VERSION ""

NS_ :

BS_:
BU_: ME SC01 BMS01 BMS PT
BO_ 1988 BMS05_DebugCMB: 8 BMS05
 SG_ cmbMultiplexor_BMS05 M : 7|8@0+ (1,0) [0|0] ""  PT
 SG_ moduleTemperature01_BMS05 m1 : 15|8@0+ (1,-40) [-40|200] "C"  PT
 SG_ brickVoltage001_BMS05 m1 : 23|16@0+ (0.0001,0) [0|6.5] "V"  PT
 SG_ brickVoltage002_BMS05 m1 : 39|16@0+ (0.0001,0) [0|6.5] "V"  PT
 SG_ brickVoltage003_BMS05 m1 : 55|16@0+ (0.0001,0) [0|6.5] "V"  PT
 SG_ moduleTemperature02_BMS05 m2 : 15|8@0+ (1,-40) [-40|200] "C"  PT
 SG_ brickVoltage004_BMS05 m2 : 23|16@0+ (0.0001,0) [0|6.5] "V"  PT
 SG_ brickVoltage005_BMS05 m2 : 39|16@0+ (0.0001,0) [0|6.5] "V"  PT
 SG_ brickVoltage006_BMS05 m2 : 55|16@0+ (0.0001,0) [0|6.5] "V"  PT
 SG_ moduleTemperature03_BMS05 m3 : 15|8@0+ (1,-40) [-40|200] "C"  PT
 SG_ brickVoltage007_BMS05 m3 : 23|16@0+ (0.0001,0) [0|6.5] "V"  PT
 SG_ brickVoltage008_BMS05 m3 : 39|16@0+ (0.0001,0) [0|6.5] "V"  PT
 SG_ brickVoltage009_BMS05 m3 : 55|16@0+ (0.0001,0) [0|6.5] "V"  PT
 SG_ moduleTemperature04_BMS05 m4 : 15|8@0+ (1,-40) [-40|200] "C"  PT
 SG_ brickVoltage010_BMS05 m4 : 23|16@0+ (0.0001,0) [0|6.5] "V"  PT
 SG_ brickVoltage011_BMS05 m4 : 39|16@0+ (0.0001,0) [0|6.5] "V"  PT
 SG_ brickVoltage012_BMS05 m4 : 55|16@0+ (0.0001,0) [0|6.5] "V"  PT
 SG_ moduleTemperature05_BMS05 m5 : 15|8@0+ (1,-40) [-40|200] "C"  PT
 SG_ brickVoltage013_BMS05 m5 : 23|16@0+ (0.0001,0) [0|6.5] "V"  PT
 SG_ brickVoltage014_BMS05 m5 : 39|16@0+ (0.0001,0) [0|6.5] "V"  PT
 SG_ brickVoltage015_BMS05 m5 : 55|16@0+ (0.0001,0) [0|6.5] "V"  PT
 SG_ moduleTemperature06_BMS05 m6 : 15|8@0+ (1,-40) [-40|200] "C"  PT
 SG_ brickVoltage016_BMS05 m6 : 23|16@0+ (0.0001,0) [0|6.5] "V"  PT
 SG_ brickVoltage017_BMS05 m6 : 39|16@0+ (0.0001,0) [0|6.5] "V"  PT
 SG_ brickVoltage018_BMS05 m6 : 55|16@0+ (0.0001,0) [0|6.5] "V"  PT
 SG_ moduleTemperature07_BMS05 m7 : 15|8@0+ (1,-40) [-40|200] "C"  PT
 SG_ brickVoltage019_BMS05 m7 : 23|16@0+ (0.0001,0) [0|6.5] "V"  PT
 SG_ brickVoltage020_BMS05 m7 : 39|16@0+ (0.0001,0) [0|6.5] "V"  PT
 SG_ brickVoltage021_BMS05 m7 : 55|16@0+ (0.0001,0) [0|6.5] "V"  PT
 SG_ moduleTemperature08_BMS05 m8 : 15|8@0+ (1,-40) [-40|200] "C"  PT
 SG_ brickVoltage022_BMS05 m8 : 23|16@0+ (0.0001,0) [0|6.5] "V"  PT
 SG_ brickVoltage023_BMS05 m8 : 39|16@0+ (0.0001,0) [0|6.5] "V"  PT
 SG_ brickVoltage024_BMS05 m8 : 55|16@0+ (0.0001,0) [0|6.5] "V"  PT
 SG_ moduleTemperature09_BMS05 m9 : 15|8@0+ (1,-40) [-40|200] "C"  PT
 SG_ brickVoltage025_BMS05 m9 : 23|16@0+ (0.0001,0) [0|6.5] "V"  PT
 SG_ brickVoltage026_BMS05 m9 : 39|16@0+ (0.0001,0) [0|6.5] "V"  PT
 SG_ brickVoltage027_BMS05 m9 : 55|16@0+ (0.0001,0) [0|6.5] "V"  PT
 SG_ moduleTemperature10_BMS05 m10 : 15|8@0+ (1,-40) [-40|200] "C"  PT
 SG_ brickVoltage028_BMS05 m10 : 23|16@0+ (0.0001,0) [0|6.5] "V"  PT
 SG_ brickVoltage029_BMS05 m10 : 39|16@0+ (0.0001,0) [0|6.5] "V"  PT
 SG_ brickVoltage030_BMS05 m10 : 55|16@0+ (0.0001,0) [0|6.5] "V"  PT
 SG_ moduleTemperature11_BMS05 m11 : 15|8@0+ (1,-40) [-40|200] "C"  PT
 SG_ brickVoltage031_BMS05 m11 : 23|16@0+ (0.0001,0) [0|6.5] "V"  PT
 SG_ brickVoltage032_BMS05 m11 : 39|16@0+ (0.0001,0) [0|6.5] "V"  PT
 SG_ brickVoltage033_BMS05 m11 : 55|16@0+ (0.0001,0) [0|6.5] "V"  PT
 SG_ moduleTemperature12_BMS05 m12 : 15|8@0+ (1,-40) [-40|200] "C"  PT
 SG_ brickVoltage034_BMS05 m12 : 23|16@0+ (0.0001,0) [0|6.5] "V"  PT
 SG_ brickVoltage035_BMS05 m12 : 39|16@0+ (0.0001,0) [0|6.5] "V"  PT
 SG_ brickVoltage036_BMS05 m12 : 55|16@0+ (0.0001,0) [0|6.5] "V"  PT
 SG_ moduleTemperature13_BMS05 m13 : 15|8@0+ (1,-40) [-40|200] "C"  PT
 SG_ brickVoltage037_BMS05 m13 : 23|16@0+ (0.0001,0) [0|6.5] "V"  PT
 SG_ brickVoltage038_BMS05 m13 : 39|16@0+ (0.0001,0) [0|6.5] "V"  PT
 SG_ brickVoltage039_BMS05 m13 : 55|16@0+ (0.0001,0) [0|6.5] "V"  PT
 SG_ moduleTemperature14_BMS05 m14 : 15|8@0+ (1,-40) [-40|200] "C"  PT
 SG_ brickVoltage040_BMS05 m14 : 23|16@0+ (0.0001,0) [0|6.5] "V"  PT
 SG_ brickVoltage041_BMS05 m14 : 39|16@0+ (0.0001,0) [0|6.5] "V"  PT
 SG_ brickVoltage042_BMS05 m14 : 55|16@0+ (0.0001,0) [0|6.5] "V"  PT
 SG_ moduleTemperature15_BMS05 m15 : 15|8@0+ (1,-40) [-40|200] "C"  PT
 SG_ brickVoltage043_BMS05 m15 : 23|16@0+ (0.0001,0) [0|6.5] "V"  PT
 SG_ brickVoltage044_BMS05 m15 : 39|16@0+ (0.0001,0) [0|6.5] "V"  PT
 SG_ brickVoltage045_BMS05 m15 : 55|16@0+ (0.0001,0) [0|6.5] "V"  PT
 SG_ moduleTemperature16_BMS05 m16 : 15|8@0+ (1,-40) [-40|200] "C"  PT
 SG_ brickVoltage046_BMS05 m16 : 23|16@0+ (0.0001,0) [0|6.5] "V"  PT
 SG_ brickVoltage047_BMS05 m16 : 39|16@0+ (0.0001,0) [0|6.5] "V"  PT
 SG_ brickVoltage048_BMS05 m16 : 55|16@0+ (0.0001,0) [0|6.5] "V"  PT
 SG_ moduleTemperature17_BMS05 m17 : 15|8@0+ (1,-40) [-40|200] "C"  PT
 SG_ brickVoltage049_BMS05 m17 : 23|16@0+ (0.0001,0) [0|6.5] "V"  PT
 SG_ brickVoltage050_BMS05 m17 : 39|16@0+ (0.0001,0) [0|6.5] "V"  PT
 SG_ brickVoltage051_BMS05 m17 : 55|16@0+ (0.0001,0) [0|6.5] "V"  PT
 SG_ moduleTemperature18_BMS05 m18 : 15|8@0+ (1,-40) [-40|200] "C"  PT
 SG_ brickVoltage052_BMS05 m18 : 23|16@0+ (0.0001,0) [0|6.5] "V"  PT
 SG_ brickVoltage053_BMS05 m18 : 39|16@0+ (0.0001,0) [0|6.5] "V"  PT
 SG_ brickVoltage054_BMS05 m18 : 55|16@0+ (0.0001,0) [0|6.5] "V"  PT
 SG_ moduleTemperature19_BMS05 m19 : 15|8@0+ (1,-40) [-40|200] "C"  PT
 SG_ brickVoltage055_BMS05 m19 : 23|16@0+ (0.0001,0) [0|6.5] "V"  PT
 SG_ brickVoltage056_BMS05 m19 : 39|16@0+ (0.0001,0) [0|6.5] "V"  PT
 SG_ brickVoltage057_BMS05 m19 : 55|16@0+ (0.0001,0) [0|6.5] "V"  PT
 SG_ moduleTemperature20_BMS05 m20 : 15|8@0+ (1,-40) [-40|200] "C"  PT
 SG_ brickVoltage058_BMS05 m20 : 23|16@0+ (0.0001,0) [0|6.5] "V"  PT
 SG_ brickVoltage059_BMS05 m20 : 39|16@0+ (0.0001,0) [0|6.5] "V"  PT
 SG_ brickVoltage060_BMS05 m20 : 55|16@0+ (0.0001,0) [0|6.5] "V"  PT
 SG_ moduleTemperature21_BMS05 m21 : 15|8@0+ (1,-40) [-40|200] "C"  PT
 SG_ brickVoltage061_BMS05 m21 : 23|16@0+ (0.0001,0) [0|6.5] "V"  PT
 SG_ brickVoltage062_BMS05 m21 : 39|16@0+ (0.0001,0) [0|6.5] "V"  PT
 SG_ brickVoltage063_BMS05 m21 : 55|16@0+ (0.0001,0) [0|6.5] "V"  PT
 SG_ moduleTemperature22_BMS05 m22 : 15|8@0+ (1,-40) [-40|200] "C"  PT
 SG_ brickVoltage064_BMS05 m22 : 23|16@0+ (0.0001,0) [0|6.5] "V"  PT
 SG_ brickVoltage065_BMS05 m22 : 39|16@0+ (0.0001,0) [0|6.5] "V"  PT
 SG_ brickVoltage066_BMS05 m22 : 55|16@0+ (0.0001,0) [0|6.5] "V"  PT
 SG_ moduleTemperature23_BMS05 m23 : 15|8@0+ (1,-40) [-40|200] "C"  PT
 SG_ brickVoltage067_BMS05 m23 : 23|16@0+ (0.0001,0) [0|6.5] "V"  PT
 SG_ brickVoltage068_BMS05 m23 : 39|16@0+ (0.0001,0) [0|6.5] "V"  PT
 SG_ brickVoltage069_BMS05 m23 : 55|16@0+ (0.0001,0) [0|6.5] "V"  PT
 SG_ moduleTemperature24_BMS05 m24 : 15|8@0+ (1,-40) [-40|200] "C"  PT
 SG_ brickVoltage070_BMS05 m24 : 23|16@0+ (0.0001,0) [0|6.5] "V"  PT
 SG_ brickVoltage071_BMS05 m24 : 39|16@0+ (0.0001,0) [0|6.5] "V"  PT
 SG_ brickVoltage072_BMS05 m24 : 55|16@0+ (0.0001,0) [0|6.5] "V"  PT
 SG_ moduleTemperature25_BMS05 m25 : 15|8@0+ (1,-40) [-40|200] "C"  PT
 SG_ brickVoltage073_BMS05 m25 : 23|16@0+ (0.0001,0) [0|6.5] "V"  PT
 SG_ brickVoltage074_BMS05 m25 : 39|16@0+ (0.0001,0) [0|6.5] "V"  PT
 SG_ brickVoltage075_BMS05 m25 : 55|16@0+ (0.0001,0) [0|6.5] "V"  PT
 SG_ moduleTemperature26_BMS05 m26 : 15|8@0+ (1,-40) [-40|200] "C"  PT
 SG_ brickVoltage076_BMS05 m26 : 23|16@0+ (0.0001,0) [0|6.5] "V"  PT
 SG_ brickVoltage077_BMS05 m26 : 39|16@0+ (0.0001,0) [0|6.5] "V"  PT
 SG_ brickVoltage078_BMS05 m26 : 55|16@0+ (0.0001,0) [0|6.5] "V"  PT
 SG_ moduleTemperature27_BMS05 m27 : 15|8@0+ (1,-40) [-40|200] "C"  PT
 SG_ brickVoltage079_BMS05 m27 : 23|16@0+ (0.0001,0) [0|6.5] "V"  PT
 SG_ brickVoltage080_BMS05 m27 : 39|16@0+ (0.0001,0) [0|6.5] "V"  PT
 SG_ brickVoltage081_BMS05 m27 : 55|16@0+ (0.0001,0) [0|6.5] "V"  PT
 SG_ moduleTemperature28_BMS05 m28 : 15|8@0+ (1,-40) [-40|200] "C"  PT
 SG_ brickVoltage082_BMS05 m28 : 23|16@0+ (0.0001,0) [0|6.5] "V"  PT
 SG_ brickVoltage083_BMS05 m28 : 39|16@0+ (0.0001,0) [0|6.5] "V"  PT
 SG_ brickVoltage084_BMS05 m28 : 55|16@0+ (0.0001,0) [0|6.5] "V"  PT
 SG_ moduleTemperature29_BMS05 m29 : 15|8@0+ (1,-40) [-40|200] "C"  PT
 SG_ brickVoltage085_BMS05 m29 : 23|16@0+ (0.0001,0) [0|6.5] "V"  PT
 SG_ brickVoltage086_BMS05 m29 : 39|16@0+ (0.0001,0) [0|6.5] "V"  PT
 SG_ brickVoltage087_BMS05 m29 : 55|16@0+ (0.0001,0) [0|6.5] "V"  PT
 SG_ moduleTemperature30_BMS05 m30 : 15|8@0+ (1,-40) [-40|200] "C"  PT
 SG_ brickVoltage088_BMS05 m30 : 23|16@0+ (0.0001,0) [0|6.5] "V"  PT
 SG_ brickVoltage089_BMS05 m30 : 39|16@0+ (0.0001,0) [0|6.5] "V"  PT
 SG_ brickVoltage090_BMS05 m30 : 55|16@0+ (0.0001,0) [0|6.5] "V"  PT
 SG_ moduleTemperature31_BMS05 m31 : 15|8@0+ (1,-40) [-40|200] "C"  PT
 SG_ brickVoltage091_BMS05 m31 : 23|16@0+ (0.0001,0) [0|6.5] "V"  PT
 SG_ brickVoltage092_BMS05 m31 : 39|16@0+ (0.0001,0) [0|6.5] "V"  PT
 SG_ brickVoltage093_BMS05 m31 : 55|16@0+ (0.0001,0) [0|6.5] "V"  PT
 SG_ moduleTemperature32_BMS05 m32 : 15|8@0+ (1,-40) [-40|200] "C"  PT
 SG_ brickVoltage094_BMS05 m32 : 23|16@0+ (0.0001,0) [0|6.5] "V"  PT
 SG_ brickVoltage095_BMS05 m32 : 39|16@0+ (0.0001,0) [0|6.5] "V"  PT
 SG_ brickVoltage096_BMS05 m32 : 55|16@0+ (0.0001,0) [0|6.5] "V"  PT
 SG_ brickVoltage097_BMS05 m33 : 23|16@0+ (0.0001,0) [0|6.5] "V"  PT
 SG_ brickVoltage098_BMS05 m33 : 39|16@0+ (0.0001,0) [0|6.5] "V"  PT
 SG_ brickVoltage099_BMS05 m33 : 55|16@0+ (0.0001,0) [0|6.5] "V"  PT
 SG_ brickVoltage100_BMS05 m34 : 23|16@0+ (0.0001,0) [0|6.5] "V"  PT
 SG_ brickVoltage101_BMS05 m34 : 39|16@0+ (0.0001,0) [0|6.5] "V"  PT
 SG_ brickVoltage102_BMS05 m34 : 55|16@0+ (0.0001,0) [0|6.5] "V"  PT
 SG_ brickVoltage103_BMS05 m35 : 23|16@0+ (0.0001,0) [0|6.5] "V"  PT
 SG_ brickVoltage104_BMS05 m35 : 39|16@0+ (0.0001,0) [0|6.5] "V"  PT
 SG_ brickVoltage105_BMS05 m35 : 55|16@0+ (0.0001,0) [0|6.5] "V"  PT
 SG_ brickVoltage106_BMS05 m36 : 23|16@0+ (0.0001,0) [0|6.5] "V"  PT
 SG_ brickVoltage107_BMS05 m36 : 39|16@0+ (0.0001,0) [0|6.5] "V"  PT
 SG_ brickVoltage108_BMS05 m36 : 55|16@0+ (0.0001,0) [0|6.5] "V"  PT
 SG_ brickVoltage109_BMS05 m37 : 23|16@0+ (0.0001,0) [0|6.5] "V"  PT
 SG_ brickVoltage110_BMS05 m37 : 39|16@0+ (0.0001,0) [0|6.5] "V"  PT
 SG_ brickVoltage111_BMS05 m37 : 55|16@0+ (0.0001,0) [0|6.5] "V"  PT
 SG_ brickVoltage112_BMS05 m38 : 23|16@0+ (0.0001,0) [0|6.5] "V"  PT
 SG_ brickVoltage113_BMS05 m38 : 39|16@0+ (0.0001,0) [0|6.5] "V"  PT
 SG_ brickVoltage114_BMS05 m38 : 55|16@0+ (0.0001,0) [0|6.5] "V"  PT
 SG_ brickVoltage115_BMS05 m39 : 23|16@0+ (0.0001,0) [0|6.5] "V"  PT
 SG_ brickVoltage116_BMS05 m39 : 39|16@0+ (0.0001,0) [0|6.5] "V"  PT
 SG_ brickVoltage117_BMS05 m39 : 55|16@0+ (0.0001,0) [0|6.5] "V"  PT
 SG_ brickVoltage118_BMS05 m40 : 23|16@0+ (0.0001,0) [0|6.5] "V"  PT
 SG_ brickVoltage119_BMS05 m40 : 39|16@0+ (0.0001,0) [0|6.5] "V"  PT
 SG_ brickVoltage120_BMS05 m40 : 55|16@0+ (0.0001,0) [0|6.5] "V"  PT
 SG_ brickVoltage121_BMS05 m41 : 23|16@0+ (0.0001,0) [0|6.5] "V"  PT
 SG_ brickVoltage122_BMS05 m41 : 39|16@0+ (0.0001,0) [0|6.5] "V"  PT
 SG_ brickVoltage123_BMS05 m41 : 55|16@0+ (0.0001,0) [0|6.5] "V"  PT
 SG_ brickVoltage124_BMS05 m42 : 23|16@0+ (0.0001,0) [0|6.5] "V"  PT
 SG_ brickVoltage125_BMS05 m42 : 39|16@0+ (0.0001,0) [0|6.5] "V"  PT
 SG_ brickVoltage126_BMS05 m42 : 55|16@0+ (0.0001,0) [0|6.5] "V"  PT
 SG_ brickVoltage127_BMS05 m43 : 23|16@0+ (0.0001,0) [0|6.5] "V"  PT
 SG_ brickVoltage128_BMS05 m43 : 39|16@0+ (0.0001,0) [0|6.5] "V"  PT
 SG_ brickVoltage129_BMS05 m43 : 55|16@0+ (0.0001,0) [0|6.5] "V"  PT
 SG_ brickVoltage130_BMS05 m44 : 23|16@0+ (0.0001,0) [0|6.5] "V"  PT
 SG_ brickVoltage131_BMS05 m44 : 39|16@0+ (0.0001,0) [0|6.5] "V"  PT
 SG_ brickVoltage132_BMS05 m44 : 55|16@0+ (0.0001,0) [0|6.5] "V"  PT
 SG_ brickVoltage133_BMS05 m45 : 23|16@0+ (0.0001,0) [0|6.5] "V"  PT
 SG_ brickVoltage134_BMS05 m45 : 39|16@0+ (0.0001,0) [0|6.5] "V"  PT
 SG_ brickVoltage135_BMS05 m45 : 55|16@0+ (0.0001,0) [0|6.5] "V"  PT
 SG_ brickVoltage136_BMS05 m46 : 23|16@0+ (0.0001,0) [0|6.5] "V"  PT
 SG_ brickVoltage137_BMS05 m46 : 39|16@0+ (0.0001,0) [0|6.5] "V"  PT
 SG_ brickVoltage138_BMS05 m46 : 55|16@0+ (0.0001,0) [0|6.5] "V"  PT
 SG_ brickVoltage139_BMS05 m47 : 23|16@0+ (0.0001,0) [0|6.5] "V"  PT
 SG_ brickVoltage140_BMS05 m47 : 39|16@0+ (0.0001,0) [0|6.5] "V"  PT
 SG_ brickVoltage141_BMS05 m47 : 55|16@0+ (0.0001,0) [0|6.5] "V"  PT
 SG_ brickVoltage142_BMS05 m48 : 23|16@0+ (0.0001,0) [0|6.5] "V"  PT
 SG_ brickVoltage143_BMS05 m48 : 39|16@0+ (0.0001,0) [0|6.5] "V"  PT
 SG_ brickVoltage144_BMS05 m48 : 55|16@0+ (0.0001,0) [0|6.5] "V"  PT
 SG_ brickVoltage145_BMS05 m49 : 23|16@0+ (0.0001,0) [0|6.5] "V"  PT
 SG_ brickVoltage146_BMS05 m49 : 39|16@0+ (0.0001,0) [0|6.5] "V"  PT
 SG_ brickVoltage147_BMS05 m49 : 55|16@0+ (0.0001,0) [0|6.5] "V"  PT
 SG_ brickVoltage148_BMS05 m50 : 23|16@0+ (0.0001,0) [0|6.5] "V"  PT
 SG_ brickVoltage149_BMS05 m50 : 39|16@0+ (0.0001,0) [0|6.5] "V"  PT
 SG_ brickVoltage150_BMS05 m50 : 55|16@0+ (0.0001,0) [0|6.5] "V"  PT
 SG_ brickVoltage151_BMS05 m51 : 23|16@0+ (0.0001,0) [0|6.5] "V"  PT
 SG_ brickVoltage152_BMS05 m51 : 39|16@0+ (0.0001,0) [0|6.5] "V"  PT
 SG_ brickVoltage153_BMS05 m51 : 55|16@0+ (0.0001,0) [0|6.5] "V"  PT
 SG_ brickVoltage154_BMS05 m52 : 23|16@0+ (0.0001,0) [0|6.5] "V"  PT
 SG_ brickVoltage155_BMS05 m52 : 39|16@0+ (0.0001,0) [0|6.5] "V"  PT
 SG_ brickVoltage156_BMS05 m52 : 55|16@0+ (0.0001,0) [0|6.5] "V"  PT
 SG_ brickVoltage157_BMS05 m53 : 23|16@0+ (0.0001,0) [0|6.5] "V"  PT
 SG_ brickVoltage158_BMS05 m53 : 39|16@0+ (0.0001,0) [0|6.5] "V"  PT
 SG_ brickVoltage159_BMS05 m53 : 55|16@0+ (0.0001,0) [0|6.5] "V"  PT
 SG_ brickVoltage160_BMS05 m54 : 23|16@0+ (0.0001,0) [0|6.5] "V"  PT
 SG_ brickVoltage161_BMS05 m54 : 39|16@0+ (0.0001,0) [0|6.5] "V"  PT
 SG_ brickVoltage162_BMS05 m54 : 55|16@0+ (0.0001,0) [0|6.5] "V"  PT
 SG_ brickVoltage163_BMS05 m55 : 23|16@0+ (0.0001,0) [0|6.5] "V"  PT
 SG_ brickVoltage164_BMS05 m55 : 39|16@0+ (0.0001,0) [0|6.5] "V"  PT
 SG_ brickVoltage165_BMS05 m55 : 55|16@0+ (0.0001,0) [0|6.5] "V"  PT
 SG_ brickVoltage166_BMS05 m56 : 23|16@0+ (0.0001,0) [0|6.5] "V"  PT
 SG_ brickVoltage167_BMS05 m56 : 39|16@0+ (0.0001,0) [0|6.5] "V"  PT
 SG_ brickVoltage168_BMS05 m56 : 55|16@0+ (0.0001,0) [0|6.5] "V"  PT
 SG_ brickVoltage169_BMS05 m57 : 23|16@0+ (0.0001,0) [0|6.5] "V"  PT
 SG_ brickVoltage170_BMS05 m57 : 39|16@0+ (0.0001,0) [0|6.5] "V"  PT
 SG_ brickVoltage171_BMS05 m57 : 55|16@0+ (0.0001,0) [0|6.5] "V"  PT
 SG_ brickVoltage172_BMS05 m58 : 23|16@0+ (0.0001,0) [0|6.5] "V"  PT
 SG_ brickVoltage173_BMS05 m58 : 39|16@0+ (0.0001,0) [0|6.5] "V"  PT
 SG_ brickVoltage174_BMS05 m58 : 55|16@0+ (0.0001,0) [0|6.5] "V"  PT
 SG_ brickVoltage175_BMS05 m59 : 23|16@0+ (0.0001,0) [0|6.5] "V"  PT
 SG_ brickVoltage176_BMS05 m59 : 39|16@0+ (0.0001,0) [0|6.5] "V"  PT
 SG_ brickVoltage177_BMS05 m59 : 55|16@0+ (0.0001,0) [0|6.5] "V"  PT
 SG_ brickVoltage178_BMS05 m60 : 23|16@0+ (0.0001,0) [0|6.5] "V"  PT
 SG_ brickVoltage179_BMS05 m60 : 39|16@0+ (0.0001,0) [0|6.5] "V"  PT
 SG_ brickVoltage180_BMS05 m60 : 55|16@0+ (0.0001,0) [0|6.5] "V"  PT
 SG_ brickVoltage181_BMS05 m61 : 23|16@0+ (0.0001,0) [0|6.5] "V"  PT
 SG_ brickVoltage182_BMS05 m61 : 39|16@0+ (0.0001,0) [0|6.5] "V"  PT
 SG_ brickVoltage183_BMS05 m61 : 55|16@0+ (0.0001,0) [0|6.5] "V"  PT
 SG_ brickVoltage184_BMS05 m62 : 23|16@0+ (0.0001,0) [0|6.5] "V"  PT
 SG_ brickVoltage185_BMS05 m62 : 39|16@0+ (0.0001,0) [0|6.5] "V"  PT
 SG_ brickVoltage186_BMS05 m62 : 55|16@0+ (0.0001,0) [0|6.5] "V"  PT
 SG_ brickVoltage187_BMS05 m63 : 23|16@0+ (0.0001,0) [0|6.5] "V"  PT
 SG_ brickVoltage188_BMS05 m63 : 39|16@0+ (0.0001,0) [0|6.5] "V"  PT
 SG_ brickVoltage189_BMS05 m63 : 55|16@0+ (0.0001,0) [0|6.5] "V"  PT
 SG_ brickVoltage190_BMS05 m64 : 23|16@0+ (0.0001,0) [0|6.5] "V"  PT
 SG_ brickVoltage191_BMS05 m64 : 39|16@0+ (0.0001,0) [0|6.5] "V"  PT
 SG_ brickVoltage192_BMS05 m64 : 55|16@0+ (0.0001,0) [0|6.5] "V"  PT
 SG_ brickVoltage193_BMS05 m65 : 23|16@0+ (0.0001,0) [0|6.5] "V"  PT
 SG_ brickVoltage194_BMS05 m65 : 39|16@0+ (0.0001,0) [0|6.5] "V"  PT
 SG_ brickVoltage195_BMS05 m65 : 55|16@0+ (0.0001,0) [0|6.5] "V"  PT
 SG_ brickVoltage196_BMS05 m66 : 23|16@0+ (0.0001,0) [0|6.5] "V"  PT
 SG_ brickVoltage197_BMS05 m66 : 39|16@0+ (0.0001,0) [0|6.5] "V"  PT
 SG_ brickVoltage198_BMS05 m66 : 55|16@0+ (0.0001,0) [0|6.5] "V"  PT
 SG_ brickVoltage199_BMS05 m67 : 23|16@0+ (0.0001,0) [0|6.5] "V"  PT
 SG_ brickVoltage200_BMS05 m67 : 39|16@0+ (0.0001,0) [0|6.5] "V"  PT
 SG_ brickVoltage201_BMS05 m67 : 55|16@0+ (0.0001,0) [0|6.5] "V"  PT
 SG_ brickVoltage202_BMS05 m68 : 23|16@0+ (0.0001,0) [0|6.5] "V"  PT
 SG_ brickVoltage203_BMS05 m68 : 39|16@0+ (0.0001,0) [0|6.5] "V"  PT
 SG_ brickVoltage204_BMS05 m68 : 55|16@0+ (0.0001,0) [0|6.5] "V"  PT
 SG_ brickVoltage205_BMS05 m69 : 23|16@0+ (0.0001,0) [0|6.5] "V"  PT
 SG_ brickVoltage206_BMS05 m69 : 39|16@0+ (0.0001,0) [0|6.5] "V"  PT
 SG_ brickVoltage207_BMS05 m69 : 55|16@0+ (0.0001,0) [0|6.5] "V"  PT
 SG_ brickVoltage208_BMS05 m70 : 23|16@0+ (0.0001,0) [0|6.5] "V"  PT
 SG_ brickVoltage209_BMS05 m70 : 39|16@0+ (0.0001,0) [0|6.5] "V"  PT
 SG_ brickVoltage210_BMS05 m70 : 55|16@0+ (0.0001,0) [0|6.5] "V"  PT
 SG_ brickVoltage211_BMS05 m71 : 23|16@0+ (0.0001,0) [0|6.5] "V"  PT
 SG_ brickVoltage212_BMS05 m71 : 39|16@0+ (0.0001,0) [0|6.5] "V"  PT
 SG_ brickVoltage213_BMS05 m71 : 55|16@0+ (0.0001,0) [0|6.5] "V"  PT
 SG_ brickVoltage214_BMS05 m72 : 23|16@0+ (0.0001,0) [0|6.5] "V"  PT
 SG_ brickVoltage215_BMS05 m72 : 39|16@0+ (0.0001,0) [0|6.5] "V"  PT
 SG_ brickVoltage216_BMS05 m72 : 55|16@0+ (0.0001,0) [0|6.5] "V"  PT
 SG_ brickVoltage217_BMS05 m73 : 23|16@0+ (0.0001,0) [0|6.5] "V"  PT
 SG_ brickVoltage218_BMS05 m73 : 39|16@0+ (0.0001,0) [0|6.5] "V"  PT
 SG_ brickVoltage219_BMS05 m73 : 55|16@0+ (0.0001,0) [0|6.5] "V"  PT
 SG_ brickVoltage220_BMS05 m74 : 23|16@0+ (0.0001,0) [0|6.5] "V"  PT
 SG_ brickVoltage221_BMS05 m74 : 39|16@0+ (0.0001,0) [0|6.5] "V"  PT
 SG_ brickVoltage222_BMS05 m74 : 55|16@0+ (0.0001,0) [0|6.5] "V"  PT
 SG_ brickVoltage223_BMS05 m75 : 23|16@0+ (0.0001,0) [0|6.5] "V"  PT
 SG_ brickVoltage224_BMS05 m75 : 39|16@0+ (0.0001,0) [0|6.5] "V"  PT
 SG_ brickVoltage225_BMS05 m75 : 55|16@0+ (0.0001,0) [0|6.5] "V"  PT
 SG_ brickVoltage226_BMS05 m76 : 23|16@0+ (0.0001,0) [0|6.5] "V"  PT
 SG_ brickVoltage227_BMS05 m76 : 39|16@0+ (0.0001,0) [0|6.5] "V"  PT
 SG_ brickVoltage228_BMS05 m76 : 55|16@0+ (0.0001,0) [0|6.5] "V"  PT
 SG_ brickVoltage229_BMS05 m77 : 23|16@0+ (0.0001,0) [0|6.5] "V"  PT
 SG_ brickVoltage230_BMS05 m77 : 39|16@0+ (0.0001,0) [0|6.5] "V"  PT
 SG_ brickVoltage231_BMS05 m77 : 55|16@0+ (0.0001,0) [0|6.5] "V"  PT
 SG_ brickVoltage232_BMS05 m78 : 23|16@0+ (0.0001,0) [0|6.5] "V"  PT
 SG_ brickVoltage233_BMS05 m78 : 39|16@0+ (0.0001,0) [0|6.5] "V"  PT
 SG_ brickVoltage234_BMS05 m78 : 55|16@0+ (0.0001,0) [0|6.5] "V"  PT
 SG_ brickVoltage235_BMS05 m79 : 23|16@0+ (0.0001,0) [0|6.5] "V"  PT
 SG_ brickVoltage236_BMS05 m79 : 39|16@0+ (0.0001,0) [0|6.5] "V"  PT
 SG_ brickVoltage237_BMS05 m79 : 55|16@0+ (0.0001,0) [0|6.5] "V"  PT
 SG_ brickVoltage238_BMS05 m80 : 23|16@0+ (0.0001,0) [0|6.5] "V"  PT
 SG_ brickVoltage239_BMS05 m80 : 39|16@0+ (0.0001,0) [0|6.5] "V"  PT
 SG_ brickVoltage240_BMS05 m80 : 55|16@0+ (0.0001,0) [0|6.5] "V"  PT
 SG_ brickVoltage241_BMS05 m81 : 23|16@0+ (0.0001,0) [0|6.5] "V"  PT
 SG_ brickVoltage242_BMS05 m81 : 39|16@0+ (0.0001,0) [0|6.5] "V"  PT
 SG_ brickVoltage243_BMS05 m81 : 55|16@0+ (0.0001,0) [0|6.5] "V"  PT
 SG_ brickVoltage244_BMS05 m82 : 23|16@0+ (0.0001,0) [0|6.5] "V"  PT
 SG_ brickVoltage245_BMS05 m82 : 39|16@0+ (0.0001,0) [0|6.5] "V"  PT
 SG_ brickVoltage246_BMS05 m82 : 55|16@0+ (0.0001,0) [0|6.5] "V"  PT
 SG_ brickVoltage247_BMS05 m83 : 23|16@0+ (0.0001,0) [0|6.5] "V"  PT
 SG_ brickVoltage248_BMS05 m83 : 39|16@0+ (0.0001,0) [0|6.5] "V"  PT
 SG_ brickVoltage249_BMS05 m83 : 55|16@0+ (0.0001,0) [0|6.5] "V"  PT
 SG_ brickVoltage250_BMS05 m84 : 23|16@0+ (0.0001,0) [0|6.5] "V"  PT
 SG_ brickVoltage251_BMS05 m84 : 39|16@0+ (0.0001,0) [0|6.5] "V"  PT
 SG_ brickVoltage252_BMS05 m84 : 55|16@0+ (0.0001,0) [0|6.5] "V"  PT
 SG_ brickVoltage253_BMS05 m85 : 23|16@0+ (0.0001,0) [0|6.5] "V"  PT
 SG_ brickVoltage254_BMS05 m85 : 39|16@0+ (0.0001,0) [0|6.5] "V"  PT
 SG_ brickVoltage255_BMS05 m85 : 55|16@0+ (0.0001,0) [0|6.5] "V"  PT
 SG_ brickVoltage256_BMS05 m86 : 23|16@0+ (0.0001,0) [0|6.5] "V"  PT
 SG_ brickVoltage257_BMS05 m86 : 39|16@0+ (0.0001,0) [0|6.5] "V"  PT
 SG_ brickVoltage258_BMS05 m86 : 55|16@0+ (0.0001,0) [0|6.5] "V"  PT
 SG_ brickVoltage259_BMS05 m87 : 23|16@0+ (0.0001,0) [0|6.5] "V"  PT
 SG_ brickVoltage260_BMS05 m87 : 39|16@0+ (0.0001,0) [0|6.5] "V"  PT
 SG_ brickVoltage261_BMS05 m87 : 55|16@0+ (0.0001,0) [0|6.5] "V"  PT
 SG_ brickVoltage262_BMS05 m88 : 23|16@0+ (0.0001,0) [0|6.5] "V"  PT
 SG_ brickVoltage263_BMS05 m88 : 39|16@0+ (0.0001,0) [0|6.5] "V"  PT
 SG_ brickVoltage264_BMS05 m88 : 55|16@0+ (0.0001,0) [0|6.5] "V"  PT
 SG_ brickVoltage265_BMS05 m89 : 23|16@0+ (0.0001,0) [0|6.5] "V"  PT
 SG_ brickVoltage266_BMS05 m89 : 39|16@0+ (0.0001,0) [0|6.5] "V"  PT
 SG_ brickVoltage267_BMS05 m89 : 55|16@0+ (0.0001,0) [0|6.5] "V"  PT
 SG_ brickVoltage268_BMS05 m90 : 23|16@0+ (0.0001,0) [0|6.5] "V"  PT
 SG_ brickVoltage269_BMS05 m90 : 39|16@0+ (0.0001,0) [0|6.5] "V"  PT
 SG_ brickVoltage270_BMS05 m90 : 55|16@0+ (0.0001,0) [0|6.5] "V"  PT
 SG_ brickVoltage271_BMS05 m91 : 23|16@0+ (0.0001,0) [0|6.5] "V"  PT
 SG_ brickVoltage272_BMS05 m91 : 39|16@0+ (0.0001,0) [0|6.5] "V"  PT
 SG_ brickVoltage273_BMS05 m91 : 55|16@0+ (0.0001,0) [0|6.5] "V"  PT
 SG_ brickVoltage274_BMS05 m92 : 23|16@0+ (0.0001,0) [0|6.5] "V"  PT
 SG_ brickVoltage275_BMS05 m92 : 39|16@0+ (0.0001,0) [0|6.5] "V"  PT
 SG_ brickVoltage276_BMS05 m92 : 55|16@0+ (0.0001,0) [0|6.5] "V"  PT
 SG_ brickVoltage277_BMS05 m93 : 23|16@0+ (0.0001,0) [0|6.5] "V"  PT
 SG_ brickVoltage278_BMS05 m93 : 39|16@0+ (0.0001,0) [0|6.5] "V"  PT
 SG_ brickVoltage279_BMS05 m93 : 55|16@0+ (0.0001,0) [0|6.5] "V"  PT
 SG_ brickVoltage280_BMS05 m94 : 23|16@0+ (0.0001,0) [0|6.5] "V"  PT
 SG_ brickVoltage281_BMS05 m94 : 39|16@0+ (0.0001,0) [0|6.5] "V"  PT
 SG_ brickVoltage282_BMS05 m94 : 55|16@0+ (0.0001,0) [0|6.5] "V"  PT
 SG_ brickVoltage283_BMS05 m95 : 23|16@0+ (0.0001,0) [0|6.5] "V"  PT
 SG_ brickVoltage284_BMS05 m95 : 39|16@0+ (0.0001,0) [0|6.5] "V"  PT
 SG_ brickVoltage285_BMS05 m95 : 55|16@0+ (0.0001,0) [0|6.5] "V"  PT
 SG_ brickVoltage286_BMS05 m96 : 23|16@0+ (0.0001,0) [0|6.5] "V"  PT
 SG_ brickVoltage287_BMS05 m96 : 39|16@0+ (0.0001,0) [0|6.5] "V"  PT
 SG_ brickVoltage288_BMS05 m96 : 55|16@0+ (0.0001,0) [0|6.5] "V"  PT
 SG_ brickVoltage289_BMS05 m97 : 23|16@0+ (0.0001,0) [0|6.5] "V"  PT
 SG_ brickVoltage290_BMS05 m97 : 39|16@0+ (0.0001,0) [0|6.5] "V"  PT
 SG_ brickVoltage291_BMS05 m97 : 55|16@0+ (0.0001,0) [0|6.5] "V"  PT
 SG_ brickVoltage292_BMS05 m98 : 23|16@0+ (0.0001,0) [0|6.5] "V"  PT
 SG_ brickVoltage293_BMS05 m98 : 39|16@0+ (0.0001,0) [0|6.5] "V"  PT
 SG_ brickVoltage294_BMS05 m98 : 55|16@0+ (0.0001,0) [0|6.5] "V"  PT
 SG_ brickVoltage295_BMS05 m99 : 23|16@0+ (0.0001,0) [0|6.5] "V"  PT
 SG_ brickVoltage296_BMS05 m99 : 39|16@0+ (0.0001,0) [0|6.5] "V"  PT
 SG_ brickVoltage297_BMS05 m99 : 55|16@0+ (0.0001,0) [0|6.5] "V"  PT
 SG_ brickVoltage298_BMS05 m100 : 23|16@0+ (0.0001,0) [0|6.5] "V"  PT
 SG_ brickVoltage299_BMS05 m100 : 39|16@0+ (0.0001,0) [0|6.5] "V"  PT
 SG_ brickVoltage300_BMS05 m100 : 55|16@0+ (0.0001,0) [0|6.5] "V"  PT
 SG_ moduleTemperature33_BMS05 m33 : 15|8@0+ (1,-40) [-40|200] "C"  PT
 SG_ moduleTemperature34_BMS05 m34 : 15|8@0+ (1,-40) [-40|200] "C"  PT
 SG_ moduleTemperature35_BMS05 m35 : 15|8@0+ (1,-40) [-40|200] "C"  PT
 SG_ moduleTemperature36_BMS05 m36 : 15|8@0+ (1,-40) [-40|200] "C"  PT
 SG_ moduleTemperature37_BMS05 m37 : 15|8@0+ (1,-40) [-40|200] "C"  PT
 SG_ moduleTemperature38_BMS05 m38 : 15|8@0+ (1,-40) [-40|200] "C"  PT
 SG_ moduleTemperature39_BMS05 m39 : 15|8@0+ (1,-40) [-40|200] "C"  PT
 SG_ moduleTemperature40_BMS05 m40 : 15|8@0+ (1,-40) [-40|200] "C"  PT
 SG_ moduleTemperature41_BMS05 m41 : 15|8@0+ (1,-40) [-40|200] "C"  PT
 SG_ moduleTemperature42_BMS05 m42 : 15|8@0+ (1,-40) [-40|200] "C"  PT
 SG_ moduleTemperature43_BMS05 m43 : 15|8@0+ (1,-40) [-40|200] "C"  PT
 SG_ moduleTemperature44_BMS05 m44 : 15|8@0+ (1,-40) [-40|200] "C"  PT
 SG_ moduleTemperature45_BMS05 m45 : 15|8@0+ (1,-40) [-40|200] "C"  PT
 SG_ moduleTemperature46_BMS05 m46 : 15|8@0+ (1,-40) [-40|200] "C"  PT
 SG_ moduleTemperature47_BMS05 m47 : 15|8@0+ (1,-40) [-40|200] "C"  PT
 SG_ moduleTemperature48_BMS05 m48 : 15|8@0+ (1,-40) [-40|200] "C"  PT
 SG_ moduleTemperature49_BMS05 m49 : 15|8@0+ (1,-40) [-40|200] "C"  PT
 SG_ moduleTemperature50_BMS05 m50 : 15|8@0+ (1,-40) [-40|200] "C"  PT
 SG_ moduleTemperature51_BMS05 m51 : 15|8@0+ (1,-40) [-40|200] "C"  PT
 SG_ moduleTemperature52_BMS05 m52 : 15|8@0+ (1,-40) [-40|200] "C"  PT
 SG_ moduleTemperature53_BMS05 m53 : 15|8@0+ (1,-40) [-40|200] "C"  PT
 SG_ moduleTemperature54_BMS05 m54 : 15|8@0+ (1,-40) [-40|200] "C"  PT
 SG_ moduleTemperature55_BMS05 m55 : 15|8@0+ (1,-40) [-40|200] "C"  PT
 SG_ moduleTemperature56_BMS05 m56 : 15|8@0+ (1,-40) [-40|200] "C"  PT
 SG_ moduleTemperature57_BMS05 m57 : 15|8@0+ (1,-40) [-40|200] "C"  PT
 SG_ moduleTemperature58_BMS05 m58 : 15|8@0+ (1,-40) [-40|200] "C"  PT
 SG_ moduleTemperature59_BMS05 m59 : 15|8@0+ (1,-40) [-40|200] "C"  PT
 SG_ moduleTemperature60_BMS05 m60 : 15|8@0+ (1,-40) [-40|200] "C"  PT
 SG_ moduleTemperature61_BMS05 m61 : 15|8@0+ (1,-40) [-40|200] "C"  PT
 SG_ moduleTemperature62_BMS05 m62 : 15|8@0+ (1,-40) [-40|200] "C"  PT
 SG_ moduleTemperature63_BMS05 m63 : 15|8@0+ (1,-40) [-40|200] "C"  PT
 SG_ moduleTemperature64_BMS05 m64 : 15|8@0+ (1,-40) [-40|200] "C"  PT
 SG_ moduleTemperature65_BMS05 m65 : 15|8@0+ (1,-40) [-40|200] "C"  PT
 SG_ moduleTemperature66_BMS05 m66 : 15|8@0+ (1,-40) [-40|200] "C"  PT
 SG_ moduleTemperature67_BMS05 m67 : 15|8@0+ (1,-40) [-40|200] "C"  PT
 SG_ moduleTemperature68_BMS05 m68 : 15|8@0+ (1,-40) [-40|200] "C"  PT
 SG_ moduleTemperature69_BMS05 m69 : 15|8@0+ (1,-40) [-40|200] "C"  PT
 SG_ moduleTemperature70_BMS05 m70 : 15|8@0+ (1,-40) [-40|200] "C"  PT
 SG_ moduleTemperature71_BMS05 m71 : 15|8@0+ (1,-40) [-40|200] "C"  PT
 SG_ moduleTemperature72_BMS05 m72 : 15|8@0+ (1,-40) [-40|200] "C"  PT
 SG_ moduleTemperature73_BMS05 m73 : 15|8@0+ (1,-40) [-40|200] "C"  PT
 SG_ moduleTemperature74_BMS05 m74 : 15|8@0+ (1,-40) [-40|200] "C"  PT
 SG_ moduleTemperature75_BMS05 m75 : 15|8@0+ (1,-40) [-40|200] "C"  PT
 SG_ moduleTemperature76_BMS05 m76 : 15|8@0+ (1,-40) [-40|200] "C"  PT
 SG_ moduleTemperature77_BMS05 m77 : 15|8@0+ (1,-40) [-40|200] "C"  PT
 SG_ moduleTemperature78_BMS05 m78 : 15|8@0+ (1,-40) [-40|200] "C"  PT
 SG_ moduleTemperature79_BMS05 m79 : 15|8@0+ (1,-40) [-40|200] "C"  PT
 SG_ moduleTemperature80_BMS05 m80 : 15|8@0+ (1,-40) [-40|200] "C"  PT
 SG_ moduleTemperature81_BMS05 m81 : 15|8@0+ (1,-40) [-40|200] "C"  PT
 SG_ moduleTemperature82_BMS05 m82 : 15|8@0+ (1,-40) [-40|200] "C"  PT
 SG_ moduleTemperature83_BMS05 m83 : 15|8@0+ (1,-40) [-40|200] "C"  PT
 SG_ moduleTemperature84_BMS05 m84 : 15|8@0+ (1,-40) [-40|200] "C"  PT
 SG_ moduleTemperature85_BMS05 m85 : 15|8@0+ (1,-40) [-40|200] "C"  PT
 SG_ moduleTemperature86_BMS05 m86 : 15|8@0+ (1,-40) [-40|200] "C"  PT
 SG_ moduleTemperature87_BMS05 m87 : 15|8@0+ (1,-40) [-40|200] "C"  PT
 SG_ moduleTemperature88_BMS05 m88 : 15|8@0+ (1,-40) [-40|200] "C"  PT
 SG_ moduleTemperature89_BMS05 m89 : 15|8@0+ (1,-40) [-40|200] "C"  PT
 SG_ moduleTemperature90_BMS05 m90 : 15|8@0+ (1,-40) [-40|200] "C"  PT
 SG_ moduleTemperature91_BMS05 m91 : 15|8@0+ (1,-40) [-40|200] "C"  PT
 SG_ moduleTemperature92_BMS05 m92 : 15|8@0+ (1,-40) [-40|200] "C"  PT
 SG_ moduleTemperature93_BMS05 m93 : 15|8@0+ (1,-40) [-40|200] "C"  PT
 SG_ moduleTemperature94_BMS05 m94 : 15|8@0+ (1,-40) [-40|200] "C"  PT
 SG_ moduleTemperature95_BMS05 m95 : 15|8@0+ (1,-40) [-40|200] "C"  PT
 SG_ moduleTemperature96_BMS05 m96 : 15|8@0+ (1,-40) [-40|200] "C"  PT
 SG_ moduleTemperature97_BMS05 m97 : 15|8@0+ (1,-40) [-40|200] "C"  PT
 SG_ moduleTemperature98_BMS05 m98 : 15|8@0+ (1,-40) [-40|200] "C"  PT
 SG_ moduleTemperature99_BMS05 m99 : 15|8@0+ (1,-40) [-40|200] "C"  PT
 SG_ moduleTemperature100_BMS05 m100 : 15|8@0+ (1,-40) [-40|200] "C"  PT
 SG_ moduleTemperature101_BMS05 m101 : 15|8@0+ (1,-40) [-40|200] "C"  PT
 SG_ moduleTemperature102_BMS05 m102 : 15|8@0+ (1,-40) [-40|200] "C"  PT
 SG_ moduleTemperature103_BMS05 m103 : 15|8@0+ (1,-40) [-40|200] "C"  PT
 SG_ moduleTemperature104_BMS05 m104 : 15|8@0+ (1,-40) [-40|200] "C"  PT
 SG_ moduleTemperature105_BMS05 m105 : 15|8@0+ (1,-40) [-40|200] "C"  PT
 SG_ moduleTemperature106_BMS05 m106 : 15|8@0+ (1,-40) [-40|200] "C"  PT
 SG_ moduleTemperature107_BMS05 m107 : 15|8@0+ (1,-40) [-40|200] "C"  PT
 SG_ moduleTemperature108_BMS05 m108 : 15|8@0+ (1,-40) [-40|200] "C"  PT
 SG_ moduleTemperature109_BMS05 m109 : 15|8@0+ (1,-40) [-40|200] "C"  PT
 SG_ moduleTemperature110_BMS05 m110 : 15|8@0+ (1,-40) [-40|200] "C"  PT
 SG_ moduleTemperature111_BMS05 m111 : 15|8@0+ (1,-40) [-40|200] "C"  PT
 SG_ moduleTemperature112_BMS05 m112 : 15|8@0+ (1,-40) [-40|200] "C"  PT
 SG_ moduleTemperature113_BMS05 m113 : 15|8@0+ (1,-40) [-40|200] "C"  PT
 SG_ moduleTemperature114_BMS05 m114 : 15|8@0+ (1,-40) [-40|200] "C"  PT
 SG_ moduleTemperature115_BMS05 m115 : 15|8@0+ (1,-40) [-40|200] "C"  PT
 SG_ moduleTemperature116_BMS05 m116 : 15|8@0+ (1,-40) [-40|200] "C"  PT
 SG_ moduleTemperature117_BMS05 m117 : 15|8@0+ (1,-40) [-40|200] "C"  PT
 SG_ moduleTemperature118_BMS05 m118 : 15|8@0+ (1,-40) [-40|200] "C"  PT
 SG_ moduleTemperature119_BMS05 m119 : 15|8@0+ (1,-40) [-40|200] "C"  PT
 SG_ moduleTemperature120_BMS05 m120 : 15|8@0+ (1,-40) [-40|200] "C"  PT
 SG_ moduleTemperature121_BMS05 m121 : 15|8@0+ (1,-40) [-40|200] "C"  PT
 SG_ moduleTemperature122_BMS05 m122 : 15|8@0+ (1,-40) [-40|200] "C"  PT
 SG_ moduleTemperature123_BMS05 m123 : 15|8@0+ (1,-40) [-40|200] "C"  PT
 SG_ moduleTemperature124_BMS05 m124 : 15|8@0+ (1,-40) [-40|200] "C"  PT
 SG_ moduleTemperature125_BMS05 m125 : 15|8@0+ (1,-40) [-40|200] "C"  PT
 SG_ moduleTemperature126_BMS05 m126 : 15|8@0+ (1,-40) [-40|200] "C"  PT
 SG_ moduleTemperature127_BMS05 m127 : 15|8@0+ (1,-40) [-40|200] "C"  PT
 SG_ moduleTemperature128_BMS05 m128 : 15|8@0+ (1,-40) [-40|200] "C"  PT
 SG_ moduleTemperature129_BMS05 m129 : 15|8@0+ (1,-40) [-40|200] "C"  PT
 SG_ moduleTemperature130_BMS05 m130 : 15|8@0+ (1,-40) [-40|200] "C"  PT
 SG_ moduleTemperature131_BMS05 m131 : 15|8@0+ (1,-40) [-40|200] "C"  PT
 SG_ moduleTemperature132_BMS05 m132 : 15|8@0+ (1,-40) [-40|200] "C"  PT
 SG_ moduleTemperature133_BMS05 m133 : 15|8@0+ (1,-40) [-40|200] "C"  PT
 SG_ moduleTemperature134_BMS05 m134 : 15|8@0+ (1,-40) [-40|200] "C"  PT
 SG_ moduleTemperature135_BMS05 m135 : 15|8@0+ (1,-40) [-40|200] "C"  PT
 SG_ moduleTemperature136_BMS05 m136 : 15|8@0+ (1,-40) [-40|200] "C"  PT
 SG_ moduleTemperature137_BMS05 m137 : 15|8@0+ (1,-40) [-40|200] "C"  PT
 SG_ moduleTemperature138_BMS05 m138 : 15|8@0+ (1,-40) [-40|200] "C"  PT
 SG_ moduleTemperature139_BMS05 m139 : 15|8@0+ (1,-40) [-40|200] "C"  PT
 SG_ moduleTemperature140_BMS05 m140 : 15|8@0+ (1,-40) [-40|200] "C"  PT
 SG_ moduleTemperature141_BMS05 m141 : 15|8@0+ (1,-40) [-40|200] "C"  PT
 SG_ moduleTemperature142_BMS05 m142 : 15|8@0+ (1,-40) [-40|200] "C"  PT
 SG_ moduleTemperature143_BMS05 m143 : 15|8@0+ (1,-40) [-40|200] "C"  PT
 SG_ moduleTemperature144_BMS05 m144 : 15|8@0+ (1,-40) [-40|200] "C"  PT
 SG_ moduleTemperature145_BMS05 m145 : 15|8@0+ (1,-40) [-40|200] "C"  PT
 SG_ moduleTemperature146_BMS05 m146 : 15|8@0+ (1,-40) [-40|200] "C"  PT
 SG_ moduleTemperature147_BMS05 m147 : 15|8@0+ (1,-40) [-40|200] "C"  PT
 SG_ moduleTemperature148_BMS05 m148 : 15|8@0+ (1,-40) [-40|200] "C"  PT
 SG_ moduleTemperature149_BMS05 m149 : 15|8@0+ (1,-40) [-40|200] "C"  PT
 SG_ moduleTemperature150_BMS05 m150 : 15|8@0+ (1,-40) [-40|200] "C"  PT
 SG_ moduleTemperature151_BMS05 m151 : 15|8@0+ (1,-40) [-40|200] "C"  PT
 SG_ moduleTemperature152_BMS05 m152 : 15|8@0+ (1,-40) [-40|200] "C"  PT
 SG_ moduleTemperature153_BMS05 m153 : 15|8@0+ (1,-40) [-40|200] "C"  PT
 SG_ moduleTemperature154_BMS05 m154 : 15|8@0+ (1,-40) [-40|200] "C"  PT
 SG_ moduleTemperature155_BMS05 m155 : 15|8@0+ (1,-40) [-40|200] "C"  PT
 SG_ moduleTemperature156_BMS05 m156 : 15|8@0+ (1,-40) [-40|200] "C"  PT
 SG_ moduleTemperature157_BMS05 m157 : 15|8@0+ (1,-40) [-40|200] "C"  PT
 SG_ moduleTemperature158_BMS05 m158 : 15|8@0+ (1,-40) [-40|200] "C"  PT
 SG_ moduleTemperature159_BMS05 m159 : 15|8@0+ (1,-40) [-40|200] "C"  PT
 SG_ moduleTemperature160_BMS05 m160 : 15|8@0+ (1,-40) [-40|200] "C"  PT
 SG_ moduleTemperature161_BMS05 m161 : 15|8@0+ (1,-40) [-40|200] "C"  PT
 SG_ moduleTemperature162_BMS05 m162 : 15|8@0+ (1,-40) [-40|200] "C"  PT
 SG_ moduleTemperature163_BMS05 m163 : 15|8@0+ (1,-40) [-40|200] "C"  PT
 SG_ moduleTemperature164_BMS05 m164 : 15|8@0+ (1,-40) [-40|200] "C"  PT
 SG_ moduleTemperature165_BMS05 m165 : 15|8@0+ (1,-40) [-40|200] "C"  PT
 SG_ moduleTemperature166_BMS05 m166 : 15|8@0+ (1,-40) [-40|200] "C"  PT
 SG_ moduleTemperature167_BMS05 m167 : 15|8@0+ (1,-40) [-40|200] "C"  PT
 SG_ moduleTemperature168_BMS05 m168 : 15|8@0+ (1,-40) [-40|200] "C"  PT
 SG_ moduleTemperature169_BMS05 m169 : 15|8@0+ (1,-40) [-40|200] "C"  PT
 SG_ moduleTemperature170_BMS05 m170 : 15|8@0+ (1,-40) [-40|200] "C"  PT
 SG_ moduleTemperature171_BMS05 m171 : 15|8@0+ (1,-40) [-40|200] "C"  PT
 SG_ moduleTemperature172_BMS05 m172 : 15|8@0+ (1,-40) [-40|200] "C"  PT
 SG_ moduleTemperature173_BMS05 m173 : 15|8@0+ (1,-40) [-40|200] "C"  PT
 SG_ moduleTemperature174_BMS05 m174 : 15|8@0+ (1,-40) [-40|200] "C"  PT
 SG_ moduleTemperature175_BMS05 m175 : 15|8@0+ (1,-40) [-40|200] "C"  PT
 SG_ moduleTemperature176_BMS05 m176 : 15|8@0+ (1,-40) [-40|200] "C"  PT
 SG_ moduleTemperature177_BMS05 m177 : 15|8@0+ (1,-40) [-40|200] "C"  PT
 SG_ moduleTemperature178_BMS05 m178 : 15|8@0+ (1,-40) [-40|200] "C"  PT
 SG_ moduleTemperature179_BMS05 m179 : 15|8@0+ (1,-40) [-40|200] "C"  PT
 SG_ moduleTemperature180_BMS05 m180 : 15|8@0+ (1,-40) [-40|200] "C"  PT
 SG_ moduleTemperature181_BMS05 m181 : 15|8@0+ (1,-40) [-40|200] "C"  PT
 SG_ moduleTemperature182_BMS05 m182 : 15|8@0+ (1,-40) [-40|200] "C"  PT
 SG_ moduleTemperature183_BMS05 m183 : 15|8@0+ (1,-40) [-40|200] "C"  PT
 SG_ moduleTemperature184_BMS05 m184 : 15|8@0+ (1,-40) [-40|200] "C"  PT
 SG_ moduleTemperature185_BMS05 m185 : 15|8@0+ (1,-40) [-40|200] "C"  PT
 SG_ moduleTemperature186_BMS05 m186 : 15|8@0+ (1,-40) [-40|200] "C"  PT
 SG_ moduleTemperature187_BMS05 m187 : 15|8@0+ (1,-40) [-40|200] "C"  PT
 SG_ moduleTemperature188_BMS05 m188 : 15|8@0+ (1,-40) [-40|200] "C"  PT
 SG_ moduleTemperature189_BMS05 m189 : 15|8@0+ (1,-40) [-40|200] "C"  PT
 SG_ moduleTemperature190_BMS05 m190 : 15|8@0+ (1,-40) [-40|200] "C"  PT
 SG_ moduleTemperature191_BMS05 m191 : 15|8@0+ (1,-40) [-40|200] "C"  PT
 SG_ moduleTemperature192_BMS05 m192 : 15|8@0+ (1,-40) [-40|200] "C"  PT

BO_ 901 BMS06_DebugEventMap10: 8 BMS06
 SG_ DEM319_HV_DISABLE_DURING_S_BMS06 : 55|2@0+ (1,0) [0|3] ""  PT
 SG_ DEM318_HV_ENABLE_IMPLAUSIB_BMS06 : 53|2@0+ (1,0) [0|3] ""  PT
 SG_ DEM317_STRING_SUSPECT_OPEN_BMS06 : 51|2@0+ (1,0) [0|3] ""  PT
 SG_ DEM316_UNEXPCTD_BMS_ON_CAN_BMS06 : 49|2@0+ (1,0) [0|3] ""  PT
 SG_ DEM315_HV_WITHSTAND_TESTS__BMS06 : 63|2@0+ (1,0) [0|3] ""  PT
 SG_ DEM314_OBC_PILOT_ERROR_BMS06 : 61|2@0+ (1,0) [0|3] ""  PT
 SG_ DEM313_OBC_PILOT_HIGH_BMS06 : 59|2@0+ (1,0) [0|3] ""  PT
 SG_ DEM312_OBC_PROXIMITY_ERROR_BMS06 : 57|2@0+ (1,0) [0|3] ""  PT
 SG_ DEM311_CTRS_END_OF_LIFE_WA_BMS06 : 39|2@0+ (1,0) [0|3] ""  PT
 SG_ DEM310_BMSMIA_STRNGMSTR_AL_BMS06 : 37|2@0+ (1,0) [0|3] ""  PT
 SG_ DEM309_VOLTAGE_BRICKOV_WAR_BMS06 : 35|2@0+ (1,0) [0|3] ""  PT
 SG_ DEM308_PRESSURE_FLT_BMS06 : 33|2@0+ (1,0) [0|3] ""  PT
 SG_ DEM307_PRESSURE_MIA_BMS06 : 47|2@0+ (1,0) [0|3] ""  PT
 SG_ DEM306_SW_VERSION_MISMATCH_BMS06 : 45|2@0+ (1,0) [0|3] ""  PT
 SG_ DEM305_MODULET_OVERTEMP_WA_BMS06 : 43|2@0+ (1,0) [0|3] ""  PT
 SG_ DEM304_PCHG_OPENCIRCUIT_IN_BMS06 : 41|2@0+ (1,0) [0|3] ""  PT
 SG_ DEM303_MODULET_UNDERTEMP_W_BMS06 : 23|2@0+ (1,0) [0|3] ""  PT
 SG_ DEM302_MODULET_UT_BMS06 : 21|2@0+ (1,0) [0|3] ""  PT
 SG_ DEM301_FUSI_LOCK_BMS06 : 19|2@0+ (1,0) [0|3] ""  PT
 SG_ DEM300_DEBUG_SM_DISABLED_BMS06 : 17|2@0+ (1,0) [0|3] ""  PT
 SG_ DEM299_5V_SENSOR_SUPPLY_OU_BMS06 : 31|2@0+ (1,0) [0|3] ""  PT
 SG_ DEM298_IMPL_DRIVE_REQUEST_BMS06 : 29|2@0+ (1,0) [0|0] ""  PT
 SG_ DEM297_PCHG2_OPENCIRCUIT_BMS06 : 27|2@0+ (1,0) [0|0] ""  PT
 SG_ DEM296_CTRSAUX_IMPLAUSIBLE_BMS06 : 25|2@0+ (1,0) [0|0] ""  PT
 SG_ DEM295_CTRSAUX_LINKV_UNSAF_BMS06 : 7|2@0+ (1,0) [0|0] ""  PT
 SG_ DEM294_CANRX_PT_EMERGENCY_BMS06 : 5|2@0+ (1,0) [0|0] ""  PT
 SG_ DEM293_SBC_LDT_IMPLAUSIBLE_BMS06 : 3|2@0+ (1,0) [0|0] ""  PT
 SG_ DEM292_NUM_EXPECTED_STRING_BMS06 : 1|2@0+ (1,0) [0|0] ""  PT
 SG_ DEM291_NUM_EXPECTED_STRING_BMS06 : 15|2@0+ (1,0) [0|0] ""  PT
 SG_ DEM290_CMB_ONBOARD_DEFECT_BMS06 : 13|2@0+ (1,0) [0|0] ""  PT
 SG_ DEM289_TEMP_STATE_LATCHED_BMS06 : 11|2@0+ (1,0) [0|0] ""  PT
 SG_ DEM288_CURR_STATE_LATCHED_BMS06 : 9|2@0+ (1,0) [0|0] ""  PT

BO_ 965 BMS06_DebugSlowMpex2: 8 BMS06
 SG_ balancingInDriveTimer_BMS06 m18 : 15|16@0+ (1,0) [0|65535] "s"  PT
 SG_ SOCRestPolarization_BMS06 m11 : 63|8@0+ (0.002,0) [0|0.51] "V"  PT
 SG_ CoolantSensorState_BMS06 m1 : 51|2@0+ (1,0) [0|1] ""  PT
 SG_ temperatureModelOffset_BMS06 m7 : 15|8@0+ (0.1,0) [0|25.5] "C"  PT
 SG_ SOHCMinBrickHighEst_BMS06 m4 : 15|8@0+ (0.3,50) [50|126.5] "PCT"  PT
 SG_ SOHCMaxBrickHighEst_BMS06 m6 : 15|8@0+ (0.3,50) [50|126.5] "PCT"  PT
 SG_ regenCurrOpLkyBktThrs1_BMS06 m17 : 63|8@0+ (0.5,0) [0|127.5] "PCT"  PT
 SG_ dischargeCurrOpLkyBktThrs1_BMS06 m10 : 15|8@0+ (0.5,0) [0|127.5] "PCT"  PT
 SG_ regenCurrentOpLoadValue_BMS06 m16 : 15|8@0+ (0.5,0) [0|127.5] "PCT"  PT
 SG_ dischargeCurrOpLoadValue_BMS06 m15 : 15|8@0+ (0.5,0) [0|127.5] "PCT"  PT
 SG_ minBrickVoltageLimit_BMS06 m16 : 55|16@0+ (0.0001,0) [0|6.5535] "V"  PT
 SG_ SOHSuitableOCVRecal_BMS06 m1 : 49|1@0+ (1,0) [0|1] ""  PT
 SG_ currentModule3Integral_BMS06 m17 : 47|16@0+ (100,-3200000) [-3200000|3353500] "As"  PT
 SG_ currentModule2Integral_BMS06 m17 : 31|16@0+ (100,-3200000) [-3200000|3353500] "As"  PT
 SG_ currentModule1Integral_BMS06 m17 : 15|16@0+ (100,-3200000) [-3200000|3353500] "As"  PT
 SG_ currentModuleMin_BMS06 m16 : 23|16@0+ (0.1,-3200) [-3200|3200] "A"  PT
 SG_ currentModuleMax_BMS06 m16 : 39|16@0+ (0.1,-3200) [-3200|3200] "A"  PT
 SG_ maxBrickVoltageSync_BMS06 m9 : 39|16@0+ (0.0001,0) [0|6.5] "V"  PT
 SG_ minBrickVoltageSync_BMS06 m9 : 55|16@0+ (0.0001,0) [0|6.5] "V"  PT
 SG_ SOHCMinBrickLowEst_BMS06 m8 : 15|8@0+ (0.3,50) [50|126.5] "PCT"  PT
 SG_ SOHCMaxBrickLowEst_BMS06 m9 : 15|8@0+ (0.3,50) [50|126.5] "PCT"  PT
 SG_ gradLimSOC_BMS06 m10 : 39|16@0+ (0.002,0) [0|131.07] "PCT"  PT
 SG_ SOCRecalSlowOp_BMS06 m14 : 55|16@0+ (0.0001,-2) [-2|4.5535] "V"  PT
 SG_ SOHCMinIndex_BMS06 m12 : 39|16@0+ (1,0) [0|65535] ""  PT
 SG_ SOHCMaxIndex_BMS06 m12 : 55|16@0+ (1,0) [0|65535] ""  PT
 SG_ SOHRMinRegen_BMS06 m11 : 39|8@0+ (1,50) [50|305] "PCT"  PT
 SG_ SOHRMinDchg_BMS06 m11 : 15|8@0+ (1,50) [50|305] "PCT"  PT
 SG_ SOHRMeanRegen_BMS06 m11 : 47|8@0+ (1,50) [50|305] "PCT"  PT
 SG_ SOHRMeanDchg_BMS06 m11 : 23|8@0+ (1,50) [50|305] "PCT"  PT
 SG_ SOHRMaxRegen_BMS06 m11 : 55|8@0+ (1,50) [50|305] "PCT"  PT
 SG_ SOHRMaxDchg_BMS06 m11 : 31|8@0+ (1,50) [50|305] "PCT"  PT
 SG_ SOHCMin_BMS06 m12 : 15|8@0+ (0.3,50) [50|126.5] "PCT"  PT
 SG_ SOHCMean_BMS06 m12 : 23|8@0+ (0.3,50) [50|126.5] "PCT"  PT
 SG_ SOHCMax_BMS06 m12 : 31|8@0+ (0.3,50) [50|126.5] "PCT"  PT
 SG_ ppRegenCurrLimitPredShort_BMS06 m6 : 23|8@0+ (2,0) [0|510] "A"  PT
 SG_ ppRegenCurrLimitPredLong_BMS06 m6 : 31|8@0+ (2,0) [0|510] "A"  PT
 SG_ ppDchgCurrLimitPredShort_BMS06 m13 : 55|8@0+ (2,-510) [-510|0] "A"  PT
 SG_ ppDchgCurrLimitPredLong_BMS06 m13 : 63|8@0+ (2,-510) [-510|0] "A"  PT
 SG_ ppInconsistentPol_BMS06 m1 : 48|1@0+ (1,0) [0|0] ""  PT
 SG_ ppPolarizationV_BMS06 m3 : 55|16@0+ (0.0001,-3) [-3|3.5535] "V"  PT
 SG_ SOCRecalMinOCVEst_BMS06 m13 : 39|16@0+ (0.0001,0) [0|6.5535] "V"  PT
 SG_ SOCRecalMaxOCVEst_BMS06 m14 : 39|16@0+ (0.0001,0) [0|6.5535] "V"  PT
 SG_ SOCRecalMinSOCUpp_BMS06 m13 : 31|8@0+ (0.5,0) [0|127.5] "PCT"  PT
 SG_ SOCRecalMinSOCLow_BMS06 m13 : 15|8@0+ (0.5,0) [0|127.5] "PCT"  PT
 SG_ SOCRecalMinSOC_BMS06 m13 : 23|8@0+ (0.5,0) [0|127.5] "PCT"  PT
 SG_ SOCRecalMaxSOCUpp_BMS06 m14 : 31|8@0+ (0.5,0) [0|127.5] "PCT"  PT
 SG_ SOCRecalMaxSOCLow_BMS06 m14 : 15|8@0+ (0.5,0) [0|127.5] "PCT"  PT
 SG_ SOCRecalMaxSOC_BMS06 m14 : 23|8@0+ (0.5,0) [0|127.5] "PCT"  PT
 SG_ ppNewtonRootInRangeRegen_BMS06 m5 : 12|1@0+ (1,0) [0|0] ""  PT
 SG_ ppNewtonRootInRangeDchg_BMS06 m5 : 8|1@0+ (1,0) [0|0] ""  PT
 SG_ ppNewtonStepsRegen_BMS06 m5 : 15|3@0+ (1,0) [0|1] ""  PT
 SG_ ppNewtonStepsDchg_BMS06 m5 : 11|3@0+ (1,0) [0|1] ""  PT
 SG_ ppNewtonRegenVRes_BMS06 m5 : 31|8@0+ (0.001,-0.1) [-0.1|0.155] "V"  PT
 SG_ ppNewtonDchgVRes_BMS06 m5 : 23|8@0+ (0.001,-0.1) [-0.1|0.155] "V"  PT
 SG_ ppMinModelAlphaTarget_BMS06 m3 : 15|8@0+ (0.02,0) [0|5.1] ""  PT
 SG_ ppMaxModelAlphaTarget_BMS06 m1 : 63|8@0+ (0.02,0) [0|5.1] ""  PT
 SG_ ppLearningTauRegen_BMS06 m2 : 55|16@0+ (0.2,0) [0|0] "s"  PT
 SG_ ppLearningCriterionDyn_BMS06 m2 : 15|8@0+ (0.005,0) [0|0] ""  PT
 SG_ ppLearningCriterionAbs_BMS06 m1 : 15|8@0+ (0.005,0) [0|0] ""  PT
 SG_ ppLearningCriterionJoin_BMS06 m0 : 15|8@0+ (0.005,0) [0|0] ""  PT
 SG_ ppMaxModelMeasV_BMS06 m7 : 23|16@0+ (0.0001,0) [0|6.5535] "V"  PT
 SG_ currentRedundant_BMS06 m15 : 23|16@0+ (0.1,-3200) [-3200|3200] "A"  PT
 SG_ currentModule3_BMS06 m10 : 55|16@0+ (0.1,-3200) [-3200|3200] "A"  PT
 SG_ currentModule2_BMS06 m10 : 23|16@0+ (0.1,-3200) [-3200|3200] "A"  PT
 SG_ currentModule1_BMS06 m9 : 23|16@0+ (0.1,-3200) [-3200|3200] "A"  PT
 SG_ ppMeanRegenIntRes_BMS06 m6 : 55|16@0+ (0.01,0) [0|655.35] "mOhm"  PT
 SG_ ppMeanDchgIntRes_BMS06 m6 : 39|16@0+ (0.01,0) [0|655.35] "mOhm"  PT
 SG_ ppMinModelVoltageIndex_BMS06 m5 : 39|16@0+ (1,0) [0|65535] ""  PT
 SG_ ppMinModelLowpassV_BMS06 m4 : 55|16@0+ (0.0001,0) [0|0] "V"  PT
 SG_ ppMaxModelVoltageIndex_BMS06 m5 : 55|16@0+ (1,0) [0|65535] ""  PT
 SG_ ppMaxModelLowpassV_BMS06 m7 : 55|16@0+ (0.0001,0) [0|0] "V"  PT
 SG_ ppLearningTauDischarge_BMS06 m0 : 55|16@0+ (0.2,0) [0|0] "s"  PT
 SG_ ppMaxRegenAlpha_BMS06 m15 : 39|16@0+ (0.0001,0) [0|6.5535] ""  PT
 SG_ ppMaxModelledV_BMS06 m7 : 39|16@0+ (0.0001,0) [0|6.5535] "V"  PT
 SG_ ppMinDchgAlpha_BMS06 m15 : 55|16@0+ (0.0001,0) [0|6.5535] ""  PT
 SG_ ppMinModelledV_BMS06 m4 : 39|16@0+ (0.0001,0) [0|6.5535] "V"  PT
 SG_ ppMinModelMeasV_BMS06 m4 : 23|16@0+ (0.0001,0) [0|6.5535] "V"  PT
 SG_ debugSlowMpex2_BMS06 M : 7|8@0+ (1,0) [0|0] ""  PT
 SG_ ppRegenCurrPredShort_BMS06 m2 : 23|16@0+ (0.02,0) [0|1310.7] "A"  PT
 SG_ ppDischgCurrPredLong_BMS06 m0 : 39|16@0+ (0.05,-3200) [-3200|0] "A"  PT
 SG_ ppDischgCurrPredShort_BMS06 m0 : 23|16@0+ (0.05,-3200) [-3200|0] "A"  PT
 SG_ ppRegenCurrPredLong_BMS06 m2 : 39|16@0+ (0.02,0) [0|1310.7] "A"  PT
 SG_ ppRegenVPredShort_BMS06 m3 : 23|16@0+ (0.02,0) [0|1310.7] "V"  PT
 SG_ ppDischgVPredShort_BMS06 m1 : 23|16@0+ (0.02,0) [0|1310.7] "V"  PT
 SG_ ppRegenVPredLong_BMS06 m3 : 39|16@0+ (0.02,0) [0|1310.7] "V"  PT
 SG_ ppDischgVPredLong_BMS06 m1 : 39|16@0+ (0.02,0) [0|1310.7] "V"  PT
 SG_ SOHDeltaSOCCoulomb_BMS06 m8 : 23|16@0+ (0.005,-150) [-150|177.675] "PCT"  PT
 SG_ SOHAbsDeltaSOCCoulomb_BMS06 m8 : 39|16@0+ (0.05,0) [0|3276.75] "PCT"  PT
 SG_ SOHLastOCVRecalMinSOC_BMS06 m8 : 55|8@0+ (0.393,0) [0|100.215] "PCT"  PT
 SG_ SOHbalancingTimeMinSOH_BMS06 m8 : 63|8@0+ (1,0) [0|255] "Min"  PT

BO_ 1797 BMS06_DebugFastMpex2: 8 BMS06
 SG_ chargerDCOutV_BMS06 m1 : 55|16@0+ (0.04,-1250) [-1250|1250] "V"  PT
 SG_ DIGIO_CHARGERCC_BMS06 m1 : 10|1@0+ (1,0) [0|0] ""  PT
 SG_ chargerProximity_BMS06 m1 : 23|8@0+ (0.02,0) [0|12] "V"  PT
 SG_ chargerPilot_BMS06 m1 : 31|8@0+ (0.05,0) [0|12.75] "V"  PT
 SG_ chargerCurrAvail_BMS06 m1 : 39|8@0+ (0.5,0) [0|127.5] "A"  PT
 SG_ chargerCtrOn_BMS06 m1 : 8|1@0+ (1,0) [0|0] ""  PT
 SG_ chargerOn_BMS06 m1 : 9|1@0+ (1,0) [0|0] ""  PT
 SG_ debugFastMpex2_BMS06 M : 7|8@0+ (1,0) [0|0] ""  PT
 SG_ posPackDbg_BMS06 m0 : 39|16@0+ (0.04,-1250) [-1250|1250] "V"  PT
 SG_ negPackDbg_BMS06 m0 : 55|16@0+ (0.04,-1250) [-1250|1250] "V"  PT
 SG_ packVoltageHVMeas_BMS06 m0 : 23|16@0+ (0.04,-1250) [-1250|1250] "V"  PT

BO_ 1861 BMS06_DebugSlowMpex1: 8 BMS06
 SG_ SOHRecentChange_BMS06 m43 : 15|8@0+ (0.1,-15) [-15|10.5] ""  PT
 SG_ SOHConvergenceIndicator_BMS06 m43 : 31|8@0+ (1,0) [0|255] ""  PT
 SG_ SOHConvergenceCounter_BMS06 m43 : 39|8@0+ (0.024,3) [0|6] ""  PT
 SG_ SOHMinFiltered_BMS06 m43 : 23|8@0+ (0.3,50) [50|126.5] "PCT"  PT
 SG_ prechargeCyMatchWaitTime_BMS06 m43 : 47|16@0+ (1,0) [0|65535] "ms"  PT
 SG_ medianModuleTempGrp2_BMS06 m13 : 63|8@0+ (1,-40) [-40|200] "C"  PT
 SG_ medianModuleTempGrp1_BMS06 m13 : 55|8@0+ (1,-40) [-40|200] "C"  PT
 SG_ coolantWarningtAlert_BMS06 m12 : 49|2@0+ (1,0) [0|3] ""  PT
 SG_ coolantFaultAlert_BMS06 m12 : 51|2@0+ (1,0) [0|3] ""  PT
 SG_ hvilShutdownStrategy_BMS06 m42 : 63|8@0+ (1,0) [0|255] ""  PT
 SG_ J1939_nmState m12 : 55|4@0+ (1,0) [0|0] ""  PT
 SG_ PrechargeXCapMin_BMS06 m42 : 47|16@0+ (0.01,0) [0|1] "mF"  PT
 SG_ LimpHomeTimeOut_BMS06 m42 : 15|32@0+ (1,0) [0|4294967295] "ms"  PT
 SG_ hvWithstandTests_BMS06 m40 : 15|8@0+ (1,0) [0|255] ""  PT
 SG_ aux3prechargeState_BMS06 m41 : 19|4@0+ (1,0) [0|0] ""  PT
 SG_ aux2prechargeState_BMS06 m41 : 31|4@0+ (1,0) [0|0] ""  PT
 SG_ aux1prechargeState_BMS06 m41 : 27|4@0+ (1,0) [0|0] ""  PT
 SG_ auxLinkVoltage_BMS06 m40 : 23|16@0+ (0.02,0) [0|1310.7] "V"  PT
 SG_ invalidModuleVoltageFlags_BMS06 m41 : 39|32@0+ (1,0) [0|0] ""  PT
 SG_ invalidModuleTempFlags_BMS06 m40 : 39|32@0+ (1,0) [0|0] ""  PT
 SG_ pumpSpeedExpected_BMS06 m30 : 15|8@0+ (0.4,0) [0|102] "%"  PT
 SG_ rangeRequestIgnoreVehicle m28 : 55|4@0+ (1,0) [0|65535] ""  PT
 SG_ rangeRequestEepromValue m28 : 63|4@0+ (1,0) [0|65535] ""  PT
 SG_ pressure2_BMS06 m35 : 31|8@0+ (0.4,0) [0|19] "psi"  PT
 SG_ calibration_version_BMS06 m37 : 63|8@0+ (1,0) [0|0] ""  PT
 SG_ currentLowTimer_BMS06 m39 : 55|16@0+ (1,0) [0|65535] "s"  PT
 SG_ auxCntrrOpenUnderLoadCntr_BMS06 m39 : 39|16@0+ (1,0) [0|0] ""  PT
 SG_ rabbitContactorState_BMS06 m34 : 31|8@0+ (1,0) [0|255] ""  PT
 SG_ analogIsenseSupplyCurr_BMS06 m37 : 55|8@0+ (0.04,0) [0|10] "A"  PT
 SG_ pumpSpeedReqCoolPrfmc_BMS06 m29 : 15|8@0+ (1,0) [0|0] "PCT"  PT
 SG_ microsarOs_IdleTask_OsCr0_BMS06 m39 : 23|8@0+ (1,0) [0|100] "PCT"  PT
 SG_ microsarOs_BswTask_BMS06 m39 : 15|8@0+ (1,0) [0|100] "PCT"  PT
 SG_ microsarOs_InitTask_BMS06 m39 : 31|8@0+ (1,0) [0|100] "PCT"  PT
 SG_ microsarOs_ApplTask_1Hz_BMS06 m38 : 63|8@0+ (1,0) [0|100] "PCT"  PT
 SG_ microsarOs_ApplTask_10Hz_BMS06 m38 : 55|8@0+ (1,0) [0|100] "PCT"  PT
 SG_ microsarOs_ApplTask_100Hz_BMS06 m38 : 47|8@0+ (1,0) [0|100] "PCT"  PT
 SG_ microsarOs_ApplLowTask_BMS06 m38 : 39|8@0+ (1,0) [0|100] "PCT"  PT
 SG_ microsarOs_ApplLateInit_BMS06 m38 : 31|8@0+ (1,0) [0|100] "PCT"  PT
 SG_ microsarOs_ApplHighTask_BMS06 m38 : 23|8@0+ (1,0) [0|100] "PCT"  PT
 SG_ microsarOs_ApplEarlyInit_BMS06 m38 : 15|8@0+ (1,0) [0|100] "PCT"  PT
 SG_ pumpRecoveryAttempts_BMS06 m31 : 15|8@0+ (1,0) [0|0] ""  PT
 SG_ appTaskBSWMaxDuration_BMS06 m37 : 47|8@0+ (0.5,0) [0|100] "PCT"  PT
 SG_ appTaskApplHighMaxDuration_BMS06 m37 : 15|16@0+ (0.5,0) [0|100] "PCT"  PT
 SG_ appTask1HzMaxDuration_BMS06 m36 : 63|8@0+ (0.5,0) [0|100] "PCT"  PT
 SG_ appTask100HzMaxDuration_BMS06 m36 : 47|8@0+ (0.5,0) [0|100] "PCT"  PT
 SG_ appTask10HzMaxDuration_BMS06 m36 : 55|8@0+ (0.5,0) [0|100] "PCT"  PT
 SG_ appTask100HzDuration_BMS06 m36 : 15|8@0+ (0.5,0) [0|100] "PCT"  PT
 SG_ appTask10HzDuration_BMS06 m36 : 23|8@0+ (0.5,0) [0|100] "PCT"  PT
 SG_ appTask1HzDuration_BMS06 m36 : 31|8@0+ (0.5,0) [0|100] "PCT"  PT
 SG_ appTaskBSWDuration_BMS06 m36 : 39|8@0+ (0.5,0) [0|100] "PCT"  PT
 SG_ appTaskApplHighDuration_BMS06 m37 : 31|16@0+ (0.5,0) [0|100] "PCT"  PT
 SG_ iumprMaxRatioDTCId_BMS06 m35 : 15|8@0+ (1,0) [0|0] ""  PT
 SG_ iumprMaxRatio_BMS06 m35 : 23|8@0+ (1,0) [0|0] ""  PT
 SG_ iumprMinRatioDTCId_BMS06 m33 : 63|8@0+ (1,0) [0|0] ""  PT
 SG_ iumprMinRatio_BMS06 m33 : 55|8@0+ (1,0) [0|0] ""  PT
 SG_ eepromWriteCyclesMax_BMS06 m11 : 55|16@0+ (64,0) [0|0] ""  PT
 SG_ eepromWriteCyclesUds_BMS06 m10 : 55|8@0+ (1,0) [0|0] ""  PT
 SG_ eepromWriteCyclesStat_BMS06 m10 : 63|8@0+ (1,0) [0|0] ""  PT
 SG_ eepromWriteCyclesSoh_BMS06 m11 : 47|8@0+ (1,0) [0|0] ""  PT
 SG_ fluidLvlCount_BMS06 m34 : 15|8@0+ (1,0) [0|255] ""  PT
 SG_ fluidLvlSensr2_BMS06 m34 : 19|2@0+ (1,0) [0|0] ""  PT
 SG_ fluidLvlSensr1_BMS06 m34 : 17|2@0+ (1,0) [0|0] ""  PT
 SG_ pumpSpeedReqVhcleSpeed_BMS06 m2 : 15|8@0+ (1,0) [0|0] "PCT"  PT
 SG_ appTaskBSWCpuUsage_BMS06 m18 : 15|8@0+ (0.5,0) [0|100] "PCT"  PT
 SG_ appTask200HzCpuUsage_BMS06 m17 : 15|8@0+ (0.5,0) [0|100] "PCT"  PT
 SG_ SWVersionBL_BMS06 m34 : 39|32@0+ (1,0) [0|4294967295] ""  PT
 SG_ SWVersionApp_BMS06 m35 : 39|32@0+ (1,0) [0|4294967295] ""  PT
 SG_ hvSNACounter_BMS06 m31 : 23|16@0+ (1,0) [0|0] ""  PT
 SG_ pyroState_BMS06 m28 : 59|4@0+ (1,0) [0|0] ""  PT
 SG_ ecuSerialNrChar15_BMS06 m33 : 47|8@0+ (1,0) [0|0] ""  PT
 SG_ ecuSerialNrChar14_BMS06 m33 : 39|8@0+ (1,0) [0|0] ""  PT
 SG_ ecuSerialNrChar13_BMS06 m33 : 31|8@0+ (1,0) [0|0] ""  PT
 SG_ ecuSerialNrChar12_BMS06 m33 : 23|8@0+ (1,0) [0|0] ""  PT
 SG_ ecuSerialNrChar11_BMS06 m32 : 63|8@0+ (1,0) [0|0] ""  PT
 SG_ ecuSerialNrChar10_BMS06 m32 : 55|8@0+ (1,0) [0|0] ""  PT
 SG_ ecuSerialNrChar09_BMS06 m32 : 47|8@0+ (1,0) [0|0] ""  PT
 SG_ ecuSerialNrChar08_BMS06 m32 : 39|8@0+ (1,0) [0|0] ""  PT
 SG_ ecuSerialNrChar07_BMS06 m32 : 31|8@0+ (1,0) [0|0] ""  PT
 SG_ ecuSerialNrChar06_BMS06 m32 : 23|8@0+ (1,0) [0|0] ""  PT
 SG_ ecuSerialNrChar05_BMS06 m32 : 15|8@0+ (1,0) [0|0] ""  PT
 SG_ analogGPIO1Current_BMS06 m22 : 39|8@0+ (0.015,0) [0|3.825] "A"  PT
 SG_ analogGPIO1Volt_BMS06 m22 : 55|8@0+ (0.1,0) [0|25] "V"  PT
 SG_ analogGPIO2Current_BMS06 m22 : 47|8@0+ (0.015,0) [0|3.825] "A"  PT
 SG_ analogGPIO2Volt_BMS06 m22 : 63|8@0+ (0.1,0) [0|25] "V"  PT
 SG_ pumpSpeedReqLoadValue_BMS06 m22 : 15|8@0+ (1,0) [0|0] "PCT"  PT
 SG_ ssaRTYear_BMS06 m31 : 55|16@0+ (1,0) [0|0] "yyyy"  PT
 SG_ ssaRTMonth_BMS06 m31 : 47|8@0+ (1,0) [0|0] "mm"  PT
 SG_ ssaRTDay_BMS06 m31 : 39|8@0+ (1,0) [0|0] "dd"  PT
 SG_ ssaTimeMRealTimeOffset_BMS06 m30 : 23|48@0+ (1,0) [0|0] ""  PT
 SG_ ssaTimeMTickCount_BMS06 m29 : 23|48@0+ (1,0) [0|0] ""  PT
 SG_ appTask50HzStackUsage_BMS06 m24 : 15|8@0+ (0.5,0) [0|100] "PCT"  PT
 SG_ OBDMILRequested_BMS06 m28 : 49|2@0+ (1,0) [0|3] ""  PT
 SG_ OBDConfirmedDTCsCount_BMS06 m28 : 15|8@0+ (1,0) [0|255] ""  PT
 SG_ OBDFirstConfirmedDTC_BMS06 m28 : 31|8@0+ (1,0) [0|255] ""  PT
 SG_ OBDFirstConfDTCWarmCyc_BMS06 m28 : 47|6@0+ (1,0) [0|63] ""  PT
 SG_ OBDPermanentDTCCount_BMS06 m28 : 23|8@0+ (1,0) [0|255] ""  PT
 SG_ OBDFirstPermanentDTC_BMS06 m28 : 39|8@0+ (1,0) [0|255] ""  PT
 SG_ OBDFirstPermDTCDriveCyc_BMS06 m28 : 41|2@0+ (1,0) [0|3] ""  PT
 SG_ nmStartupReason_BMS06 m16 : 15|4@0+ (1,0) [0|0] ""  PT
 SG_ SOCdynamicRecal_BMS06 m10 : 19|1@0+ (1,0) [0|1] ""  PT
 SG_ SOCuserSOCInit_BMS06 m10 : 18|1@0+ (1,0) [0|1] ""  PT
 SG_ contactorType_BMS06 m25 : 11|4@0+ (1,0) [0|0] ""  PT
 SG_ activeIsoTestDuration_BMS06 m13 : 15|8@0+ (200,0) [0|51000] "ms"  PT
 SG_ balancingState_BMS06 m16 : 11|4@0+ (1,0) [0|0] ""  PT
 SG_ storCondSysNwOk_BMS06 m27 : 25|1@0+ (1,0) [0|0] ""  PT
 SG_ storCondSysPwrOk_BMS06 m27 : 26|1@0+ (1,0) [0|0] ""  PT
 SG_ storCondECUOk_BMS06 m27 : 24|1@0+ (1,0) [0|0] ""  PT
 SG_ chronoStackWrCnt_BMS06 m27 : 39|32@0+ (1,0) [0|0] ""  PT
 SG_ wakeReason_BMS06 m10 : 15|4@0+ (1,0) [0|0] ""  PT
 SG_ cntrUnderLoadOpenCntr7_BMS06 m26 : 63|8@0+ (1,0) [0|0] ""  PT
 SG_ cntrUnderLoadOpenCntr6_BMS06 m26 : 55|8@0+ (1,0) [0|0] ""  PT
 SG_ cntrUnderLoadOpenCntr5_BMS06 m26 : 47|8@0+ (1,0) [0|0] ""  PT
 SG_ cntrUnderLoadOpenCntr4_BMS06 m26 : 39|8@0+ (1,0) [0|0] ""  PT
 SG_ cntrUnderLoadOpenCntr3_BMS06 m26 : 31|8@0+ (1,0) [0|0] ""  PT
 SG_ cntrUnderLoadOpenCntr2_BMS06 m26 : 23|8@0+ (1,0) [0|0] ""  PT
 SG_ cntrUnderLoadOpenCntr1_BMS06 m26 : 15|8@0+ (1,0) [0|0] ""  PT
 SG_ coolantOutletTemperature_BMS06 m27 : 23|8@0+ (1,-40) [-40|215] "C"  PT
 SG_ coolantInletTemperature_BMS06 m27 : 15|8@0+ (1,-40) [-40|215] "C"  PT
 SG_ prchgResHeatModel_BMS06 m3 : 55|16@0+ (0.1,0) [0|0] "Ws"  PT
 SG_ variantCodingCount_BMS06 m7 : 15|8@0+ (1,0) [0|0] ""  PT
 SG_ SWVersionCusApp_BMS06 m7 : 39|32@0+ (1,0) [0|0] ""  PT
 SG_ contactorOpenRequest_BMS06 m25 : 15|4@0+ (1,0) [0|0] ""  PT
 SG_ maxBrickVoltageChargeLimit_BMS06 m25 : 23|16@0+ (0.0001,0) [0|6.5] "V"  PT
 SG_ desiccantTimer_BMS06 m25 : 39|32@0+ (1,0) [0|0] "s"  PT
 SG_ batSwitchOpenReason_BMS06 m4 : 55|16@0+ (1,0) [0|0] ""  PT
 SG_ balancingTime_BMS06 m24 : 55|16@0+ (1,0) [0|65535] ""  PT
 SG_ bmsIsESSMaster_BMS06 m6 : 14|1@0+ (1,0) [0|0] ""  PT
 SG_ ecuSerialNrChar01_BMS06 m12 : 23|8@0+ (1,0) [0|0] ""  PT
 SG_ ecuSerialNrChar02_BMS06 m12 : 31|8@0+ (1,0) [0|0] ""  PT
 SG_ ecuSerialNrChar03_BMS06 m12 : 39|8@0+ (1,0) [0|0] ""  PT
 SG_ ecuSerialNrChar04_BMS06 m12 : 47|8@0+ (1,0) [0|0] ""  PT
 SG_ ecuSerialNrChar16_BMS06 m13 : 23|8@0+ (1,0) [0|0] ""  PT
 SG_ ecuSerialNrChar17_BMS06 m13 : 31|8@0+ (1,0) [0|0] ""  PT
 SG_ ecuSerialNrChar18_BMS06 m13 : 39|8@0+ (1,0) [0|0] ""  PT
 SG_ ecuSerialNrChar19_BMS06 m13 : 47|8@0+ (1,0) [0|0] ""  PT
 SG_ maxModuleTemperature_BMS06 m5 : 63|8@0+ (1,-40) [-40|200] "C"  PT
 SG_ meanModuleTemperature_BMS06 m8 : 15|8@0+ (1,-40) [-40|200] "C"  PT
 SG_ minModuleTemperature_BMS06 m5 : 55|8@0+ (1,-40) [-40|200] "C"  PT
 SG_ currentEventsShrt_BMS06 m6 : 15|1@0+ (1,0) [0|0] ""  PT
 SG_ nmOperationalMode_BMS06 m1 : 13|2@0+ (1,0) [0|0] ""  PT
 SG_ nmNetworkMode_BMS06 m1 : 15|2@0+ (1,0) [0|0] ""  PT
 SG_ nmNetworkState_BMS06 m1 : 11|1@0+ (1,0) [0|0] ""  PT
 SG_ ecuState_BMS06 m1 : 10|3@0+ (1,0) [0|7] ""  PT
 SG_ SPIRxTxDiag_BMS06 m10 : 11|4@0+ (2,0) [0|30] ""  PT
 SG_ minSOC_BMS06 m24 : 23|16@0+ (0.01,0) [0|100] "PCT"  PT
 SG_ maxSOC_BMS06 m24 : 39|16@0+ (0.01,0) [0|100] "PCT"  PT
 SG_ appTaskMaxCpuUsage_BMS06 m23 : 63|8@0+ (0.5,0) [0|100] "PCT"  PT
 SG_ appTaskCpuUsage_BMS06 m23 : 55|8@0+ (0.5,0) [0|100] "PCT"  PT
 SG_ appTask50HzCpuUsage_BMS06 m23 : 47|8@0+ (0.5,0) [0|100] "PCT"  PT
 SG_ appTask10HzStackUsage_BMS06 m23 : 39|8@0+ (0.5,0) [0|100] "PCT"  PT
 SG_ appTask100HzCpuUsage_BMS06 m23 : 31|8@0+ (0.5,0) [0|100] "PCT"  PT
 SG_ appTask10HzCpuUsage_BMS06 m23 : 23|8@0+ (0.5,0) [0|100] "PCT"  PT
 SG_ appTask1HzCpuUsage_BMS06 m23 : 15|8@0+ (0.5,0) [0|100] "PCT"  PT
 SG_ pumpSpeedReq_BMS06 m12 : 15|8@0+ (1,0) [0|0] "PCT"  PT
 SG_ numberOfStrings_BMS06 m4 : 15|5@0+ (1,0) [0|0] ""  PT
 SG_ hvComponentOpLimit_BMS06 m22 : 23|16@0+ (0.05,0) [0|3276.75] "A"  PT
 SG_ regenCurrPredBrickVOffset_BMS06 m5 : 15|8@0+ (0.5,0) [0|127.5] "A"  PT
 SG_ dischgCurrPredBrickVOffset_BMS06 m3 : 15|8@0+ (0.5,0) [0|127.5] "A"  PT
 SG_ PCANBusOffState_BMS06 m6 : 11|2@0+ (1,0) [0|0] ""  PT
 SG_ SCANBusOffState_BMS06 m6 : 13|2@0+ (1,0) [0|0] ""  PT
 SG_ PTCANBusOffState_BMS06 m6 : 9|2@0+ (1,0) [0|0] ""  PT
 SG_ eepromWriteCyclesSoc_BMS06 m11 : 39|8@0+ (1,0) [0|0] ""  PT
 SG_ eepromWriteCyclesDiag_BMS06 m11 : 31|8@0+ (1,0) [0|0] ""  PT
 SG_ eepromWriteCyclesChrono_BMS06 m10 : 39|8@0+ (1,0) [0|0] ""  PT
 SG_ eepromWriteCyclesCust_BMS06 m10 : 47|8@0+ (1,0) [0|0] ""  PT
 SG_ customerModelVsYear_BMS06 m14 : 23|8@0+ (1,0) [0|0] ""  PT
 SG_ customerModelVsWeek_BMS06 m14 : 31|8@0+ (1,0) [0|0] ""  PT
 SG_ customerModelVsCellType_BMS06 m14 : 15|1@0+ (1,0) [0|0] ""  PT
 SG_ customerModelVsCellGen_BMS06 m14 : 14|7@0+ (1,0) [0|0] ""  PT
 SG_ SWVersion_BMS06 m14 : 39|32@0+ (1,0) [0|4294967295] ""  PT
 SG_ balancingRequest288_to_295_BMS06 m21 : 63|8@0+ (1,0) [0|0] ""  PT
 SG_ balancingRequest296_to_303_BMS06 m21 : 55|8@0+ (1,0) [0|0] ""  PT
 SG_ balancingRequest304_to_311_BMS06 m21 : 47|8@0+ (1,0) [0|0] ""  PT
 SG_ balancingRequest312_to_319_BMS06 m21 : 39|8@0+ (1,0) [0|0] ""  PT
 SG_ balancingRequest320_to_327_BMS06 m21 : 31|8@0+ (1,0) [0|0] ""  PT
 SG_ balancingRequest328_to_335_BMS06 m21 : 23|8@0+ (1,0) [0|0] ""  PT
 SG_ balancingRequest240_to_247_BMS06 m20 : 63|8@0+ (1,0) [0|0] ""  PT
 SG_ balancingRequest248_to_255_BMS06 m20 : 55|8@0+ (1,0) [0|0] ""  PT
 SG_ balancingRequest256_to_263_BMS06 m20 : 47|8@0+ (1,0) [0|0] ""  PT
 SG_ balancingRequest264_to_271_BMS06 m20 : 39|8@0+ (1,0) [0|0] ""  PT
 SG_ balancingRequest272_to_279_BMS06 m20 : 31|8@0+ (1,0) [0|0] ""  PT
 SG_ balancingRequest280_to_287_BMS06 m20 : 23|8@0+ (1,0) [0|0] ""  PT
 SG_ balancingRequest192_to_199_BMS06 m19 : 63|8@0+ (1,0) [0|0] ""  PT
 SG_ balancingRequest200_to_207_BMS06 m19 : 55|8@0+ (1,0) [0|0] ""  PT
 SG_ balancingRequest208_to_215_BMS06 m19 : 47|8@0+ (1,0) [0|0] ""  PT
 SG_ balancingRequest216_to_223_BMS06 m19 : 39|8@0+ (1,0) [0|0] ""  PT
 SG_ balancingRequest224_to_231_BMS06 m19 : 31|8@0+ (1,0) [0|0] ""  PT
 SG_ balancingRequest232_to_239_BMS06 m19 : 23|8@0+ (1,0) [0|0] ""  PT
 SG_ balancingRequest144_to_151_BMS06 m18 : 63|8@0+ (1,0) [0|0] ""  PT
 SG_ balancingRequest152_to_159_BMS06 m18 : 55|8@0+ (1,0) [0|0] ""  PT
 SG_ balancingRequest160_to_167_BMS06 m18 : 47|8@0+ (1,0) [0|0] ""  PT
 SG_ balancingRequest168_to_175_BMS06 m18 : 39|8@0+ (1,0) [0|0] ""  PT
 SG_ balancingRequest176_to_183_BMS06 m18 : 31|8@0+ (1,0) [0|0] ""  PT
 SG_ balancingRequest184_to_191_BMS06 m18 : 23|8@0+ (1,0) [0|0] ""  PT
 SG_ balancingRequest096_to_103_BMS06 m17 : 63|8@0+ (1,0) [0|0] ""  PT
 SG_ balancingRequest104_to_111_BMS06 m17 : 55|8@0+ (1,0) [0|0] ""  PT
 SG_ balancingRequest112_to_119_BMS06 m17 : 47|8@0+ (1,0) [0|0] ""  PT
 SG_ balancingRequest120_to_127_BMS06 m17 : 39|8@0+ (1,0) [0|0] ""  PT
 SG_ balancingRequest128_to_135_BMS06 m17 : 31|8@0+ (1,0) [0|0] ""  PT
 SG_ balancingRequest136_to_143_BMS06 m17 : 23|8@0+ (1,0) [0|0] ""  PT
 SG_ balancingRequest048_to_055_BMS06 m16 : 63|8@0+ (1,0) [0|0] ""  PT
 SG_ balancingRequest056_to_063_BMS06 m16 : 55|8@0+ (1,0) [0|0] ""  PT
 SG_ balancingRequest064_to_071_BMS06 m16 : 47|8@0+ (1,0) [0|0] ""  PT
 SG_ balancingRequest072_to_079_BMS06 m16 : 39|8@0+ (1,0) [0|0] ""  PT
 SG_ balancingRequest080_to_087_BMS06 m16 : 31|8@0+ (1,0) [0|0] ""  PT
 SG_ balancingRequest088_to_095_BMS06 m16 : 23|8@0+ (1,0) [0|0] ""  PT
 SG_ balancingRequest000_to_007_BMS06 m15 : 63|8@0+ (1,0) [0|0] ""  PT
 SG_ balancingRequest008_to_015_BMS06 m15 : 55|8@0+ (1,0) [0|0] ""  PT
 SG_ balancingRequest016_to_023_BMS06 m15 : 47|8@0+ (1,0) [0|0] ""  PT
 SG_ balancingRequest024_to_031_BMS06 m15 : 39|8@0+ (1,0) [0|0] ""  PT
 SG_ balancingRequest032_to_039_BMS06 m15 : 31|8@0+ (1,0) [0|0] ""  PT
 SG_ balancingRequest040_to_047_BMS06 m15 : 23|8@0+ (1,0) [0|0] ""  PT
 SG_ balancingVoltageTarget_BMS06 m15 : 15|8@0+ (0.02,0) [0|5.1] ""  PT
 SG_ numberOfPacksPerString_BMS06 m4 : 10|3@0+ (1,0) [0|0] ""  PT
 SG_ analogAddr5_BMS06 m1 : 23|8@0+ (0.05,0) [0|12] "V"  PT
 SG_ analogAddr0_BMS06 m1 : 63|8@0+ (0.05,0) [0|12] "V"  PT
 SG_ analogAddr4_BMS06 m1 : 31|8@0+ (0.05,0) [0|12] "V"  PT
 SG_ analogAddr3_BMS06 m1 : 39|8@0+ (0.05,0) [0|12] "V"  PT
 SG_ analogAddr2_BMS06 m1 : 47|8@0+ (0.05,0) [0|12] "V"  PT
 SG_ analogAddr1_BMS06 m1 : 55|8@0+ (0.05,0) [0|12] "V"  PT
 SG_ debugSlowMpex1_BMS06 M : 7|8@0+ (1,0) [0|0] ""  PT
 SG_ analog3V3DSupply_BMS06 m9 : 15|8@0+ (0.015,0) [0|0] "V"  PT
 SG_ pressure_BMS06 m9 : 63|8@0+ (0.4,0) [0|19] "psi"  PT
 SG_ analog3P3VA_BMS06 m9 : 55|8@0+ (0.015,0) [0|3.825] "V"  PT
 SG_ analog5VA_BMS06 m9 : 31|8@0+ (0.025,0) [0|6] "V"  PT
 SG_ analog5VD_BMS06 m9 : 23|8@0+ (0.025,0) [0|6] "V"  PT
 SG_ analog5VSensorSupply_BMS06 m9 : 47|8@0+ (0.025,0) [0|6.375] "V"  PT
 SG_ analog6V5_BMS06 m9 : 39|8@0+ (0.0075,5) [5|6.9125] "V"  PT
 SG_ isolationResistanceIntern_BMS06 m8 : 55|16@0+ (2,0) [0|130000] "kOhm"  PT
 SG_ isolationResistanceExtern_BMS06 m8 : 39|16@0+ (2,0) [0|130000] "kOhm"  PT
 SG_ linkVoltage_BMS06 m8 : 23|16@0+ (0.02,0) [0|1310.7] "V"  PT
 SG_ eepromWriteCyclesBasics_BMS06 m11 : 23|8@0+ (1,0) [0|0] ""  PT
 SG_ eepromBlockIndex_BMS06 m11 : 15|8@0+ (1,0) [0|0] ""  PT
 SG_ CAN1MIATimerISR_BMS06 m7 : 23|8@0+ (1,0) [0|255] ""  PT
 SG_ CAN2MIATimerISR_BMS06 m7 : 31|8@0+ (1,0) [0|255] ""  PT
 SG_ regenCurrentOpLimit_BMS06 m5 : 39|16@0+ (0.05,0) [0|3200] "A"  PT
 SG_ regenCurrentErrorLimit_BMS06 m5 : 23|16@0+ (0.05,0) [0|3200] "A"  PT
 SG_ lifetime_BMS06 m6 : 39|32@0+ (1,0) [0|0] "s"  PT
 SG_ eepromReadTime_BMS06 m0 : 15|8@0+ (10,0) [0|2550] "ms"  PT
 SG_ chargerCurrentOpLimit_BMS06 m4 : 39|16@0+ (0.05,0) [0|3200] "A"  PT
 SG_ dischargeCurrentOpLimit_BMS06 m3 : 39|16@0+ (0.05,-3200) [-3200|0] "A"  PT
 SG_ chargerCurrentErrorLimit_BMS06 m4 : 23|16@0+ (0.05,0) [0|3200] "A"  PT
 SG_ dischargeCurrentErrorLimit_BMS06 m3 : 23|16@0+ (0.05,-3200) [-3200|0] "A"  PT
 SG_ pumpSpeedReqMaxT_BMS06 m2 : 23|8@0+ (1,0) [0|0] "PCT"  PT
 SG_ pumpSpeedReqDeltaT_BMS06 m2 : 31|8@0+ (1,0) [0|0] "PCT"  PT
 SG_ energyThroughput_BMS06 m2 : 39|32@0+ (0.001,0) [0|4294967.295] "kWh"  PT
 SG_ packVoltageCMB_BMS06 m6 : 23|16@0+ (0.02,0) [0|1200] "V"  PT
 SG_ ctrOffTimeLast_BMS06 m0 : 23|16@0+ (1,0) [0|0] "s"  PT
 SG_ ctrOffTime_BMS06 m0 : 39|16@0+ (1,0) [0|0] "s"  PT
 SG_ sleepTime_BMS06 m0 : 55|16@0+ (1,0) [0|0] "s"  PT
 SG_ SPIRxTxTimeAllPckts_BMS06 m10 : 31|8@0+ (2,0) [0|500] "ms"  PT
 SG_ isolationTestState_BMS06 m10 : 17|2@0+ (1,0) [0|0] ""  PT
 SG_ SOCvoltageInit_BMS06 m10 : 21|1@0+ (1,0) [0|1] ""  PT
 SG_ SOCocvInit_BMS06 m10 : 23|1@0+ (1,0) [0|1] ""  PT
 SG_ SOCeepromInit_BMS06 m10 : 22|1@0+ (1,0) [0|1] ""  PT
 SG_ SOCdefaultInit_BMS06 m10 : 20|1@0+ (1,0) [0|1] ""  PT

BO_ 1733 BMS06_DebugFastMpex1: 8 BMS06
 SG_ SPIRxTxHeaderMux3Status_BMS06 m1 : 23|1@0+ (1,0) [0|1] ""  PT
 SG_ SPIRxTxHeaderMux2Status_BMS06 m1 : 22|1@0+ (1,0) [0|1] ""  PT
 SG_ SPIRxTxHeaderMux1Status_BMS06 m1 : 21|1@0+ (1,0) [0|1] ""  PT
 SG_ SPIRxTxHeaderMux0Status_BMS06 m1 : 20|1@0+ (1,0) [0|1] ""  PT
 SG_ activeIsoTestPsbl_BMS06 m0 : 27|1@0+ (1,0) [0|0] ""  PT
 SG_ activeIsoState_BMS06 m3 : 15|8@0+ (1,0) [0|0] ""  PT
 SG_ activeIsoNegLink_BMS06 m3 : 39|16@0+ (0.04,-1250) [-1250|1371.4] "V"  PT
 SG_ activeIsoPosLink_BMS06 m3 : 23|16@0+ (0.04,-1250) [-1250|1371.4] "V"  PT
 SG_ activeIsoTestStateTimer_BMS06 m2 : 15|8@0+ (200,0) [0|51000] "ms"  PT
 SG_ activeIsoPosBuffer_BMS06 m2 : 23|16@0+ (0.04,-1250) [-1250|1371.4] "V"  PT
 SG_ activeIsoNegBuffer_BMS06 m2 : 39|16@0+ (0.04,-1250) [-1250|1371.4] "V"  PT
 SG_ activeIsoResRaw_BMS06 m2 : 55|16@0+ (2,0) [0|130000] "kOhm"  PT
 SG_ activeIsoResFilter_BMS06 m3 : 55|16@0+ (2,0) [0|130000] "kOhm"  PT
 SG_ contactorStateAux_BMS06 m1 : 34|3@0+ (1,0) [0|0] ""  PT
 SG_ batSwitchOpenReqEssMstr_BMS06 m0 : 35|2@0+ (1,0) [0|0] ""  PT
 SG_ packShutdownTarget_BMS06 m1 : 12|2@0+ (1,0) [0|0] ""  PT
 SG_ weldedState_BMS06 m1 : 39|2@0+ (1,0) [0|0] ""  PT
 SG_ DIGIO_GPIO2_ON_BMS06 m1 : 19|1@0+ (1,0) [0|0] ""  PT
 SG_ DIGIO_GPIO1_ON_BMS06 m1 : 18|1@0+ (1,0) [0|0] ""  PT
 SG_ DIGIO_12VCURR_SENSE_ON_BMS06 m1 : 37|1@0+ (1,0) [0|0] ""  PT
 SG_ DIGIO_PSUP_SAFETY_OK_BMS06 m1 : 17|1@0+ (1,0) [0|0] ""  PT
 SG_ contactorStateRq_BMS06 m1 : 36|2@0+ (1,0) [0|0] ""  PT
 SG_ contactorPwrOkToPrechg_BMS06 m1 : 16|1@0+ (1,0) [0|0] ""  PT
 SG_ strMstrStrPrechgState_BMS06 m1 : 58|3@0+ (1,0) [0|0] ""  PT
 SG_ packShutdwnTmrQual_BMS06 m1 : 27|1@0+ (1,0) [0|0] ""  PT
 SG_ packStateRequest_BMS06 m1 : 15|3@0+ (1,0) [0|0] ""  PT
 SG_ packState_BMS06 m1 : 31|4@0+ (1,0) [0|0] ""  PT
 SG_ SPIRxTxTimer_BMS06 m1 : 47|8@0+ (2,0) [0|500] "ms"  PT
 SG_ moduleTMinMaxMeanQual_BMS06 m1 : 26|1@0+ (1,0) [0|0] ""  PT
 SG_ currentQual_BMS06 m1 : 25|1@0+ (1,0) [0|0] ""  PT
 SG_ brickVMinMaxMeanQual_BMS06 m1 : 24|1@0+ (1,0) [0|0] ""  PT
 SG_ negCtr1OnReqASW_BMS06 m1 : 8|1@0+ (1,0) [0|0] ""  PT
 SG_ prechgCtr1OnReqASW_BMS06 m1 : 9|1@0+ (1,0) [0|0] ""  PT
 SG_ posCtr1OnReqASW_BMS06 m1 : 10|1@0+ (1,0) [0|0] ""  PT
 SG_ DIGIO_CNTR_HISIDE_ON_MC_BMS06 m0 : 38|1@0+ (1,0) [0|0] ""  PT
 SG_ DIGIO_CNTR_HISIDE_ON_CHCKD_BMS06 m0 : 37|1@0+ (1,0) [0|0] ""  PT
 SG_ DIGIO_CNTR_CLOSE_OK_CHCKD_BMS06 m0 : 36|1@0+ (1,0) [0|0] ""  PT
 SG_ debugFastMpex1_BMS06 M : 7|8@0+ (1,0) [0|0] ""  PT
 SG_ stateContactorControl_BMS06 m0 : 41|1@0+ (1,0) [0|0] ""  PT
 SG_ stateVoltage_BMS06 m0 : 43|1@0+ (1,0) [0|0] ""  PT
 SG_ stateTemperature_BMS06 m0 : 44|1@0+ (1,0) [0|0] ""  PT
 SG_ stateSelfTest_BMS06 m0 : 45|1@0+ (1,0) [0|0] ""  PT
 SG_ stateHVIL_BMS06 m0 : 46|1@0+ (1,0) [0|0] ""  PT
 SG_ stateCurrent_BMS06 m0 : 47|1@0+ (1,0) [0|0] ""  PT
 SG_ stateCrash_BMS06 m0 : 42|1@0+ (1,0) [0|0] ""  PT
 SG_ stateContactors_BMS06 m0 : 40|1@0+ (1,0) [0|0] ""  PT
 SG_ stateCANRx_BMS06 m0 : 39|1@0+ (1,0) [0|0] ""  PT
 SG_ itemState_BMS06 m0 : 33|2@0+ (1,0) [0|0] ""  PT
 SG_ negLink_BMS06 m0 : 23|8@0+ (10,-1200) [-1200|1350] "V"  PT
 SG_ posLink_BMS06 m0 : 15|8@0+ (10,-1200) [-1200|1350] "V"  PT
 SG_ negPack_BMS06 m0 : 63|8@0+ (10,-1200) [-1200|1350] "V"  PT
 SG_ posPack_BMS06 m0 : 55|8@0+ (10,-1200) [-1200|1350] "V"  PT
 SG_ prechargeState_BMS06 m0 : 31|4@0+ (1,0) [0|0] ""  PT
 SG_ contactorState_BMS06 m0 : 26|3@0+ (1,0) [0|0] ""  PT
 SG_ diagStandbyImmShutdown_BMS06 m1 : 61|1@0+ (1,0) [0|1] ""  PT
 SG_ diagAllOffRequired_BMS06 m1 : 60|1@0+ (1,0) [0|1] ""  PT
 SG_ diagDriveTransitionNotOK_BMS06 m1 : 55|1@0+ (1,0) [0|1] ""  PT
 SG_ diagDriveImmShutdown_BMS06 m1 : 54|1@0+ (1,0) [0|1] ""  PT
 SG_ diagDriveDelShutdown2_BMS06 m1 : 52|1@0+ (1,0) [0|1] ""  PT
 SG_ diagDriveDelShutdown1_BMS06 m1 : 53|1@0+ (1,0) [0|1] ""  PT
 SG_ diagUnused_BMS06 m1 : 59|1@0+ (1,0) [0|1] ""  PT
 SG_ diagChargeTransitionNotOK_BMS06 m1 : 51|1@0+ (1,0) [0|1] ""  PT
 SG_ diagChargeImmShutdown_BMS06 m1 : 50|1@0+ (1,0) [0|1] ""  PT
 SG_ diagAccDelShutdown1_BMS06 m1 : 62|1@0+ (1,0) [0|1] ""  PT
 SG_ diagChargeDelShutdown1_BMS06 m1 : 49|1@0+ (1,0) [0|1] ""  PT
 SG_ diagAccTransitionNotOK_BMS06 m1 : 48|1@0+ (1,0) [0|1] ""  PT
 SG_ diagAccImmShutdown_BMS06 m1 : 63|1@0+ (1,0) [0|1] ""  PT

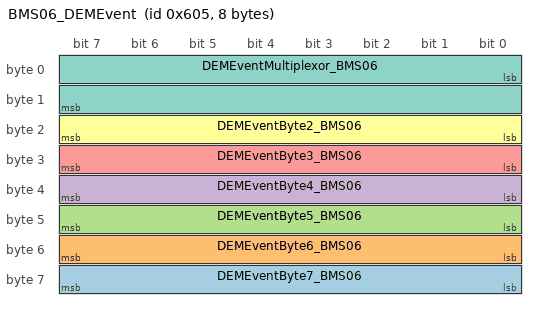
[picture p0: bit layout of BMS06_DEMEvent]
BO_ 1541 BMS06_DEMEvent: 8 BMS06
 SG_ DEMEventByte7_BMS06 : 63|8@0+ (1,0) [0|0] ""  PT
 SG_ DEMEventByte6_BMS06 : 55|8@0+ (1,0) [0|0] ""  PT
 SG_ DEMEventByte5_BMS06 : 47|8@0+ (1,0) [0|0] ""  PT
 SG_ DEMEventByte4_BMS06 : 39|8@0+ (1,0) [0|0] ""  PT
 SG_ DEMEventByte3_BMS06 : 31|8@0+ (1,0) [0|0] ""  PT
 SG_ DEMEventByte2_BMS06 : 23|8@0+ (1,0) [0|0] ""  PT
 SG_ DEMEventMultiplexor_BMS06 M : 0|16@1+ (1,0) [0|0] ""  PT

BO_ 1029 BMS06_DebugEventMap1: 8 BMS06
 SG_ DEM001_POWERUP_BMS06 : 11|2@0+ (1,0) [0|0] ""  PT
 SG_ DEM002_VOLTAGE_BRICK_OV_BMS06 : 13|2@0+ (1,0) [0|0] ""  PT
 SG_ DEM003_VOLTAGE_BRICK_UV_BMS06 : 15|2@0+ (1,0) [0|0] ""  PT
 SG_ DEM004_VOLTAGE_BRICK_SNA_BMS06 : 1|2@0+ (1,0) [0|0] ""  PT
 SG_ DEM005_VOLTAGE_BRICK_IMBAL_BMS06 : 3|2@0+ (1,0) [0|0] ""  PT
 SG_ DEM006_VOLTAGE_CAPCY_IMBAL_BMS06 : 5|2@0+ (1,0) [0|0] ""  PT
 SG_ DEM007_MODULET_HIGH_DELTA_BMS06 : 7|2@0+ (1,0) [0|0] ""  PT
 SG_ DEM008_VOLTAGE_PACK_UV_BMS06 : 25|2@0+ (1,0) [0|0] ""  PT
 SG_ DEM009_VOLTAGE_PACK_OV_BMS06 : 27|2@0+ (1,0) [0|0] ""  PT
 SG_ DEM010_VOLTAGE_PACK_PLAUSI_BMS06 : 29|2@0+ (1,0) [0|0] ""  PT
 SG_ DEM011_VOLTAGE_PCKLINK_MIS_BMS06 : 31|2@0+ (1,0) [0|0] ""  PT
 SG_ DEM012_VOLTAGE_BMS_SUPPLY_BMS06 : 17|2@0+ (1,0) [0|0] ""  PT
 SG_ DEM013_ADC_ERROR_BMS06 : 19|2@0+ (1,0) [0|0] ""  PT
 SG_ DEM014_MODULET_OT_BMS06 : 21|2@0+ (1,0) [0|0] ""  PT
 SG_ DEM015_MODULET_SNA_BMS06 : 23|2@0+ (1,0) [0|0] ""  PT
 SG_ DEM016_MODULET_LIMPHOME_BMS06 : 41|2@0+ (1,0) [0|0] ""  PT
 SG_ DEM017_COOLING_SYS_LHOME_BMS06 : 43|2@0+ (1,0) [0|0] ""  PT
 SG_ DEM018_HVIL_LIMPHOME_BMS06 : 45|2@0+ (1,0) [0|0] ""  PT
 SG_ DEM019_HVIL_ESS_INHIBIT_BMS06 : 47|2@0+ (1,0) [0|0] ""  PT
 SG_ DEM020_MODULET_CHANGE_BMS06 : 33|2@0+ (1,0) [0|0] ""  PT
 SG_ DEM021_LG_MAVD_FAULT_BMS06 : 35|2@0+ (1,0) [0|0] ""  PT
 SG_ DEM022_LG_RDV_FAULT_BMS06 : 37|2@0+ (1,0) [0|0] ""  PT
 SG_ DEM023_BMS_ONBOARDT_SNA_BMS06 : 39|2@0+ (1,0) [0|0] ""  PT
 SG_ DEM024_BMS_ONBOARDRH_OH_BMS06 : 57|2@0+ (1,0) [0|0] ""  PT
 SG_ DEM025_BMS_ONBOARDRH_SNA_BMS06 : 59|2@0+ (1,0) [0|0] ""  PT
 SG_ DEM026_CURRENT_OVERCHARGE_BMS06 : 61|2@0+ (1,0) [0|0] ""  PT
 SG_ DEM027_CURRENT_OVERDISCHGE_BMS06 : 63|2@0+ (1,0) [0|0] ""  PT
 SG_ DEM028_CURRENT_INVALID_BMS06 : 49|2@0+ (1,0) [0|0] ""  PT
 SG_ DEM029_CURRENT_SHORTCIRCT_BMS06 : 51|2@0+ (1,0) [0|0] ""  PT
 SG_ DEM030_CRASH_CAN_LATCH_BMS06 : 53|2@0+ (1,0) [0|0] ""  PT
 SG_ DEM031_EEPROM_FAIL_BMS06 : 55|2@0+ (1,0) [0|0] ""  PT

BO_ 1093 BMS06_DebugEventMap2: 8 BMS06
 SG_ DEM032_PCHG_PACKS_CONNECT_BMS06 : 9|2@0+ (1,0) [0|0] ""  PT
 SG_ DEM033_PCHG_ILLEGAL_PRCHG_BMS06 : 11|2@0+ (1,0) [0|0] ""  PT
 SG_ DEM034_PCHG_RELAY_FAIL_BMS06 : 13|2@0+ (1,0) [0|0] ""  PT
 SG_ DEM035_PCHG_NEG_WELD_BMS06 : 15|2@0+ (1,0) [0|0] ""  PT
 SG_ DEM036_PCHG_NEG_PULLIN_BMS06 : 1|2@0+ (1,0) [0|0] ""  PT
 SG_ DEM037_PCHG_SHORTCIRCUIT_BMS06 : 3|2@0+ (1,0) [0|0] ""  PT
 SG_ DEM038_PCHG_OPENCIRCUIT_BMS06 : 5|2@0+ (1,0) [0|0] ""  PT
 SG_ DEM039_PCHG_TIMEOUT_BMS06 : 7|2@0+ (1,0) [0|0] ""  PT
 SG_ DEM040_PCHG_FAILED_BMS06 : 25|2@0+ (1,0) [0|0] ""  PT
 SG_ DEM041_HVIL_SHUTDOWN_BMS06 : 27|2@0+ (1,0) [0|0] ""  PT
 SG_ DEM042_PCHG_POS_WELD_BMS06 : 29|2@0+ (1,0) [0|0] ""  PT
 SG_ DEM043_HV_LOCK_TRANSPORT_BMS06 : 31|2@0+ (1,0) [0|0] ""  PT
 SG_ DEM044_CTRS_END_OF_LIFE_BMS06 : 17|2@0+ (1,0) [0|0] ""  PT
 SG_ DEM045_CTRS_CTRPWRV_HI_BMS06 : 19|2@0+ (1,0) [0|0] ""  PT
 SG_ DEM046_CTRS_COILCURR_LOW_BMS06 : 21|2@0+ (1,0) [0|0] ""  PT
 SG_ DEM047_CTRS_COILCURR_HIGH_BMS06 : 23|2@0+ (1,0) [0|0] ""  PT
 SG_ DEM048_CTRS_CTRPWRV_LOW_BMS06 : 41|2@0+ (1,0) [0|0] ""  PT
 SG_ DEM049_CHGE_ILLEGAL_DISCHG_BMS06 : 43|2@0+ (1,0) [0|0] ""  PT
 SG_ DEM050_STARTUP_CONDITIONS_BMS06 : 45|2@0+ (1,0) [0|0] ""  PT
 SG_ DEM051_VOLTAGE_BMS_SUPPLYH_BMS06 : 47|2@0+ (1,0) [0|0] ""  PT
 SG_ DEM052_SAFETYSPI_FAIL_BMS06 : 33|2@0+ (1,0) [0|0] ""  PT
 SG_ DEM053_WATCHDOG_ERRORPIN_BMS06 : 35|2@0+ (1,0) [0|0] ""  PT
 SG_ DEM054_SAFESTATE_TRIGGERED_BMS06 : 37|2@0+ (1,0) [0|0] ""  PT
 SG_ DEM055_DEBUG_CMND_ACTIVE_BMS06 : 39|2@0+ (1,0) [0|0] ""  PT
 SG_ DEM056_CRASH_CAN_BMS06 : 57|2@0+ (1,0) [0|0] ""  PT
 SG_ DEM057_ISO_EXT_STRAT_4_BMS06 : 59|2@0+ (1,0) [0|0] ""  PT
 SG_ DEM058_ISO_EXT_RES_ERR_BMS06 : 61|2@0+ (1,0) [0|0] ""  PT
 SG_ DEM059_ISO_EXT_RES_WARN_BMS06 : 63|2@0+ (1,0) [0|0] ""  PT
 SG_ DEM060_ISO_INT_RES_ERR_BMS06 : 49|2@0+ (1,0) [0|0] ""  PT
 SG_ DEM061_ISO_INT_RES_WARN_BMS06 : 51|2@0+ (1,0) [0|0] ""  PT
 SG_ DEM062_EMERGENCY_OPERATION_BMS06 : 53|2@0+ (1,0) [0|0] ""  PT
 SG_ DEM063_ENDOFDRIVE_BMS06 : 55|2@0+ (1,0) [0|0] ""  PT

BO_ 1157 BMS06_DebugEventMap3: 8 BMS06
 SG_ DEM064_STRINGV_IMBALANCE_BMS06 : 9|2@0+ (1,0) [0|0] ""  PT
 SG_ DEM065_STRING_FAULT_BMS06 : 11|2@0+ (1,0) [0|0] ""  PT
 SG_ DEM066_ESS_FAULT_BMS06 : 13|2@0+ (1,0) [0|0] ""  PT
 SG_ DEM067_ISO_EXT_STRAT_3_BMS06 : 15|2@0+ (1,0) [0|0] ""  PT
 SG_ DEM068_MODULE_COUNT_INVALI_BMS06 : 1|2@0+ (1,0) [0|0] ""  PT
 SG_ DEM069_PT_MIA_BMS06 : 3|2@0+ (1,0) [0|0] ""  PT
 SG_ DEM070_BMSMIA_STRNGMSTR_01_BMS06 : 5|2@0+ (1,0) [0|0] ""  PT
 SG_ DEM071_BMSMIA_STRNGMSTR_05_BMS06 : 7|2@0+ (1,0) [0|0] ""  PT
 SG_ DEM072_BMSMIA_STRNGMSTR_09_BMS06 : 25|2@0+ (1,0) [0|0] ""  PT
 SG_ DEM073_BMSMIA_STRNGMSTR_13_BMS06 : 27|2@0+ (1,0) [0|0] ""  PT
 SG_ DEM074_BMSMIA_STRNGMSTR_17_BMS06 : 29|2@0+ (1,0) [0|0] ""  PT
 SG_ DEM075_BMSMIA_STRNGMSTR_21_BMS06 : 31|2@0+ (1,0) [0|0] ""  PT
 SG_ DEM076_BMSMIA_STRNGMSTR_25_BMS06 : 17|2@0+ (1,0) [0|0] ""  PT
 SG_ DEM077_BMSMIA_STRNGMSTR_29_BMS06 : 19|2@0+ (1,0) [0|0] ""  PT
 SG_ DEM078_BMSMIA_STRNGMSTR_33_BMS06 : 21|2@0+ (1,0) [0|0] ""  PT
 SG_ DEM079_BMSMIA_STRNGMSTR_37_BMS06 : 23|2@0+ (1,0) [0|0] ""  PT
 SG_ DEM080_BMSMIA_STRNGMSTR_41_BMS06 : 41|2@0+ (1,0) [0|0] ""  PT
 SG_ DEM081_BMSMIA_STRNGMSTR_45_BMS06 : 43|2@0+ (1,0) [0|0] ""  PT
 SG_ DEM082_BMSMIA_STRNGMSTR_49_BMS06 : 45|2@0+ (1,0) [0|0] ""  PT
 SG_ DEM083_BMSMIA_STRNGMSTR_53_BMS06 : 47|2@0+ (1,0) [0|0] ""  PT
 SG_ DEM084_BMSMIA_STRNGMSTR_57_BMS06 : 33|2@0+ (1,0) [0|0] ""  PT
 SG_ DEM085_BMSMIA_STRNGMSTR_61_BMS06 : 35|2@0+ (1,0) [0|0] ""  PT
 SG_ DEM086_ESSCURRENT_SHORT_BMS06 : 37|2@0+ (1,0) [0|0] ""  PT
 SG_ DEM087_PT_MIA_SHUTDOWN_BMS06 : 39|2@0+ (1,0) [0|0] ""  PT
 SG_ DEM088_OUTLET_NTC_HI_BMS06 : 57|2@0+ (1,0) [0|0] ""  PT
 SG_ DEM089_OUTLET_NTC_LO_BMS06 : 59|2@0+ (1,0) [0|0] ""  PT
 SG_ DEM090_BMSMIA_ESSMASTER_BMS06 : 61|2@0+ (1,0) [0|0] ""  PT
 SG_ DEM091_PCHG_RES_OVERHEAT_BMS06 : 63|2@0+ (1,0) [0|0] ""  PT
 SG_ DEM092_BMSMIA_STRNGSLAVE_0_BMS06 : 49|2@0+ (1,0) [0|0] ""  PT
 SG_ DEM093_BMSMIA_STRNGSLAVE_1_BMS06 : 51|2@0+ (1,0) [0|0] ""  PT
 SG_ DEM094_BMSMIA_STRNGSLAVE_2_BMS06 : 53|2@0+ (1,0) [0|0] ""  PT
 SG_ DEM095_BMSMIA_STRNGSLAVE_3_BMS06 : 55|2@0+ (1,0) [0|0] ""  PT

BO_ 1221 BMS06_DebugEventMap4: 8 BMS06
 SG_ DEM096_SC_STATE_SELFTEST_BMS06 : 9|2@0+ (1,0) [0|0] ""  PT
 SG_ DEM097_SC_STATE_TEMP_BMS06 : 11|2@0+ (1,0) [0|0] ""  PT
 SG_ DEM098_SC_STATE_VOLTAGE_BMS06 : 13|2@0+ (1,0) [0|0] ""  PT
 SG_ DEM099_SC_STATE_HVIL_BMS06 : 15|2@0+ (1,0) [0|0] ""  PT
 SG_ DEM100_SC_STATE_CONTACTORS_BMS06 : 1|2@0+ (1,0) [0|0] ""  PT
 SG_ DEM101_SC_STATE_CURRENT_BMS06 : 3|2@0+ (1,0) [0|0] ""  PT
 SG_ DEM102_SC_STATE_CANRX_BMS06 : 5|2@0+ (1,0) [0|0] ""  PT
 SG_ DEM103_SC_STATE_CRASH_BMS06 : 7|2@0+ (1,0) [0|0] ""  PT
 SG_ DEM104_SC_STATE_CCTRL_BMS06 : 25|2@0+ (1,0) [0|0] ""  PT
 SG_ DEM105_SC_STATE_CANTX_BMS06 : 27|2@0+ (1,0) [0|0] ""  PT
 SG_ DEM106_SC_STATE_THERMALEVT_BMS06 : 29|2@0+ (1,0) [0|0] ""  PT
 SG_ DEM107_SC_STATE_COOLANT_BMS06 : 31|2@0+ (1,0) [0|0] ""  PT
 SG_ DEM108_SC_SELFTEST_SFTY_UC_BMS06 : 17|2@0+ (1,0) [0|0] ""  PT
 SG_ DEM109_SC_TEMP_HIGH_BMS06 : 19|2@0+ (1,0) [0|0] ""  PT
 SG_ DEM110_SC_TEMP_NTC_OPEN_BMS06 : 21|2@0+ (1,0) [0|0] ""  PT
 SG_ DEM111_SC_TEMP_NTC_SHORT_BMS06 : 23|2@0+ (1,0) [0|0] ""  PT
 SG_ DEM112_CMB_DISCONNECTED_BMS06 : 41|2@0+ (1,0) [0|0] ""  PT
 SG_ DEM113_CMB_DEFECT_BMS06 : 43|2@0+ (1,0) [0|0] ""  PT
 SG_ DEM114_CMB_COMMERROR_BMS06 : 45|2@0+ (1,0) [0|0] ""  PT
 SG_ DEM115_SC_CURR_HALL_PWR_LO_BMS06 : 47|2@0+ (1,0) [0|0] ""  PT
 SG_ DEM116_SC_CURR_HALL_VHIGH_BMS06 : 33|2@0+ (1,0) [0|0] ""  PT
 SG_ DEM117_SC_CURR_HALL_ADC_BMS06 : 35|2@0+ (1,0) [0|0] ""  PT
 SG_ DEM118_SC_CURR_HALL_VLOW_BMS06 : 37|2@0+ (1,0) [0|0] ""  PT
 SG_ DEM119_SC_CURR_ISENSE_PWR_BMS06 : 39|2@0+ (1,0) [0|0] ""  PT
 SG_ DEM120_SC_CURR_ISENSE1_MIA_BMS06 : 57|2@0+ (1,0) [0|0] ""  PT
 SG_ DEM121_SC_CURR_ISENSE2_MIA_BMS06 : 59|2@0+ (1,0) [0|0] ""  PT
 SG_ DEM122_SC_CURR_ISENSE3_MIA_BMS06 : 61|2@0+ (1,0) [0|0] ""  PT
 SG_ DEM123_SC_CURR_ISENSE4_MIA_BMS06 : 63|2@0+ (1,0) [0|0] ""  PT
 SG_ DEM124_SC_CURR_ISENSE5_MIA_BMS06 : 49|2@0+ (1,0) [0|0] ""  PT
 SG_ DEM125_SC_CURR_ISENSE1_FLT_BMS06 : 51|2@0+ (1,0) [0|0] ""  PT
 SG_ DEM126_SC_CURR_ISENSE2_FLT_BMS06 : 53|2@0+ (1,0) [0|0] ""  PT
 SG_ DEM127_SC_CURR_ISENSE3_FLT_BMS06 : 55|2@0+ (1,0) [0|0] ""  PT

BO_ 1285 BMS06_DebugEventMap5: 8 BMS06
 SG_ DEM128_SC_CURR_ISENSE4_FLT_BMS06 : 9|2@0+ (1,0) [0|0] ""  PT
 SG_ DEM129_SC_CURR_ISENSE5_FLT_BMS06 : 11|2@0+ (1,0) [0|0] ""  PT
 SG_ DEM130_SC_CURR_OFFSET_BMS06 : 13|2@0+ (1,0) [0|0] ""  PT
 SG_ DEM131_SC_CURR_PLAUSI_BMS06 : 15|2@0+ (1,0) [0|0] ""  PT
 SG_ DEM132_SC_CURR_CHARGE_HIGH_BMS06 : 1|2@0+ (1,0) [0|0] ""  PT
 SG_ DEM133_SC_CURR_DSCHAR_HIGH_BMS06 : 3|2@0+ (1,0) [0|0] ""  PT
 SG_ DEM134_SC_V_CMB_SUMOFCELL_BMS06 : 5|2@0+ (1,0) [0|0] ""  PT
 SG_ DEM135_SC_V_SENSE_OPENWIRE_BMS06 : 7|2@0+ (1,0) [0|0] ""  PT
 SG_ DEM136_SC_V_CMB_DRV_FROZEN_BMS06 : 25|2@0+ (1,0) [0|0] ""  PT
 SG_ DEM137_SC_V_PACK_PLAUSI_BMS06 : 27|2@0+ (1,0) [0|0] ""  PT
 SG_ DEM138_SC_HVIL_HW_FLT_BMS06 : 29|2@0+ (1,0) [0|0] ""  PT
 SG_ DEM139_SC_HVIL_OPEN_BMS06 : 31|2@0+ (1,0) [0|0] ""  PT
 SG_ DEM140_SC_HVIL_TO_SUP_BMS06 : 17|2@0+ (1,0) [0|0] ""  PT
 SG_ DEM141_SC_HVIL_TO_CHAS_BMS06 : 19|2@0+ (1,0) [0|0] ""  PT
 SG_ DEM142_SC_HVIL_R_HIGH_BMS06 : 21|2@0+ (1,0) [0|0] ""  PT
 SG_ DEM143_SC_HVIL_SHORT_BMS06 : 23|2@0+ (1,0) [0|0] ""  PT
 SG_ DEM144_SC_CN_ISO_FAIL_BMS06 : 41|2@0+ (1,0) [0|0] ""  PT
 SG_ DEM145_HVIL_SYS_BMS06 : 43|2@0+ (1,0) [0|0] ""  PT
 SG_ DEM146_SC_CN_POS1_WELDED_BMS06 : 45|2@0+ (1,0) [0|0] ""  PT
 SG_ DEM147_SC_CN_NEG1_WELDED_BMS06 : 47|2@0+ (1,0) [0|0] ""  PT
 SG_ DEM148_SC_CN_POS2_WELDED_BMS06 : 33|2@0+ (1,0) [0|0] ""  PT
 SG_ DEM149_SC_CN_NEG2_WELDED_BMS06 : 35|2@0+ (1,0) [0|0] ""  PT
 SG_ DEM150_SC_CN_POS3_WELDED_BMS06 : 37|2@0+ (1,0) [0|0] ""  PT
 SG_ DEM151_SC_CN_NEG3_WELDED_BMS06 : 39|2@0+ (1,0) [0|0] ""  PT
 SG_ DEM152_SC_CN_HIGH_CY_BMS06 : 57|2@0+ (1,0) [0|0] ""  PT
 SG_ DEM153_SC_CN_ISOANDPOTWELD_BMS06 : 59|2@0+ (1,0) [0|0] ""  PT
 SG_ DEM154_SC_TEMP_PLAUSI_BMS06 : 61|2@0+ (1,0) [0|0] ""  PT
 SG_ DEM155_SC_CURR_HALL_PWR_HI_BMS06 : 63|2@0+ (1,0) [0|0] ""  PT
 SG_ DEM156_SC_PYRO_TRIGGERED_BMS06 : 49|2@0+ (1,0) [0|0] ""  PT
 SG_ DEM157_SC_PYRO_OPEN_BMS06 : 51|2@0+ (1,0) [0|0] ""  PT
 SG_ DEM158_AUX_CTRS_END_OF_LIF_BMS06 : 53|2@0+ (1,0) [0|0] ""  PT
 SG_ DEM159_SC_CANRX_PT_MIA_BMS06 : 55|2@0+ (1,0) [0|0] ""  PT

BO_ 1349 BMS06_DebugEventMap6: 8 BMS06
 SG_ DEM160_SC_CANRX_PT_CRCALIV_BMS06 : 9|2@0+ (1,0) [0|0] ""  PT
 SG_ DEM161_SC_CANRX_LIN_SHUTDN_BMS06 : 11|2@0+ (1,0) [0|0] ""  PT
 SG_ DEM162_SC_CANRX_LIN_MIA_BMS06 : 13|2@0+ (1,0) [0|0] ""  PT
 SG_ DEM163_SC_CRASH1_BMS06 : 15|2@0+ (1,0) [0|0] ""  PT
 SG_ DEM164_SC_CRASH2_BMS06 : 1|2@0+ (1,0) [0|0] ""  PT
 SG_ DEM165_SC_CRASHCAN_BMS06 : 3|2@0+ (1,0) [0|0] ""  PT
 SG_ DEM166_SC_CCTRL_SELFTEST_BMS06 : 5|2@0+ (1,0) [0|0] ""  PT
 SG_ DEM167_SC_CCTRL_DRIVER_FAU_BMS06 : 7|2@0+ (1,0) [0|0] ""  PT
 SG_ DEM168_SC_CCTRL_HISIDESTCL_BMS06 : 25|2@0+ (1,0) [0|0] ""  PT
 SG_ DEM169_SC_CCTRL_HISIDESTOP_BMS06 : 27|2@0+ (1,0) [0|0] ""  PT
 SG_ DEM170_SC_CCTRL_LOSIDESTCL_BMS06 : 29|2@0+ (1,0) [0|0] ""  PT
 SG_ DEM171_SC_CCTRL_HVCNDITION_BMS06 : 31|2@0+ (1,0) [0|0] ""  PT
 SG_ DEM172_SC_CCTRL_POS1_OPN_BMS06 : 17|2@0+ (1,0) [0|0] ""  PT
 SG_ DEM173_SC_CCTRL_POS2_OPN_BMS06 : 19|2@0+ (1,0) [0|0] ""  PT
 SG_ DEM174_SC_CCTRL_POS3_OPN_BMS06 : 21|2@0+ (1,0) [0|0] ""  PT
 SG_ DEM175_SC_CCTRL_NEG1_OPN_BMS06 : 23|2@0+ (1,0) [0|0] ""  PT
 SG_ DEM176_SC_CCTRL_NEG2_OPN_BMS06 : 41|2@0+ (1,0) [0|0] ""  PT
 SG_ DEM177_SC_CCTRL_PRE2_OPN_BMS06 : 43|2@0+ (1,0) [0|0] ""  PT
 SG_ DEM178_SC_CCTRL_PRE1_OPN_BMS06 : 45|2@0+ (1,0) [0|0] ""  PT
 SG_ DEM179_SC_CCTRL_LOSIDESTOP_BMS06 : 47|2@0+ (1,0) [0|0] ""  PT
 SG_ DEM180_SC_CCTRL_UNEXPECTED_BMS06 : 33|2@0+ (1,0) [0|0] ""  PT
 SG_ DEM181_SC_V_OUT_OF_RANGE_BMS06 : 35|2@0+ (1,0) [0|0] ""  PT
 SG_ DEM182_SC_V_LATCHED_UVOV_BMS06 : 37|2@0+ (1,0) [0|0] ""  PT
 SG_ DEM183_ISO_EXT_STRAT_2_BMS06 : 39|2@0+ (1,0) [0|0] ""  PT
 SG_ DEM184_SC_CANTX_CTRS_BMS06 : 57|2@0+ (1,0) [0|0] ""  PT
 SG_ DEM185_SC_CANTX_HVIL_BMS06 : 59|2@0+ (1,0) [0|0] ""  PT
 SG_ DEM186_SC_CANTX_ISOL_BMS06 : 61|2@0+ (1,0) [0|0] ""  PT
 SG_ DEM187_SC_SBC_WATCHDOG_BMS06 : 63|2@0+ (1,0) [0|0] ""  PT
 SG_ DEM188_SC_SBC_FAULT_BMS06 : 49|2@0+ (1,0) [0|0] ""  PT
 SG_ DEM189_SC_WATCHDOG_BMS06 : 51|2@0+ (1,0) [0|0] ""  PT
 SG_ DEM190_SC_SELFTEST_RAM_BMS06 : 53|2@0+ (1,0) [0|0] ""  PT
 SG_ DEM191_SC_SELFTEST_FLASH_BMS06 : 55|2@0+ (1,0) [0|0] ""  PT

BO_ 1413 BMS06_DebugEventMap7: 8 BMS06
 SG_ DEM192_CMB_ONBOARDRH_OH_BMS06 : 9|2@0+ (1,0) [0|0] ""  PT
 SG_ DEM193_CMB_ONBOARDRH_SNA_BMS06 : 11|2@0+ (1,0) [0|0] ""  PT
 SG_ DEM194_CMB_ONBOARDT_OT_BMS06 : 13|2@0+ (1,0) [0|0] ""  PT
 SG_ DEM195_CMB_ONBOARDT_CHANGE_BMS06 : 15|2@0+ (1,0) [0|0] ""  PT
 SG_ DEM196_PRESSURE_CHANGE_BMS06 : 1|2@0+ (1,0) [0|0] ""  PT
 SG_ DEM197_PRESSURE_OVER_BMS06 : 3|2@0+ (1,0) [0|0] ""  PT
 SG_ DEM198_PRESSURE_UNDER_BMS06 : 5|2@0+ (1,0) [0|0] ""  PT
 SG_ DEM199_PRESSURE_INVALID_BMS06 : 7|2@0+ (1,0) [0|0] ""  PT
 SG_ DEM200_THERMAL_EVENT_BMS06 : 25|2@0+ (1,0) [0|0] ""  PT
 SG_ DEM201_CMB_ONBOARDT_SNA_BMS06 : 27|2@0+ (1,0) [0|0] ""  PT
 SG_ DEM202_REPLACE_DESICCANT_BMS06 : 29|2@0+ (1,0) [0|0] ""  PT
 SG_ DEM203_COOLANT_FLOOD_FAULT_BMS06 : 31|2@0+ (1,0) [0|0] ""  PT
 SG_ DEM204_LOW_BRICKCAPACITY_BMS06 : 17|2@0+ (1,0) [0|0] ""  PT
 SG_ DEM205_BMS_ONBOARDT_OT_BMS06 : 19|2@0+ (1,0) [0|0] ""  PT
 SG_ DEM206_HUMIDITY_CHANGE_BMS06 : 21|2@0+ (1,0) [0|0] ""  PT
 SG_ DEM207_ISENSE_SUPPLY_CURR_BMS06 : 23|2@0+ (1,0) [0|0] ""  PT
 SG_ DEM208_SOC_LOW_BMS06 : 41|2@0+ (1,0) [0|0] ""  PT
 SG_ DEM209_SOC_TOOLOW_BMS06 : 43|2@0+ (1,0) [0|0] ""  PT
 SG_ DEM210_SOC_TOOHIGH_BMS06 : 45|2@0+ (1,0) [0|0] ""  PT
 SG_ DEM211_BALANCING_REQUIRED_BMS06 : 47|2@0+ (1,0) [0|0] ""  PT
 SG_ DEM212_DEEP_DISCHARGE_BMS06 : 33|2@0+ (1,0) [0|0] ""  PT
 SG_ DEM213_CAN1_BUS_OFF_BMS06 : 35|2@0+ (1,0) [0|0] ""  PT
 SG_ DEM214_CAN2_BUS_OFF_BMS06 : 37|2@0+ (1,0) [0|0] ""  PT
 SG_ DEM215_CAN3_BUS_OFF_BMS06 : 39|2@0+ (1,0) [0|0] ""  PT
 SG_ DEM216_OUTLET_NTC_RATNAL_BMS06 : 57|2@0+ (1,0) [0|0] ""  PT
 SG_ DEM217_FUSE_PACK_BMS06 : 59|2@0+ (1,0) [0|0] ""  PT
 SG_ DEM218_FUSE_B_OPEN_BMS06 : 61|2@0+ (1,0) [0|0] ""  PT
 SG_ DEM219_FUSE_C_OPEN_BMS06 : 63|2@0+ (1,0) [0|0] ""  PT
 SG_ DEM220_FUSE_D_OPEN_BMS06 : 49|2@0+ (1,0) [0|0] ""  PT
 SG_ DEM221_FUSE_E_OPEN_BMS06 : 51|2@0+ (1,0) [0|0] ""  PT
 SG_ DEM222_PUMP_DRY_RUN_BMS06 : 53|2@0+ (1,0) [0|0] ""  PT
 SG_ DEM223_PUMP_PERFORMANCE_BMS06 : 55|2@0+ (1,0) [0|0] ""  PT

BO_ 1477 BMS06_DebugEventMap8: 8 BMS06
 SG_ DEM224_PUMP_LIN_FAILURE_BMS06 : 9|2@0+ (1,0) [0|0] ""  PT
 SG_ DEM225_PUMP_SUPPLY_VOLTAGE_BMS06 : 11|2@0+ (1,0) [0|0] ""  PT
 SG_ DEM226_PUMP_RECOVERY_FAIL_BMS06 : 13|2@0+ (1,0) [0|0] ""  PT
 SG_ DEM227_CTR_POS_OPENED_BMS06 : 15|2@0+ (1,0) [0|0] ""  PT
 SG_ DEM228_CTR_NEG_OPENED_BMS06 : 1|2@0+ (1,0) [0|0] ""  PT
 SG_ DEM229_STRSET_SLAVE1_FAULT_BMS06 : 3|2@0+ (1,0) [0|0] ""  PT
 SG_ DEM230_STRSET_SLAVE2_FAULT_BMS06 : 5|2@0+ (1,0) [0|0] ""  PT
 SG_ DEM231_CTRSAUX_CLFAIL_HVON_BMS06 : 7|2@0+ (1,0) [0|0] ""  PT
 SG_ DEM232_CTRSAUX_CLFAIL_VDIF_BMS06 : 25|2@0+ (1,0) [0|0] ""  PT
 SG_ DEM233_CTRSAUX_POS1_OPENED_BMS06 : 27|2@0+ (1,0) [0|0] ""  PT
 SG_ DEM234_CTRSAUX_NEG1_OPENED_BMS06 : 29|2@0+ (1,0) [0|0] ""  PT
 SG_ DEM235_CTRSAUX_POS1_WELDED_BMS06 : 31|2@0+ (1,0) [0|0] ""  PT
 SG_ DEM236_CTRSAUX_NEG1_WELDED_BMS06 : 17|2@0+ (1,0) [0|0] ""  PT
 SG_ DEM237_CTRSAUX_POS1_PULLIN_BMS06 : 19|2@0+ (1,0) [0|0] ""  PT
 SG_ DEM238_CTRSAUX_NEG1_PULLIN_BMS06 : 21|2@0+ (1,0) [0|0] ""  PT
 SG_ DEM239_INLET_NTC_RATNAL_BMS06 : 23|2@0+ (1,0) [0|0] ""  PT
 SG_ DEM240_INLET_NTC_HI_BMS06 : 41|2@0+ (1,0) [0|0] ""  PT
 SG_ DEM241_INLET_NTC_LO_BMS06 : 43|2@0+ (1,0) [0|0] ""  PT
 SG_ DEM242_VOLTAGE_LINK2_RATNA_BMS06 : 45|2@0+ (1,0) [0|0] ""  PT
 SG_ DEM243_VOLTAGE_LINK2_HI_BMS06 : 47|2@0+ (1,0) [0|0] ""  PT
 SG_ DEM244_VOLTAGE_LINK2_LO_BMS06 : 33|2@0+ (1,0) [0|0] ""  PT
 SG_ DEM245_CMB_ONBOARD_IMPOSSI_BMS06 : 35|2@0+ (1,0) [0|0] ""  PT
 SG_ DEM246_VOLTAGE_LINK1_HI_BMS06 : 37|2@0+ (1,0) [0|0] ""  PT
 SG_ DEM247_VOLTAGE_LINK1_LO_BMS06 : 39|2@0+ (1,0) [0|0] ""  PT
 SG_ DEM248_NTC_SUPPLY_LO_BMS06 : 57|2@0+ (1,0) [0|0] ""  PT
 SG_ DEM249_NTC_SUPPLY_HI_BMS06 : 59|2@0+ (1,0) [0|0] ""  PT
 SG_ DEM250_VOLTAGE_LINK3_RATNA_BMS06 : 61|2@0+ (1,0) [0|0] ""  PT
 SG_ DEM251_VOLTAGE_LINK3_HI_BMS06 : 63|2@0+ (1,0) [0|0] ""  PT
 SG_ DEM252_VOLTAGE_LINK3_LO_BMS06 : 49|2@0+ (1,0) [0|0] ""  PT
 SG_ DEM253_BALANCING_STUCK_BMS06 : 51|2@0+ (1,0) [0|0] ""  PT
 SG_ DEM254_ARM_EXCEPTION_BMS06 : 53|2@0+ (1,0) [0|0] ""  PT
 SG_ DEM255_ERROR_HOOKS_BMS06 : 55|2@0+ (1,0) [0|0] ""  PT

BO_ 837 BMS06_DebugEventMap9: 8 BMS06
 SG_ DEM256_XCP_CAL_CHANGE_BMS06 : 9|2@0+ (1,0) [0|0] ""  PT
 SG_ DEM257_XCP_CAL_PERM_CHANGE_BMS06 : 11|2@0+ (1,0) [0|0] ""  PT
 SG_ DEM258_TASK_TIME_OVERFLOW_BMS06 : 13|2@0+ (1,0) [0|0] ""  PT
 SG_ DEM259_ISO_CIRCUIT_BMS06 : 15|2@0+ (1,0) [0|0] ""  PT
 SG_ DEM260_COOLANT_MOIST_FAULT_BMS06 : 1|2@0+ (1,0) [0|0] ""  PT
 SG_ DEM261_COOLANT_FLOOD_WARN_BMS06 : 3|2@0+ (1,0) [0|0] ""  PT
 SG_ DEM262_COOLANT_MOIST_WARN_BMS06 : 5|2@0+ (1,0) [0|0] ""  PT
 SG_ DEM263_MODULET_IMPLAUSIBLE_BMS06 : 7|2@0+ (1,0) [0|0] ""  PT
 SG_ DEM264_REQUEST_ON_WITH_HV__BMS06 : 25|2@0+ (1,0) [0|0] ""  PT
 SG_ DEM265_CSERS_PCODE_BMS06 : 27|2@0+ (1,0) [0|0] ""  PT
 SG_ DEM266_PRELIM_CNTR_CL_FAIL_BMS06 : 29|2@0+ (1,0) [0|0] ""  PT
 SG_ DEM267_FLUIDLVL_LOW_BMS06 : 31|2@0+ (1,0) [0|0] ""  PT
 SG_ DEM268_FLUIDLVL_FAILURE_BMS06 : 17|2@0+ (1,0) [0|0] ""  PT
 SG_ DEM269_SC_COOLANT_CONTAM_BMS06 : 19|2@0+ (1,0) [0|0] ""  PT
 SG_ DEM270_SC_COOLANT_MIA_BMS06 : 21|2@0+ (1,0) [0|0] ""  PT
 SG_ DEM271_PRESSURE_VHI_BMS06 : 23|2@0+ (1,0) [0|0] ""  PT
 SG_ DEM272_PRESSURE_VLO_BMS06 : 41|2@0+ (1,0) [0|0] ""  PT
 SG_ DEM273_SC_COOLANT_FAIL_BMS06 : 43|2@0+ (1,0) [0|0] ""  PT
 SG_ DEM274_CTRSAUX_POS2_OPENED_BMS06 : 45|2@0+ (1,0) [0|0] ""  PT
 SG_ DEM275_CTRSAUX_POS3_OPENED_BMS06 : 47|2@0+ (1,0) [0|0] ""  PT
 SG_ DEM276_CTRSAUX_POS2_WELDED_BMS06 : 33|2@0+ (1,0) [0|0] ""  PT
 SG_ DEM277_CTRSAUX_POS3_WELDED_BMS06 : 35|2@0+ (1,0) [0|0] ""  PT
 SG_ DEM278_CTRSAUX_POS2_PULLIN_BMS06 : 37|2@0+ (1,0) [0|0] ""  PT
 SG_ DEM279_CTRSAUX_POS3_PULLIN_BMS06 : 39|2@0+ (1,0) [0|0] ""  PT
 SG_ DEM280_CMB_HUMIDITY_TEMP_C_BMS06 : 57|2@0+ (1,0) [0|0] ""  PT
 SG_ DEM281_THERMAL_EVENT_CMB_R_BMS06 : 59|2@0+ (1,0) [0|0] ""  PT
 SG_ DEM282_CUS_BRICKOV_BMS06 : 61|2@0+ (1,0) [0|0] ""  PT
 SG_ DEM283_CUS_BRICKUV_BMS06 : 63|2@0+ (1,0) [0|0] ""  PT
 SG_ DEM284_CUS_OVERCHRG_BMS06 : 49|2@0+ (1,0) [0|0] ""  PT
 SG_ DEM285_CUS_OVERDCHRG_BMS06 : 51|2@0+ (1,0) [0|0] ""  PT
 SG_ DEM286_CUS_CURRENT_CHG_BMS06 : 53|2@0+ (1,0) [0|0] ""  PT
 SG_ DEM287_CUS_CURRENT_DCHG_BMS06 : 55|2@0+ (1,0) [0|0] ""  PT

BA_DEF_ SG_  "GenSigSendType" ENUM  "Cyclic","OnWrite","OnWriteWithRepetition","OnChange","OnChangeWithRepetition","IfActive","IfActiveWithRepetition","NoSigSendType";
BA_DEF_ BO_  "GenMsgCycleTime" INT 0 0;
BA_DEF_ BO_  "GenMsgSendType" ENUM  "Cyclic","not_used","not_used","not_used","not_used","Cyclic","not_used","IfActive","NoMsgSendType";
BA_DEF_DEF_  "GenSigSendType" "Cyclic";
BA_DEF_DEF_  "GenMsgCycleTime" 0;
BA_DEF_DEF_  "GenMsgSendType" "NoMsgSendType";
BA_ "GenMsgCycleTime" BO_ 1988 100;
BA_ "GenMsgCycleTime" BO_ 965 1000;
BA_ "GenMsgCycleTime" BO_ 1797 100;
BA_ "GenMsgCycleTime" BO_ 1861 1000;
BA_ "GenMsgCycleTime" BO_ 1733 100;
BA_ "GenMsgCycleTime" BO_ 1029 1000;
BA_ "GenMsgCycleTime" BO_ 1093 1000;
BA_ "GenMsgCycleTime" BO_ 1157 1000;
BA_ "GenMsgCycleTime" BO_ 1221 1000;
BA_ "GenMsgCycleTime" BO_ 1285 1000;
BA_ "GenMsgCycleTime" BO_ 1349 1000;
BA_ "GenMsgCycleTime" BO_ 1413 1000;
BA_ "GenMsgCycleTime" BO_ 1477 1000;
VAL_ 1988 cmbMultiplexor_BMS05 0 "C000" 1 "C001" 2 "C002" 3 "C003" 4 "C004" 5 "C005" 6 "C006" 7 "C007" 8 "C008" 9 "C009" 10 "C010" 11 "C011" 12 "C012" 13 "C013" 14 "C014" 15 "C015" 16 "C016" 17 "C017" 18 "C018" 19 "C019" 20 "C020" 21 "C021" 22 "C022" 23 "C023" 24 "C024" 25 "C025" 26 "C026" 27 "C027" 28 "C028" 29 "C029" 30 "C030" 31 "C031" 32 "C032" 33 "C033" 34 "C034" 35 "C035" 36 "C036" 37 "C037" 38 "C038" 39 "C039" 40 "C040" 41 "C041" 42 "C042" 43 "C043" 44 "C044" 45 "C045" 46 "C046" 47 "C047" 48 "C048" 49 "C049" 50 "C050" 51 "C051" 52 "C052" 53 "C053" 54 "C054" 55 "C055" 56 "C056" 57 "C057" 58 "C058" 59 "C059" 60 "C060" 61 "C061" 62 "C062" 63 "C063" 64 "C064" 65 "C065" 66 "C066" 67 "C067" 68 "C068" 69 "C069" 70 "C070" 71 "C071" 72 "C072" 73 "C073" 74 "C074" 75 "C075" 76 "C076" 77 "C077" 78 "C078" 79 "C079" 80 "C080" 81 "C081" 82 "C082" 83 "C083" 84 "C084" 85 "C085" 86 "C086" 87 "C087" 88 "C088" 89 "C089" 90 "C090" 91 "C091" 92 "C092" 93 "C093" 94 "C094" 95 "C095" 96 "C096" 97 "C097" 98 "C098" 99 "C099" 100 "C100" 101 "C101" 102 "C102" 103 "C103" 104 "C104" 105 "C105" 106 "C106" 107 "C107" 108 "C108" 109 "C109" 110 "C110" 111 "C111" 112 "C112" 113 "C113" 114 "C114" 115 "C115" 116 "C116" 117 "C117" 118 "C118" 119 "C119" 120 "C120" 121 "C121" 122 "C122" 123 "C123" 124 "C124" 125 "C125" 126 "C126" 127 "C127" 128 "C128" 129 "C129" 130 "C130" 131 "C131" 132 "C132" 133 "C133" 134 "C134" 135 "C135" 136 "C136" 137 "C137" 138 "C138" 139 "C139" 140 "C140" 141 "C141" 142 "C142" 143 "C143" 144 "C144" 145 "C145" 146 "C146" 147 "C147" 148 "C148" 149 "C149" 150 "C150" 151 "C151" 152 "C152" 153 "C153" 154 "C154" 155 "C155" 156 "C156" 157 "C157" 158 "C158" 159 "C159" 160 "C160" 161 "C161" 162 "C162" 163 "C163" 164 "C164" 165 "C165" 166 "C166" 167 "C167" 168 "C168" 169 "C169" 170 "C170" 171 "C171" 172 "C172" 173 "C173" 174 "C174" 175 "C175" 176 "C176" 177 "C177" 178 "C178" 179 "C179" 180 "C180" 181 "C181" 182 "C182" 183 "C183" 184 "C184" 185 "C185" 186 "C186" 187 "C187" 188 "C188" 189 "C189" 190 "C190" 191 "C191" 192 "C192" ;
VAL_ 1988 moduleTemperature01_BMS05 255 "SNA" ;
VAL_ 1988 brickVoltage001_BMS05 65535 "SNA" ;
VAL_ 1988 brickVoltage002_BMS05 65535 "SNA" ;
VAL_ 1988 brickVoltage003_BMS05 65535 "SNA" ;
VAL_ 1988 moduleTemperature02_BMS05 255 "SNA" ;
VAL_ 1988 brickVoltage004_BMS05 65535 "SNA" ;
VAL_ 1988 brickVoltage005_BMS05 65535 "SNA" ;
VAL_ 1988 brickVoltage006_BMS05 65535 "SNA" ;
VAL_ 1988 moduleTemperature03_BMS05 255 "SNA" ;
VAL_ 1988 brickVoltage007_BMS05 65535 "SNA" ;
VAL_ 1988 brickVoltage008_BMS05 65535 "SNA" ;
VAL_ 1988 brickVoltage009_BMS05 65535 "SNA" ;
VAL_ 1988 moduleTemperature04_BMS05 255 "SNA" ;
VAL_ 1988 brickVoltage010_BMS05 65535 "SNA" ;
VAL_ 1988 brickVoltage011_BMS05 65535 "SNA" ;
VAL_ 1988 brickVoltage012_BMS05 65535 "SNA" ;
VAL_ 1988 moduleTemperature05_BMS05 255 "SNA" ;
VAL_ 1988 brickVoltage013_BMS05 65535 "SNA" ;
VAL_ 1988 brickVoltage014_BMS05 65535 "SNA" ;
VAL_ 1988 brickVoltage015_BMS05 65535 "SNA" ;
VAL_ 1988 moduleTemperature06_BMS05 255 "SNA" ;
VAL_ 1988 brickVoltage016_BMS05 65535 "SNA" ;
VAL_ 1988 brickVoltage017_BMS05 65535 "SNA" ;
VAL_ 1988 brickVoltage018_BMS05 65535 "SNA" ;
VAL_ 1988 moduleTemperature07_BMS05 255 "SNA" ;
VAL_ 1988 brickVoltage019_BMS05 65535 "SNA" ;
VAL_ 1988 brickVoltage020_BMS05 65535 "SNA" ;
VAL_ 1988 brickVoltage021_BMS05 65535 "SNA" ;
VAL_ 1988 moduleTemperature08_BMS05 255 "SNA" ;
VAL_ 1988 brickVoltage022_BMS05 65535 "SNA" ;
VAL_ 1988 brickVoltage023_BMS05 65535 "SNA" ;
VAL_ 1988 brickVoltage024_BMS05 65535 "SNA" ;
VAL_ 1988 moduleTemperature09_BMS05 255 "SNA" ;
VAL_ 1988 brickVoltage025_BMS05 65535 "SNA" ;
VAL_ 1988 brickVoltage026_BMS05 65535 "SNA" ;
VAL_ 1988 brickVoltage027_BMS05 65535 "SNA" ;
VAL_ 1988 moduleTemperature10_BMS05 255 "SNA" ;
VAL_ 1988 brickVoltage028_BMS05 65535 "SNA" ;
VAL_ 1988 brickVoltage029_BMS05 65535 "SNA" ;
VAL_ 1988 brickVoltage030_BMS05 65535 "SNA" ;
VAL_ 1988 moduleTemperature11_BMS05 255 "SNA" ;
VAL_ 1988 brickVoltage031_BMS05 65535 "SNA" ;
VAL_ 1988 brickVoltage032_BMS05 65535 "SNA" ;
VAL_ 1988 brickVoltage033_BMS05 65535 "SNA" ;
VAL_ 1988 moduleTemperature12_BMS05 255 "SNA" ;
VAL_ 1988 brickVoltage034_BMS05 65535 "SNA" ;
VAL_ 1988 brickVoltage035_BMS05 65535 "SNA" ;
VAL_ 1988 brickVoltage036_BMS05 65535 "SNA" ;
VAL_ 1988 moduleTemperature13_BMS05 255 "SNA" ;
VAL_ 1988 brickVoltage037_BMS05 65535 "SNA" ;
VAL_ 1988 brickVoltage038_BMS05 65535 "SNA" ;
VAL_ 1988 brickVoltage039_BMS05 65535 "SNA" ;
VAL_ 1988 moduleTemperature14_BMS05 255 "SNA" ;
VAL_ 1988 brickVoltage040_BMS05 65535 "SNA" ;
VAL_ 1988 brickVoltage041_BMS05 65535 "SNA" ;
VAL_ 1988 brickVoltage042_BMS05 65535 "SNA" ;
VAL_ 1988 moduleTemperature15_BMS05 255 "SNA" ;
VAL_ 1988 brickVoltage043_BMS05 65535 "SNA" ;
VAL_ 1988 brickVoltage044_BMS05 65535 "SNA" ;
VAL_ 1988 brickVoltage045_BMS05 65535 "SNA" ;
VAL_ 1988 moduleTemperature16_BMS05 255 "SNA" ;
VAL_ 1988 brickVoltage046_BMS05 65535 "SNA" ;
VAL_ 1988 brickVoltage047_BMS05 65535 "SNA" ;
VAL_ 1988 brickVoltage048_BMS05 65535 "SNA" ;
VAL_ 1988 moduleTemperature17_BMS05 255 "SNA" ;
VAL_ 1988 brickVoltage049_BMS05 65535 "SNA" ;
VAL_ 1988 brickVoltage050_BMS05 65535 "SNA" ;
VAL_ 1988 brickVoltage051_BMS05 65535 "SNA" ;
VAL_ 1988 moduleTemperature18_BMS05 255 "SNA" ;
VAL_ 1988 brickVoltage052_BMS05 65535 "SNA" ;
VAL_ 1988 brickVoltage053_BMS05 65535 "SNA" ;
VAL_ 1988 brickVoltage054_BMS05 65535 "SNA" ;
VAL_ 1988 moduleTemperature19_BMS05 255 "SNA" ;
VAL_ 1988 brickVoltage055_BMS05 65535 "SNA" ;
VAL_ 1988 brickVoltage056_BMS05 65535 "SNA" ;
VAL_ 1988 brickVoltage057_BMS05 65535 "SNA" ;
VAL_ 1988 moduleTemperature20_BMS05 255 "SNA" ;
VAL_ 1988 brickVoltage058_BMS05 65535 "SNA" ;
VAL_ 1988 brickVoltage059_BMS05 65535 "SNA" ;
VAL_ 1988 brickVoltage060_BMS05 65535 "SNA" ;
VAL_ 1988 moduleTemperature21_BMS05 255 "SNA" ;
VAL_ 1988 brickVoltage061_BMS05 65535 "SNA" ;
VAL_ 1988 brickVoltage062_BMS05 65535 "SNA" ;
VAL_ 1988 brickVoltage063_BMS05 65535 "SNA" ;
VAL_ 1988 moduleTemperature22_BMS05 255 "SNA" ;
VAL_ 1988 brickVoltage064_BMS05 65535 "SNA" ;
VAL_ 1988 brickVoltage065_BMS05 65535 "SNA" ;
VAL_ 1988 brickVoltage066_BMS05 65535 "SNA" ;
VAL_ 1988 moduleTemperature23_BMS05 255 "SNA" ;
VAL_ 1988 brickVoltage067_BMS05 65535 "SNA" ;
VAL_ 1988 brickVoltage068_BMS05 65535 "SNA" ;
VAL_ 1988 brickVoltage069_BMS05 65535 "SNA" ;
VAL_ 1988 moduleTemperature24_BMS05 255 "SNA" ;
VAL_ 1988 brickVoltage070_BMS05 65535 "SNA" ;
VAL_ 1988 brickVoltage071_BMS05 65535 "SNA" ;
VAL_ 1988 brickVoltage072_BMS05 65535 "SNA" ;
VAL_ 1988 moduleTemperature25_BMS05 255 "SNA" ;
VAL_ 1988 brickVoltage073_BMS05 65535 "SNA" ;
VAL_ 1988 brickVoltage074_BMS05 65535 "SNA" ;
VAL_ 1988 brickVoltage075_BMS05 65535 "SNA" ;
VAL_ 1988 moduleTemperature26_BMS05 255 "SNA" ;
VAL_ 1988 brickVoltage076_BMS05 65535 "SNA" ;
VAL_ 1988 brickVoltage077_BMS05 65535 "SNA" ;
VAL_ 1988 brickVoltage078_BMS05 65535 "SNA" ;
VAL_ 1988 moduleTemperature27_BMS05 255 "SNA" ;
VAL_ 1988 brickVoltage079_BMS05 65535 "SNA" ;
VAL_ 1988 brickVoltage080_BMS05 65535 "SNA" ;
VAL_ 1988 brickVoltage081_BMS05 65535 "SNA" ;
VAL_ 1988 moduleTemperature28_BMS05 255 "SNA" ;
VAL_ 1988 brickVoltage082_BMS05 65535 "SNA" ;
VAL_ 1988 brickVoltage083_BMS05 65535 "SNA" ;
VAL_ 1988 brickVoltage084_BMS05 65535 "SNA" ;
VAL_ 1988 moduleTemperature29_BMS05 255 "SNA" ;
VAL_ 1988 brickVoltage085_BMS05 65535 "SNA" ;
VAL_ 1988 brickVoltage086_BMS05 65535 "SNA" ;
VAL_ 1988 brickVoltage087_BMS05 65535 "SNA" ;
VAL_ 1988 moduleTemperature30_BMS05 255 "SNA" ;
VAL_ 1988 brickVoltage088_BMS05 65535 "SNA" ;
VAL_ 1988 brickVoltage089_BMS05 65535 "SNA" ;
VAL_ 1988 brickVoltage090_BMS05 65535 "SNA" ;
VAL_ 1988 moduleTemperature31_BMS05 255 "SNA" ;
VAL_ 1988 brickVoltage091_BMS05 65535 "SNA" ;
VAL_ 1988 brickVoltage092_BMS05 65535 "SNA" ;
VAL_ 1988 brickVoltage093_BMS05 65535 "SNA" ;
VAL_ 1988 moduleTemperature32_BMS05 255 "SNA" ;
VAL_ 1988 brickVoltage094_BMS05 65535 "SNA" ;
VAL_ 1988 brickVoltage095_BMS05 65535 "SNA" ;
VAL_ 1988 brickVoltage096_BMS05 65535 "SNA" ;
VAL_ 1988 brickVoltage097_BMS05 65535 "SNA" ;
VAL_ 1988 brickVoltage098_BMS05 65535 "SNA" ;
VAL_ 1988 brickVoltage099_BMS05 65535 "SNA" ;
VAL_ 1988 brickVoltage100_BMS05 65535 "SNA" ;
VAL_ 1988 brickVoltage101_BMS05 65535 "SNA" ;
VAL_ 1988 brickVoltage102_BMS05 65535 "SNA" ;
VAL_ 1988 brickVoltage103_BMS05 65535 "SNA" ;
VAL_ 1988 brickVoltage104_BMS05 65535 "SNA" ;
VAL_ 1988 brickVoltage105_BMS05 65535 "SNA" ;
VAL_ 1988 brickVoltage106_BMS05 65535 "SNA" ;
VAL_ 1988 brickVoltage107_BMS05 65535 "SNA" ;
VAL_ 1988 brickVoltage108_BMS05 65535 "SNA" ;
VAL_ 1988 brickVoltage109_BMS05 65535 "SNA" ;
VAL_ 1988 brickVoltage110_BMS05 65535 "SNA" ;
VAL_ 1988 brickVoltage111_BMS05 65535 "SNA" ;
VAL_ 1988 brickVoltage112_BMS05 65535 "SNA" ;
VAL_ 1988 brickVoltage113_BMS05 65535 "SNA" ;
VAL_ 1988 brickVoltage114_BMS05 65535 "SNA" ;
VAL_ 1988 brickVoltage115_BMS05 65535 "SNA" ;
VAL_ 1988 brickVoltage116_BMS05 65535 "SNA" ;
VAL_ 1988 brickVoltage117_BMS05 65535 "SNA" ;
VAL_ 1988 brickVoltage118_BMS05 65535 "SNA" ;
VAL_ 1988 brickVoltage119_BMS05 65535 "SNA" ;
VAL_ 1988 brickVoltage120_BMS05 65535 "SNA" ;
VAL_ 1988 brickVoltage121_BMS05 65535 "SNA" ;
VAL_ 1988 brickVoltage122_BMS05 65535 "SNA" ;
VAL_ 1988 brickVoltage123_BMS05 65535 "SNA" ;
VAL_ 1988 brickVoltage124_BMS05 65535 "SNA" ;
VAL_ 1988 brickVoltage125_BMS05 65535 "SNA" ;
VAL_ 1988 brickVoltage126_BMS05 65535 "SNA" ;
VAL_ 1988 brickVoltage127_BMS05 65535 "SNA" ;
VAL_ 1988 brickVoltage128_BMS05 65535 "SNA" ;
VAL_ 1988 brickVoltage129_BMS05 65535 "SNA" ;
VAL_ 1988 brickVoltage130_BMS05 65535 "SNA" ;
VAL_ 1988 brickVoltage131_BMS05 65535 "SNA" ;
VAL_ 1988 brickVoltage132_BMS05 65535 "SNA" ;
VAL_ 1988 brickVoltage133_BMS05 65535 "SNA" ;
VAL_ 1988 brickVoltage134_BMS05 65535 "SNA" ;
VAL_ 1988 brickVoltage135_BMS05 65535 "SNA" ;
VAL_ 1988 brickVoltage136_BMS05 65535 "SNA" ;
VAL_ 1988 brickVoltage137_BMS05 65535 "SNA" ;
VAL_ 1988 brickVoltage138_BMS05 65535 "SNA" ;
VAL_ 1988 brickVoltage139_BMS05 65535 "SNA" ;
VAL_ 1988 brickVoltage140_BMS05 65535 "SNA" ;
VAL_ 1988 brickVoltage141_BMS05 65535 "SNA" ;
VAL_ 1988 brickVoltage142_BMS05 65535 "SNA" ;
VAL_ 1988 brickVoltage143_BMS05 65535 "SNA" ;
VAL_ 1988 brickVoltage144_BMS05 65535 "SNA" ;
VAL_ 1988 brickVoltage145_BMS05 65535 "SNA" ;
VAL_ 1988 brickVoltage146_BMS05 65535 "SNA" ;
VAL_ 1988 brickVoltage147_BMS05 65535 "SNA" ;
VAL_ 1988 brickVoltage148_BMS05 65535 "SNA" ;
VAL_ 1988 brickVoltage149_BMS05 65535 "SNA" ;
VAL_ 1988 brickVoltage150_BMS05 65535 "SNA" ;
VAL_ 1988 brickVoltage151_BMS05 65535 "SNA" ;
VAL_ 1988 brickVoltage152_BMS05 65535 "SNA" ;
VAL_ 1988 brickVoltage153_BMS05 65535 "SNA" ;
VAL_ 1988 brickVoltage154_BMS05 65535 "SNA" ;
VAL_ 1988 brickVoltage155_BMS05 65535 "SNA" ;
VAL_ 1988 brickVoltage156_BMS05 65535 "SNA" ;
VAL_ 1988 brickVoltage157_BMS05 65535 "SNA" ;
VAL_ 1988 brickVoltage158_BMS05 65535 "SNA" ;
VAL_ 1988 brickVoltage159_BMS05 65535 "SNA" ;
VAL_ 1988 brickVoltage160_BMS05 65535 "SNA" ;
VAL_ 1988 brickVoltage161_BMS05 65535 "SNA" ;
VAL_ 1988 brickVoltage162_BMS05 65535 "SNA" ;
VAL_ 1988 brickVoltage163_BMS05 65535 "SNA" ;
VAL_ 1988 brickVoltage164_BMS05 65535 "SNA" ;
VAL_ 1988 brickVoltage165_BMS05 65535 "SNA" ;
VAL_ 1988 brickVoltage166_BMS05 65535 "SNA" ;
VAL_ 1988 brickVoltage167_BMS05 65535 "SNA" ;
VAL_ 1988 brickVoltage168_BMS05 65535 "SNA" ;
VAL_ 1988 brickVoltage169_BMS05 65535 "SNA" ;
VAL_ 1988 brickVoltage170_BMS05 65535 "SNA" ;
VAL_ 1988 brickVoltage171_BMS05 65535 "SNA" ;
VAL_ 1988 brickVoltage172_BMS05 65535 "SNA" ;
VAL_ 1988 brickVoltage173_BMS05 65535 "SNA" ;
VAL_ 1988 brickVoltage174_BMS05 65535 "SNA" ;
VAL_ 1988 brickVoltage175_BMS05 65535 "SNA" ;
VAL_ 1988 brickVoltage176_BMS05 65535 "SNA" ;
VAL_ 1988 brickVoltage177_BMS05 65535 "SNA" ;
VAL_ 1988 brickVoltage178_BMS05 65535 "SNA" ;
VAL_ 1988 brickVoltage179_BMS05 65535 "SNA" ;
VAL_ 1988 brickVoltage180_BMS05 65535 "SNA" ;
VAL_ 1988 brickVoltage181_BMS05 65535 "SNA" ;
VAL_ 1988 brickVoltage182_BMS05 65535 "SNA" ;
VAL_ 1988 brickVoltage183_BMS05 65535 "SNA" ;
VAL_ 1988 brickVoltage184_BMS05 65535 "SNA" ;
VAL_ 1988 brickVoltage185_BMS05 65535 "SNA" ;
VAL_ 1988 brickVoltage186_BMS05 65535 "SNA" ;
VAL_ 1988 brickVoltage187_BMS05 65535 "SNA" ;
VAL_ 1988 brickVoltage188_BMS05 65535 "SNA" ;
VAL_ 1988 brickVoltage189_BMS05 65535 "SNA" ;
VAL_ 1988 brickVoltage190_BMS05 65535 "SNA" ;
VAL_ 1988 brickVoltage191_BMS05 65535 "SNA" ;
VAL_ 1988 brickVoltage192_BMS05 65535 "SNA" ;
VAL_ 1988 brickVoltage193_BMS05 65535 "SNA" ;
VAL_ 1988 brickVoltage194_BMS05 65535 "SNA" ;
VAL_ 1988 brickVoltage195_BMS05 65535 "SNA" ;
VAL_ 1988 brickVoltage196_BMS05 65535 "SNA" ;
VAL_ 1988 brickVoltage197_BMS05 65535 "SNA" ;
VAL_ 1988 brickVoltage198_BMS05 65535 "SNA" ;
VAL_ 1988 brickVoltage199_BMS05 65535 "SNA" ;
VAL_ 1988 brickVoltage200_BMS05 65535 "SNA" ;
VAL_ 1988 brickVoltage201_BMS05 65535 "SNA" ;
VAL_ 1988 brickVoltage202_BMS05 65535 "SNA" ;
VAL_ 1988 brickVoltage203_BMS05 65535 "SNA" ;
VAL_ 1988 brickVoltage204_BMS05 65535 "SNA" ;
VAL_ 1988 brickVoltage205_BMS05 65535 "SNA" ;
VAL_ 1988 brickVoltage206_BMS05 65535 "SNA" ;
VAL_ 1988 brickVoltage207_BMS05 65535 "SNA" ;
VAL_ 1988 brickVoltage208_BMS05 65535 "SNA" ;
VAL_ 1988 brickVoltage209_BMS05 65535 "SNA" ;
VAL_ 1988 brickVoltage210_BMS05 65535 "SNA" ;
VAL_ 1988 brickVoltage211_BMS05 65535 "SNA" ;
VAL_ 1988 brickVoltage212_BMS05 65535 "SNA" ;
VAL_ 1988 brickVoltage213_BMS05 65535 "SNA" ;
VAL_ 1988 brickVoltage214_BMS05 65535 "SNA" ;
VAL_ 1988 brickVoltage215_BMS05 65535 "SNA" ;
VAL_ 1988 brickVoltage216_BMS05 65535 "SNA" ;
VAL_ 1988 brickVoltage217_BMS05 65535 "SNA" ;
VAL_ 1988 brickVoltage218_BMS05 65535 "SNA" ;
VAL_ 1988 brickVoltage219_BMS05 65535 "SNA" ;
VAL_ 1988 brickVoltage220_BMS05 65535 "SNA" ;
VAL_ 1988 brickVoltage221_BMS05 65535 "SNA" ;
VAL_ 1988 brickVoltage222_BMS05 65535 "SNA" ;
VAL_ 1988 brickVoltage223_BMS05 65535 "SNA" ;
VAL_ 1988 brickVoltage224_BMS05 65535 "SNA" ;
VAL_ 1988 brickVoltage225_BMS05 65535 "SNA" ;
VAL_ 1988 brickVoltage226_BMS05 65535 "SNA" ;
VAL_ 1988 brickVoltage227_BMS05 65535 "SNA" ;
VAL_ 1988 brickVoltage228_BMS05 65535 "SNA" ;
VAL_ 1988 brickVoltage229_BMS05 65535 "SNA" ;
VAL_ 1988 brickVoltage230_BMS05 65535 "SNA" ;
VAL_ 1988 brickVoltage231_BMS05 65535 "SNA" ;
VAL_ 1988 brickVoltage232_BMS05 65535 "SNA" ;
VAL_ 1988 brickVoltage233_BMS05 65535 "SNA" ;
VAL_ 1988 brickVoltage234_BMS05 65535 "SNA" ;
VAL_ 1988 brickVoltage235_BMS05 65535 "SNA" ;
VAL_ 1988 brickVoltage236_BMS05 65535 "SNA" ;
VAL_ 1988 brickVoltage237_BMS05 65535 "SNA" ;
VAL_ 1988 brickVoltage238_BMS05 65535 "SNA" ;
VAL_ 1988 brickVoltage239_BMS05 65535 "SNA" ;
VAL_ 1988 brickVoltage240_BMS05 65535 "SNA" ;
VAL_ 1988 brickVoltage241_BMS05 65535 "SNA" ;
VAL_ 1988 brickVoltage242_BMS05 65535 "SNA" ;
VAL_ 1988 brickVoltage243_BMS05 65535 "SNA" ;
VAL_ 1988 brickVoltage244_BMS05 65535 "SNA" ;
VAL_ 1988 brickVoltage245_BMS05 65535 "SNA" ;
VAL_ 1988 brickVoltage246_BMS05 65535 "SNA" ;
VAL_ 1988 brickVoltage247_BMS05 65535 "SNA" ;
VAL_ 1988 brickVoltage248_BMS05 65535 "SNA" ;
VAL_ 1988 brickVoltage249_BMS05 65535 "SNA" ;
VAL_ 1988 brickVoltage250_BMS05 65535 "SNA" ;
VAL_ 1988 brickVoltage251_BMS05 65535 "SNA" ;
VAL_ 1988 brickVoltage252_BMS05 65535 "SNA" ;
VAL_ 1988 brickVoltage253_BMS05 65535 "SNA" ;
VAL_ 1988 brickVoltage254_BMS05 65535 "SNA" ;
VAL_ 1988 brickVoltage255_BMS05 65535 "SNA" ;
VAL_ 1988 brickVoltage256_BMS05 65535 "SNA" ;
VAL_ 1988 brickVoltage257_BMS05 65535 "SNA" ;
VAL_ 1988 brickVoltage258_BMS05 65535 "SNA" ;
VAL_ 1988 brickVoltage259_BMS05 65535 "SNA" ;
VAL_ 1988 brickVoltage260_BMS05 65535 "SNA" ;
VAL_ 1988 brickVoltage261_BMS05 65535 "SNA" ;
VAL_ 1988 brickVoltage262_BMS05 65535 "SNA" ;
VAL_ 1988 brickVoltage263_BMS05 65535 "SNA" ;
VAL_ 1988 brickVoltage264_BMS05 65535 "SNA" ;
VAL_ 1988 brickVoltage265_BMS05 65535 "SNA" ;
VAL_ 1988 brickVoltage266_BMS05 65535 "SNA" ;
VAL_ 1988 brickVoltage267_BMS05 65535 "SNA" ;
VAL_ 1988 brickVoltage268_BMS05 65535 "SNA" ;
VAL_ 1988 brickVoltage269_BMS05 65535 "SNA" ;
VAL_ 1988 brickVoltage270_BMS05 65535 "SNA" ;
VAL_ 1988 brickVoltage271_BMS05 65535 "SNA" ;
VAL_ 1988 brickVoltage272_BMS05 65535 "SNA" ;
VAL_ 1988 brickVoltage273_BMS05 65535 "SNA" ;
VAL_ 1988 brickVoltage274_BMS05 65535 "SNA" ;
VAL_ 1988 brickVoltage275_BMS05 65535 "SNA" ;
VAL_ 1988 brickVoltage276_BMS05 65535 "SNA" ;
VAL_ 1988 brickVoltage277_BMS05 65535 "SNA" ;
VAL_ 1988 brickVoltage278_BMS05 65535 "SNA" ;
VAL_ 1988 brickVoltage279_BMS05 65535 "SNA" ;
VAL_ 1988 brickVoltage280_BMS05 65535 "SNA" ;
VAL_ 1988 brickVoltage281_BMS05 65535 "SNA" ;
VAL_ 1988 brickVoltage282_BMS05 65535 "SNA" ;
VAL_ 1988 brickVoltage283_BMS05 65535 "SNA" ;
VAL_ 1988 brickVoltage284_BMS05 65535 "SNA" ;
VAL_ 1988 brickVoltage285_BMS05 65535 "SNA" ;
VAL_ 1988 brickVoltage286_BMS05 65535 "SNA" ;
VAL_ 1988 brickVoltage287_BMS05 65535 "SNA" ;
VAL_ 1988 brickVoltage288_BMS05 65535 "SNA" ;
VAL_ 1988 brickVoltage289_BMS05 65535 "SNA" ;
VAL_ 1988 brickVoltage290_BMS05 65535 "SNA" ;
VAL_ 1988 brickVoltage291_BMS05 65535 "SNA" ;
VAL_ 1988 brickVoltage292_BMS05 65535 "SNA" ;
VAL_ 1988 brickVoltage293_BMS05 65535 "SNA" ;
VAL_ 1988 brickVoltage294_BMS05 65535 "SNA" ;
VAL_ 1988 brickVoltage295_BMS05 65535 "SNA" ;
VAL_ 1988 brickVoltage296_BMS05 65535 "SNA" ;
VAL_ 1988 brickVoltage297_BMS05 65535 "SNA" ;
VAL_ 1988 brickVoltage298_BMS05 65535 "SNA" ;
VAL_ 1988 brickVoltage299_BMS05 65535 "SNA" ;
VAL_ 1988 brickVoltage300_BMS05 65535 "SNA" ;
VAL_ 1988 moduleTemperature33_BMS05 255 "SNA" ;
VAL_ 1988 moduleTemperature34_BMS05 255 "SNA" ;
VAL_ 1988 moduleTemperature35_BMS05 255 "SNA" ;
VAL_ 1988 moduleTemperature36_BMS05 255 "SNA" ;
VAL_ 1988 moduleTemperature37_BMS05 255 "SNA" ;
VAL_ 1988 moduleTemperature38_BMS05 255 "SNA" ;
VAL_ 1988 moduleTemperature39_BMS05 255 "SNA" ;
VAL_ 1988 moduleTemperature40_BMS05 255 "SNA" ;
VAL_ 1988 moduleTemperature41_BMS05 255 "SNA" ;
VAL_ 1988 moduleTemperature42_BMS05 255 "SNA" ;
VAL_ 1988 moduleTemperature43_BMS05 255 "SNA" ;
VAL_ 1988 moduleTemperature44_BMS05 255 "SNA" ;
VAL_ 1988 moduleTemperature45_BMS05 255 "SNA" ;
VAL_ 1988 moduleTemperature46_BMS05 255 "SNA" ;
VAL_ 1988 moduleTemperature47_BMS05 255 "SNA" ;
VAL_ 1988 moduleTemperature48_BMS05 255 "SNA" ;
VAL_ 1988 moduleTemperature49_BMS05 255 "SNA" ;
VAL_ 1988 moduleTemperature50_BMS05 255 "SNA" ;
VAL_ 1988 moduleTemperature51_BMS05 255 "SNA" ;
VAL_ 1988 moduleTemperature52_BMS05 255 "SNA" ;
VAL_ 1988 moduleTemperature53_BMS05 255 "SNA" ;
VAL_ 1988 moduleTemperature54_BMS05 255 "SNA" ;
VAL_ 1988 moduleTemperature55_BMS05 255 "SNA" ;
VAL_ 1988 moduleTemperature56_BMS05 255 "SNA" ;
VAL_ 1988 moduleTemperature57_BMS05 255 "SNA" ;
VAL_ 1988 moduleTemperature58_BMS05 255 "SNA" ;
VAL_ 1988 moduleTemperature59_BMS05 255 "SNA" ;
VAL_ 1988 moduleTemperature60_BMS05 255 "SNA" ;
VAL_ 1988 moduleTemperature61_BMS05 255 "SNA" ;
VAL_ 1988 moduleTemperature62_BMS05 255 "SNA" ;
VAL_ 1988 moduleTemperature63_BMS05 255 "SNA" ;
VAL_ 1988 moduleTemperature64_BMS05 255 "SNA" ;
VAL_ 1988 moduleTemperature65_BMS05 255 "SNA" ;
VAL_ 1988 moduleTemperature66_BMS05 255 "SNA" ;
VAL_ 1988 moduleTemperature67_BMS05 255 "SNA" ;
VAL_ 1988 moduleTemperature68_BMS05 255 "SNA" ;
VAL_ 1988 moduleTemperature69_BMS05 255 "SNA" ;
VAL_ 1988 moduleTemperature70_BMS05 255 "SNA" ;
VAL_ 1988 moduleTemperature71_BMS05 255 "SNA" ;
VAL_ 1988 moduleTemperature72_BMS05 255 "SNA" ;
VAL_ 1988 moduleTemperature73_BMS05 255 "SNA" ;
VAL_ 1988 moduleTemperature74_BMS05 255 "SNA" ;
VAL_ 1988 moduleTemperature75_BMS05 255 "SNA" ;
VAL_ 1988 moduleTemperature76_BMS05 255 "SNA" ;
VAL_ 1988 moduleTemperature77_BMS05 255 "SNA" ;
VAL_ 1988 moduleTemperature78_BMS05 255 "SNA" ;
VAL_ 1988 moduleTemperature79_BMS05 255 "SNA" ;
VAL_ 1988 moduleTemperature80_BMS05 255 "SNA" ;
VAL_ 1988 moduleTemperature81_BMS05 255 "SNA" ;
VAL_ 1988 moduleTemperature82_BMS05 255 "SNA" ;
VAL_ 1988 moduleTemperature83_BMS05 255 "SNA" ;
VAL_ 1988 moduleTemperature84_BMS05 255 "SNA" ;
VAL_ 1988 moduleTemperature85_BMS05 255 "SNA" ;
VAL_ 1988 moduleTemperature86_BMS05 255 "SNA" ;
VAL_ 1988 moduleTemperature87_BMS05 255 "SNA" ;
VAL_ 1988 moduleTemperature88_BMS05 255 "SNA" ;
VAL_ 1988 moduleTemperature89_BMS05 255 "SNA" ;
VAL_ 1988 moduleTemperature90_BMS05 255 "SNA" ;
VAL_ 1988 moduleTemperature91_BMS05 255 "SNA" ;
VAL_ 1988 moduleTemperature92_BMS05 255 "SNA" ;
VAL_ 1988 moduleTemperature93_BMS05 255 "SNA" ;
VAL_ 1988 moduleTemperature94_BMS05 255 "SNA" ;
VAL_ 1988 moduleTemperature95_BMS05 255 "SNA" ;
VAL_ 1988 moduleTemperature96_BMS05 255 "SNA" ;
VAL_ 1988 moduleTemperature97_BMS05 255 "SNA" ;
VAL_ 1988 moduleTemperature98_BMS05 255 "SNA" ;
VAL_ 1988 moduleTemperature99_BMS05 255 "SNA" ;
VAL_ 1988 moduleTemperature100_BMS05 255 "SNA" ;
VAL_ 901 DEM319_HV_DISABLE_DURING_S_BMS06 3 "DEM_INVALID" 2 "DEM_FAILED" 1 "DEM_PASSED" 0 "DEM_NOTTESTED" ;
VAL_ 901 DEM318_HV_ENABLE_IMPLAUSIB_BMS06 3 "DEM_INVALID" 2 "DEM_FAILED" 1 "DEM_PASSED" 0 "DEM_NOTTESTED" ;
VAL_ 901 DEM317_STRING_SUSPECT_OPEN_BMS06 3 "DEM_INVALID" 2 "DEM_FAILED" 1 "DEM_PASSED" 0 "DEM_NOTTESTED" ;
VAL_ 901 DEM316_UNEXPCTD_BMS_ON_CAN_BMS06 3 "DEM_INVALID" 2 "DEM_FAILED" 1 "DEM_PASSED" 0 "DEM_NOTTESTED" ;
VAL_ 901 DEM315_HV_WITHSTAND_TESTS__BMS06 3 "DEM_INVALID" 2 "DEM_FAILED" 1 "DEM_PASSED" 0 "DEM_NOTTESTED" ;
VAL_ 901 DEM314_OBC_PILOT_ERROR_BMS06 3 "DEM_INVALID" 2 "DEM_FAILED" 1 "DEM_PASSED" 0 "DEM_NOTTESTED" ;
VAL_ 901 DEM313_OBC_PILOT_HIGH_BMS06 3 "DEM_INVALID" 2 "DEM_FAILED" 1 "DEM_PASSED" 0 "DEM_NOTTESTED" ;
VAL_ 901 DEM312_OBC_PROXIMITY_ERROR_BMS06 3 "DEM_INVALID" 2 "DEM_FAILED" 1 "DEM_PASSED" 0 "DEM_NOTTESTED" ;
VAL_ 901 DEM311_CTRS_END_OF_LIFE_WA_BMS06 3 "DEM_INVALID" 2 "DEM_FAILED" 1 "DEM_PASSED" 0 "DEM_NOTTESTED" ;
VAL_ 901 DEM310_BMSMIA_STRNGMSTR_AL_BMS06 3 "DEM_INVALID" 2 "DEM_FAILED" 1 "DEM_PASSED" 0 "DEM_NOTTESTED" ;
VAL_ 901 DEM309_VOLTAGE_BRICKOV_WAR_BMS06 3 "DEM_INVALID" 2 "DEM_FAILED" 1 "DEM_PASSED" 0 "DEM_NOTTESTED" ;
VAL_ 901 DEM308_PRESSURE_FLT_BMS06 3 "DEM_INVALID" 2 "DEM_FAILED" 1 "DEM_PASSED" 0 "DEM_NOTTESTED" ;
VAL_ 901 DEM307_PRESSURE_MIA_BMS06 3 "DEM_INVALID" 2 "DEM_FAILED" 1 "DEM_PASSED" 0 "DEM_NOTTESTED" ;
VAL_ 901 DEM306_SW_VERSION_MISMATCH_BMS06 3 "DEM_INVALID" 2 "DEM_FAILED" 1 "DEM_PASSED" 0 "DEM_NOTTESTED" ;
VAL_ 901 DEM305_MODULET_OVERTEMP_WA_BMS06 3 "DEM_INVALID" 2 "DEM_FAILED" 1 "DEM_PASSED" 0 "DEM_NOTTESTED" ;
VAL_ 901 DEM304_PCHG_OPENCIRCUIT_IN_BMS06 3 "DEM_INVALID" 2 "DEM_FAILED" 1 "DEM_PASSED" 0 "DEM_NOTTESTED" ;
VAL_ 901 DEM303_MODULET_UNDERTEMP_W_BMS06 3 "DEM_INVALID" 2 "DEM_FAILED" 1 "DEM_PASSED" 0 "DEM_NOTTESTED" ;
VAL_ 901 DEM302_MODULET_UT_BMS06 3 "DEM_INVALID" 2 "DEM_FAILED" 1 "DEM_PASSED" 0 "DEM_NOTTESTED" ;
VAL_ 901 DEM301_FUSI_LOCK_BMS06 3 "DEM_INVALID" 2 "DEM_FAILED" 1 "DEM_PASSED" 0 "DEM_NOTTESTED" ;
VAL_ 901 DEM300_DEBUG_SM_DISABLED_BMS06 3 "DEM_INVALID" 2 "DEM_FAILED" 1 "DEM_PASSED" 0 "DEM_NOTTESTED" ;
VAL_ 901 DEM299_5V_SENSOR_SUPPLY_OU_BMS06 3 "DEM_INVALID" 2 "DEM_FAILED" 1 "DEM_PASSED" 0 "DEM_NOTTESTED" ;
VAL_ 901 DEM298_IMPL_DRIVE_REQUEST_BMS06 3 "DEM_INVALID" 2 "DEM_FAILED" 1 "DEM_PASSED" 0 "DEM_NOTTESTED" ;
VAL_ 901 DEM297_PCHG2_OPENCIRCUIT_BMS06 3 "DEM_INVALID" 2 "DEM_FAILED" 1 "DEM_PASSED" 0 "DEM_NOTTESTED" ;
VAL_ 901 DEM296_CTRSAUX_IMPLAUSIBLE_BMS06 3 "DEM_INVALID" 2 "DEM_FAILED" 1 "DEM_PASSED" 0 "DEM_NOTTESTED" ;
VAL_ 901 DEM295_CTRSAUX_LINKV_UNSAF_BMS06 3 "DEM_INVALID" 2 "DEM_FAILED" 1 "DEM_PASSED" 0 "DEM_NOTTESTED" ;
VAL_ 901 DEM294_CANRX_PT_EMERGENCY_BMS06 3 "DEM_INVALID" 2 "DEM_FAILED" 1 "DEM_PASSED" 0 "DEM_NOTTESTED" ;
VAL_ 901 DEM293_SBC_LDT_IMPLAUSIBLE_BMS06 3 "DEM_INVALID" 2 "DEM_FAILED" 1 "DEM_PASSED" 0 "DEM_NOTTESTED" ;
VAL_ 901 DEM292_NUM_EXPECTED_STRING_BMS06 3 "DEM_INVALID" 2 "DEM_FAILED" 1 "DEM_PASSED" 0 "DEM_NOTTESTED" ;
VAL_ 901 DEM291_NUM_EXPECTED_STRING_BMS06 3 "DEM_INVALID" 2 "DEM_FAILED" 1 "DEM_PASSED" 0 "DEM_NOTTESTED" ;
VAL_ 901 DEM290_CMB_ONBOARD_DEFECT_BMS06 3 "DEM_INVALID" 2 "DEM_FAILED" 1 "DEM_PASSED" 0 "DEM_NOTTESTED" ;
VAL_ 901 DEM289_TEMP_STATE_LATCHED_BMS06 3 "DEM_INVALID" 2 "DEM_FAILED" 1 "DEM_PASSED" 0 "DEM_NOTTESTED" ;
VAL_ 901 DEM288_CURR_STATE_LATCHED_BMS06 3 "DEM_INVALID" 2 "DEM_FAILED" 1 "DEM_PASSED" 0 "DEM_NOTTESTED" ;
VAL_ 965 balancingInDriveTimer_BMS06 65535 "SNA" ;
VAL_ 965 SOCRestPolarization_BMS06 255 "SNA" ;
VAL_ 965 CoolantSensorState_BMS06 3 "OIL_OK" 2 "SENSOR_FAILURE" 1 "WATER_DETECTED" 0 "SENSOR_CAN_MIA" ;
VAL_ 965 temperatureModelOffset_BMS06 255 "SNA" ;
VAL_ 965 SOHCMinBrickHighEst_BMS06 255 "SNA" ;
VAL_ 965 SOHCMaxBrickHighEst_BMS06 255 "SNA" ;
VAL_ 965 regenCurrOpLkyBktThrs1_BMS06 255 "SNA" ;
VAL_ 965 dischargeCurrOpLkyBktThrs1_BMS06 255 "SNA" ;
VAL_ 965 regenCurrentOpLoadValue_BMS06 255 "SNA" ;
VAL_ 965 dischargeCurrOpLoadValue_BMS06 255 "SNA" ;
VAL_ 965 minBrickVoltageLimit_BMS06 65535 "SNA" ;
VAL_ 965 currentModule3Integral_BMS06 65535 "SNA" ;
VAL_ 965 currentModule2Integral_BMS06 65535 "SNA" ;
VAL_ 965 currentModule1Integral_BMS06 65535 "SNA" ;
VAL_ 965 currentModuleMin_BMS06 65535 "SNA" ;
VAL_ 965 currentModuleMax_BMS06 65535 "SNA" ;
VAL_ 965 maxBrickVoltageSync_BMS06 65535 "SNA" ;
VAL_ 965 minBrickVoltageSync_BMS06 65535 "SNA" ;
VAL_ 965 SOHCMinBrickLowEst_BMS06 255 "SNA" ;
VAL_ 965 SOHCMaxBrickLowEst_BMS06 255 "SNA" ;
VAL_ 965 gradLimSOC_BMS06 65535 "SNA" ;
VAL_ 965 SOCRecalSlowOp_BMS06 255 "SNA" ;
VAL_ 965 SOHCMinIndex_BMS06 65535 "SNA" ;
VAL_ 965 SOHCMaxIndex_BMS06 65535 "SNA" ;
VAL_ 965 SOHRMinRegen_BMS06 255 "SNA" ;
VAL_ 965 SOHRMinDchg_BMS06 255 "SNA" ;
VAL_ 965 SOHRMeanRegen_BMS06 255 "SNA" ;
VAL_ 965 SOHRMeanDchg_BMS06 255 "SNA" ;
VAL_ 965 SOHRMaxRegen_BMS06 255 "SNA" ;
VAL_ 965 SOHRMaxDchg_BMS06 255 "SNA" ;
VAL_ 965 SOHCMin_BMS06 255 "SNA" ;
VAL_ 965 SOHCMean_BMS06 255 "SNA" ;
VAL_ 965 SOHCMax_BMS06 255 "SNA" ;
VAL_ 965 ppRegenCurrLimitPredShort_BMS06 255 "SNA" ;
VAL_ 965 ppRegenCurrLimitPredLong_BMS06 255 "SNA" ;
VAL_ 965 ppDchgCurrLimitPredShort_BMS06 255 "SNA" ;
VAL_ 965 ppDchgCurrLimitPredLong_BMS06 255 "SNA" ;
VAL_ 965 ppPolarizationV_BMS06 65535 "SNA" ;
VAL_ 965 SOCRecalMinOCVEst_BMS06 65535 "SNA" ;
VAL_ 965 SOCRecalMaxOCVEst_BMS06 65535 "SNA" ;
VAL_ 965 SOCRecalMinSOCUpp_BMS06 255 "SNA" ;
VAL_ 965 SOCRecalMinSOCLow_BMS06 255 "SNA" ;
VAL_ 965 SOCRecalMinSOC_BMS06 255 "SNA" ;
VAL_ 965 SOCRecalMaxSOCUpp_BMS06 255 "SNA" ;
VAL_ 965 SOCRecalMaxSOCLow_BMS06 255 "SNA" ;
VAL_ 965 SOCRecalMaxSOC_BMS06 255 "SNA" ;
VAL_ 965 ppNewtonStepsRegen_BMS06 7 "SNA" ;
VAL_ 965 ppNewtonStepsDchg_BMS06 7 "SNA" ;
VAL_ 965 ppNewtonRegenVRes_BMS06 255 "SNA" ;
VAL_ 965 ppNewtonDchgVRes_BMS06 255 "SNA" ;
VAL_ 965 ppMinModelAlphaTarget_BMS06 255 "SNA" ;
VAL_ 965 ppMaxModelAlphaTarget_BMS06 255 "SNA" ;
VAL_ 965 ppLearningTauRegen_BMS06 65535 "SNA" ;
VAL_ 965 ppLearningCriterionDyn_BMS06 255 "SNA" ;
VAL_ 965 ppLearningCriterionAbs_BMS06 255 "SNA" ;
VAL_ 965 ppLearningCriterionJoin_BMS06 255 "SNA" ;
VAL_ 965 currentRedundant_BMS06 65535 "SNA" ;
VAL_ 965 currentModule3_BMS06 65535 "SNA" ;
VAL_ 965 currentModule2_BMS06 65535 "SNA" ;
VAL_ 965 currentModule1_BMS06 65535 "SNA" ;
VAL_ 965 ppMeanDchgIntRes_BMS06 65535 "SNA" ;
VAL_ 965 ppMinModelLowpassV_BMS06 65535 "SNA" ;
VAL_ 965 ppMaxModelVoltageIndex_BMS06 65535 "SNA" ;
VAL_ 965 ppMaxModelLowpassV_BMS06 65535 "SNA" ;
VAL_ 965 ppLearningTauDischarge_BMS06 65535 "SNA" ;
VAL_ 965 ppMaxRegenAlpha_BMS06 255 "SNA" ;
VAL_ 965 ppMaxModelledV_BMS06 65535 "SNA" ;
VAL_ 965 ppMinDchgAlpha_BMS06 255 "SNA" ;
VAL_ 965 ppMinModelledV_BMS06 65535 "SNA" ;
VAL_ 965 debugSlowMpex2_BMS06 0 "S00" 1 "S01" 2 "S02" 3 "S03" 4 "S04" 5 "S05" 6 "S06" 7 "S07" 8 "S08" 9 "S09" 10 "S10" 11 "S11" 12 "S12" 13 "S13" 14 "S14" 15 "S15" 16 "S16" 17 "S17" 18 "S18" 19 "S19" 20 "S20" 21 "S21" 22 "S22" 23 "S23" 24 "S24" 25 "S25" ;
VAL_ 965 ppRegenCurrPredShort_BMS06 65535 "SNA" ;
VAL_ 965 ppDischgCurrPredLong_BMS06 65535 "SNA" ;
VAL_ 965 ppDischgCurrPredShort_BMS06 65535 "SNA" ;
VAL_ 965 ppRegenCurrPredLong_BMS06 65535 "SNA" ;
VAL_ 965 ppRegenVPredShort_BMS06 65535 "SNA" ;
VAL_ 965 ppDischgVPredShort_BMS06 65535 "SNA" ;
VAL_ 965 ppRegenVPredLong_BMS06 65535 "SNA" ;
VAL_ 965 ppDischgVPredLong_BMS06 65535 "SNA" ;
VAL_ 965 SOHDeltaSOCCoulomb_BMS06 65535 "SNA" ;
VAL_ 965 SOHAbsDeltaSOCCoulomb_BMS06 65535 "SNA" ;
VAL_ 965 SOHLastOCVRecalMinSOC_BMS06 255 "SNA" ;
VAL_ 965 SOHbalancingTimeMinSOH_BMS06 255 "SNA" ;
VAL_ 1797 chargerDCOutV_BMS06 65535 "SNA" ;
VAL_ 1797 chargerProximity_BMS06 255 "SNA" ;
VAL_ 1797 chargerPilot_BMS06 255 "SNA" ;
VAL_ 1797 chargerCurrAvail_BMS06 255 "SNA" ;
VAL_ 1797 chargerCtrOn_BMS06 1 "TRUE" 0 "FALSE" ;
VAL_ 1797 chargerOn_BMS06 1 "TRUE" 0 "FALSE" ;
VAL_ 1797 debugFastMpex2_BMS06 0 "F00" 1 "F01" 2 "F02" 3 "F03" 4 "F04" 5 "F05" 6 "F06" 7 "F07" 8 "F08" 9 "F09" 10 "F10" 11 "F11" 12 "F12" 13 "F13" 14 "F14" 15 "F15" ;
VAL_ 1797 posPackDbg_BMS06 65535 "SNA" ;
VAL_ 1797 negPackDbg_BMS06 65535 "SNA" ;
VAL_ 1797 packVoltageHVMeas_BMS06 65535 "SNA" ;
VAL_ 1861 SOHRecentChange_BMS06 255 "SNA" ;
VAL_ 1861 SOHConvergenceIndicator_BMS06 255 "SNA" ;
VAL_ 1861 SOHConvergenceCounter_BMS06 255 "SNA" ;
VAL_ 1861 SOHMinFiltered_BMS06 255 "SNA" ;
VAL_ 1861 medianModuleTempGrp2_BMS06 255 "SNA" ;
VAL_ 1861 medianModuleTempGrp1_BMS06 255 "SNA" ;
VAL_ 1861 coolantWarningtAlert_BMS06 3 "SNA" 2 "COOLANT_FLOOD_WARNING" 0 "COOLANT_NOWARNING" 1 "COOLANT_MOISTURE_WARNING" ;
VAL_ 1861 coolantFaultAlert_BMS06 3 "SNA" 2 "COOLANT_FLOOD_FAULT" 0 "COOLANT_NOFAULT" 1 "COOLANT_MOISTURE_FAULT" ;
VAL_ 1861 hvilShutdownStrategy_BMS06 4 "Strategy_4" 3 "Strategy_3" 2 "Strategy_2" 1 "Strategy_1" 0 "Strategy_0" ;
VAL_ 1861 J1939_nmState 3 "J1939_NM_INACTIVE" 2 "J1939_NM_ACTIVE" 1 "J1939_NM_STARTUP" 0 "J1939_NM_INIT" ;
VAL_ 1861 PrechargeXCapMin_BMS06 65535 "SNA" ;
VAL_ 1861 LimpHomeTimeOut_BMS06 65535 "SNA" ;
VAL_ 1861 hvWithstandTests_BMS06 255 "SNA" ;
VAL_ 1861 aux3prechargeState_BMS06 15 "CTR_PRCHG_NEG_OPEN" 13 "CTR_PRCHG_POS_WELD_CHECK" 12 "CTR_PRCHG_PRE_COND_CHECK" 11 "CTR_PRCHG_NEG2_WELD_CHECK" 10 "CTR_PRCHG_CLOSEMID" 9 "CTR_PRCHG_CLOSEAUX" 8 "CTR_PRCHG_FAILED" 7 "CTR_PRCHG_COMPLETE" 6 "CTR_PRCHG_CLOSE_POS" 5 "CTR_PRCHG_MONITOR_VOLTAGE" 4 "CTR_PRCHG_CLOSE_NEG" 3 "CTR_PRCHG_NEG_WELD_CHECK" 2 "CTR_PRCHG_CLOSE_RELAY" 1 "CTR_PRCHG_WELD_CHECK" 0 "CTR_PRCHG_OFF" ;
VAL_ 1861 aux2prechargeState_BMS06 15 "CTR_PRCHG_NEG_OPEN" 13 "CTR_PRCHG_POS_WELD_CHECK" 12 "CTR_PRCHG_PRE_COND_CHECK" 11 "CTR_PRCHG_NEG2_WELD_CHECK" 10 "CTR_PRCHG_CLOSEMID" 9 "CTR_PRCHG_CLOSEAUX" 8 "CTR_PRCHG_FAILED" 7 "CTR_PRCHG_COMPLETE" 6 "CTR_PRCHG_CLOSE_POS" 5 "CTR_PRCHG_MONITOR_VOLTAGE" 4 "CTR_PRCHG_CLOSE_NEG" 3 "CTR_PRCHG_NEG_WELD_CHECK" 2 "CTR_PRCHG_CLOSE_RELAY" 1 "CTR_PRCHG_WELD_CHECK" 0 "CTR_PRCHG_OFF" ;
VAL_ 1861 aux1prechargeState_BMS06 15 "CTR_PRCHG_NEG_OPEN" 13 "CTR_PRCHG_POS_WELD_CHECK" 12 "CTR_PRCHG_PRE_COND_CHECK" 11 "CTR_PRCHG_NEG2_WELD_CHECK" 10 "CTR_PRCHG_CLOSEMID" 9 "CTR_PRCHG_CLOSEAUX" 8 "CTR_PRCHG_FAILED" 7 "CTR_PRCHG_COMPLETE" 6 "CTR_PRCHG_CLOSE_POS" 5 "CTR_PRCHG_MONITOR_VOLTAGE" 4 "CTR_PRCHG_CLOSE_NEG" 3 "CTR_PRCHG_NEG_WELD_CHECK" 2 "CTR_PRCHG_CLOSE_RELAY" 1 "CTR_PRCHG_WELD_CHECK" 0 "CTR_PRCHG_OFF" ;
VAL_ 1861 auxLinkVoltage_BMS06 65535 "SNA" ;
VAL_ 1861 rangeRequestIgnoreVehicle 255 "NO_COMMAND" 1 "IGNORE" 0 "DO_NOT_IGNORE" ;
VAL_ 1861 rangeRequestEepromValue 255 "NO_COMMAND" 15 "RANGE_INVALID" 14 "RANGE_MAXIMUM" 13 "RANGE_MODESOH8" 12 "RANGE_MODESOH7" 11 "RANGE_MODESOH6" 10 "RANGE_MODESOH5" 9 "RANGE_MODESOH4" 8 "RANGE_MODESOH3" 7 "RANGE_MODESOH2" 6 "RANGE_MODESOH1" 5 "RANGE_MODE407" 4 "RANGE_MODE405" 3 "RANGE_MODE4175" 2 "RANGE_MODE415" 1 "RANGE_LIMITED" 0 "RANGE_SHIPPING" ;
VAL_ 1861 pressure2_BMS06 255 "SNA" ;
VAL_ 1861 calibration_version_BMS06 255 "SNA" ;
VAL_ 1861 currentLowTimer_BMS06 65535 "SNA" ;
VAL_ 1861 auxCntrrOpenUnderLoadCntr_BMS06 65535 "SNA" ;
VAL_ 1861 rabbitContactorState_BMS06 5 "FAILURE" 4 "CLOSE" 3 "EXT_ISO_TEST" 2 "AUX_CLOSE" 1 "INT_ISO_TEST" 0 "OPEN" ;
VAL_ 1861 analogIsenseSupplyCurr_BMS06 255 "SNA" ;
VAL_ 1861 pumpSpeedReqCoolPrfmc_BMS06 255 "SNA" ;
VAL_ 1861 microsarOs_IdleTask_OsCr0_BMS06 255 "SNA" ;
VAL_ 1861 microsarOs_BswTask_BMS06 255 "SNA" ;
VAL_ 1861 microsarOs_InitTask_BMS06 255 "SNA" ;
VAL_ 1861 microsarOs_ApplTask_1Hz_BMS06 255 "SNA" ;
VAL_ 1861 microsarOs_ApplTask_10Hz_BMS06 255 "SNA" ;
VAL_ 1861 microsarOs_ApplTask_100Hz_BMS06 255 "SNA" ;
VAL_ 1861 microsarOs_ApplLowTask_BMS06 255 "SNA" ;
VAL_ 1861 microsarOs_ApplLateInit_BMS06 255 "SNA" ;
VAL_ 1861 microsarOs_ApplHighTask_BMS06 255 "SNA" ;
VAL_ 1861 microsarOs_ApplEarlyInit_BMS06 255 "SNA" ;
VAL_ 1861 appTaskBSWMaxDuration_BMS06 255 "SNA" ;
VAL_ 1861 appTaskApplHighMaxDuration_BMS06 255 "SNA" ;
VAL_ 1861 appTask1HzMaxDuration_BMS06 255 "SNA" ;
VAL_ 1861 appTask100HzMaxDuration_BMS06 255 "SNA" ;
VAL_ 1861 appTask10HzMaxDuration_BMS06 255 "SNA" ;
VAL_ 1861 appTask100HzDuration_BMS06 255 "SNA" ;
VAL_ 1861 appTask10HzDuration_BMS06 255 "SNA" ;
VAL_ 1861 appTask1HzDuration_BMS06 255 "SNA" ;
VAL_ 1861 appTaskBSWDuration_BMS06 255 "SNA" ;
VAL_ 1861 appTaskApplHighDuration_BMS06 255 "SNA" ;
VAL_ 1861 iumprMaxRatioDTCId_BMS06 0 "SNA" ;
VAL_ 1861 iumprMaxRatio_BMS06 0 "SNA" ;
VAL_ 1861 iumprMinRatioDTCId_BMS06 0 "SNA" ;
VAL_ 1861 iumprMinRatio_BMS06 0 "SNA" ;
VAL_ 1861 fluidLvlCount_BMS06 255 "SNA" ;
VAL_ 1861 fluidLvlSensr2_BMS06 3 "FLUIDLEVEL_ERROR" 2 "FLUIDLEVEL_OIL" 1 "FLUIDLEVEL_AIR" 0 "FLUIDLEVEL_SNA" ;
VAL_ 1861 fluidLvlSensr1_BMS06 3 "FLUIDLEVEL_ERROR" 2 "FLUIDLEVEL_OIL" 1 "FLUIDLEVEL_AIR" 0 "FLUIDLEVEL_SNA" ;
VAL_ 1861 pumpSpeedReqVhcleSpeed_BMS06 255 "SNA" ;
VAL_ 1861 appTaskBSWCpuUsage_BMS06 255 "SNA" ;
VAL_ 1861 appTask200HzCpuUsage_BMS06 255 "SNA" ;
VAL_ 1861 pyroState_BMS06 7 "PYRO_FIRE" 6 "PYRO_DIAG_PASS" 5 "PYRO_DIAG_FAIL" 4 "PYRO_DIAG_LS_ON" 3 "PYRO_DIAG_OPEN" 2 "PYRO_DIAG_HS_ON" 1 "PYRO_DIAG_INIT" 0 "PYRO_INACTIVE" ;
VAL_ 1861 ecuSerialNrChar15_BMS06 90 "'Z'" 89 "'Y'" 88 "'X'" 87 "'W'" 86 "'V'" 85 "'U'" 84 "'T'" 83 "'S'" 82 "'R'" 81 "'Q'" 80 "'P'" 79 "'O'" 78 "'N'" 77 "'M'" 76 "'L'" 75 "'K'" 74 "'J'" 73 "'I'" 72 "'H'" 71 "'G'" 70 "'F'" 69 "'E'" 68 "'D'" 67 "'C'" 66 "'B'" 65 "'A'" 57 "'9'" 56 "'8'" 55 "'7'" 54 "'6'" 53 "'5'" 52 "'4'" 51 "'3'" 50 "'2'" 49 "'1'" 48 "'0'" ;
VAL_ 1861 ecuSerialNrChar14_BMS06 90 "'Z'" 89 "'Y'" 88 "'X'" 87 "'W'" 86 "'V'" 85 "'U'" 84 "'T'" 83 "'S'" 82 "'R'" 81 "'Q'" 80 "'P'" 79 "'O'" 78 "'N'" 77 "'M'" 76 "'L'" 75 "'K'" 74 "'J'" 73 "'I'" 72 "'H'" 71 "'G'" 70 "'F'" 69 "'E'" 68 "'D'" 67 "'C'" 66 "'B'" 65 "'A'" 57 "'9'" 56 "'8'" 55 "'7'" 54 "'6'" 53 "'5'" 52 "'4'" 51 "'3'" 50 "'2'" 49 "'1'" 48 "'0'" ;
VAL_ 1861 ecuSerialNrChar13_BMS06 90 "'Z'" 89 "'Y'" 88 "'X'" 87 "'W'" 86 "'V'" 85 "'U'" 84 "'T'" 83 "'S'" 82 "'R'" 81 "'Q'" 80 "'P'" 79 "'O'" 78 "'N'" 77 "'M'" 76 "'L'" 75 "'K'" 74 "'J'" 73 "'I'" 72 "'H'" 71 "'G'" 70 "'F'" 69 "'E'" 68 "'D'" 67 "'C'" 66 "'B'" 65 "'A'" 57 "'9'" 56 "'8'" 55 "'7'" 54 "'6'" 53 "'5'" 52 "'4'" 51 "'3'" 50 "'2'" 49 "'1'" 48 "'0'" ;
VAL_ 1861 ecuSerialNrChar12_BMS06 90 "'Z'" 89 "'Y'" 88 "'X'" 87 "'W'" 86 "'V'" 85 "'U'" 84 "'T'" 83 "'S'" 82 "'R'" 81 "'Q'" 80 "'P'" 79 "'O'" 78 "'N'" 77 "'M'" 76 "'L'" 75 "'K'" 74 "'J'" 73 "'I'" 72 "'H'" 71 "'G'" 70 "'F'" 69 "'E'" 68 "'D'" 67 "'C'" 66 "'B'" 65 "'A'" 57 "'9'" 56 "'8'" 55 "'7'" 54 "'6'" 53 "'5'" 52 "'4'" 51 "'3'" 50 "'2'" 49 "'1'" 48 "'0'" ;
VAL_ 1861 ecuSerialNrChar11_BMS06 90 "'Z'" 89 "'Y'" 88 "'X'" 87 "'W'" 86 "'V'" 85 "'U'" 84 "'T'" 83 "'S'" 82 "'R'" 81 "'Q'" 80 "'P'" 79 "'O'" 78 "'N'" 77 "'M'" 76 "'L'" 75 "'K'" 74 "'J'" 73 "'I'" 72 "'H'" 71 "'G'" 70 "'F'" 69 "'E'" 68 "'D'" 67 "'C'" 66 "'B'" 65 "'A'" 57 "'9'" 56 "'8'" 55 "'7'" 54 "'6'" 53 "'5'" 52 "'4'" 51 "'3'" 50 "'2'" 49 "'1'" 48 "'0'" ;
VAL_ 1861 ecuSerialNrChar10_BMS06 90 "'Z'" 89 "'Y'" 88 "'X'" 87 "'W'" 86 "'V'" 85 "'U'" 84 "'T'" 83 "'S'" 82 "'R'" 81 "'Q'" 80 "'P'" 79 "'O'" 78 "'N'" 77 "'M'" 76 "'L'" 75 "'K'" 74 "'J'" 73 "'I'" 72 "'H'" 71 "'G'" 70 "'F'" 69 "'E'" 68 "'D'" 67 "'C'" 66 "'B'" 65 "'A'" 57 "'9'" 56 "'8'" 55 "'7'" 54 "'6'" 53 "'5'" 52 "'4'" 51 "'3'" 50 "'2'" 49 "'1'" 48 "'0'" ;
VAL_ 1861 ecuSerialNrChar09_BMS06 90 "'Z'" 89 "'Y'" 88 "'X'" 87 "'W'" 86 "'V'" 85 "'U'" 84 "'T'" 83 "'S'" 82 "'R'" 81 "'Q'" 80 "'P'" 79 "'O'" 78 "'N'" 77 "'M'" 76 "'L'" 75 "'K'" 74 "'J'" 73 "'I'" 72 "'H'" 71 "'G'" 70 "'F'" 69 "'E'" 68 "'D'" 67 "'C'" 66 "'B'" 65 "'A'" 57 "'9'" 56 "'8'" 55 "'7'" 54 "'6'" 53 "'5'" 52 "'4'" 51 "'3'" 50 "'2'" 49 "'1'" 48 "'0'" ;
VAL_ 1861 ecuSerialNrChar08_BMS06 90 "'Z'" 89 "'Y'" 88 "'X'" 87 "'W'" 86 "'V'" 85 "'U'" 84 "'T'" 83 "'S'" 82 "'R'" 81 "'Q'" 80 "'P'" 79 "'O'" 78 "'N'" 77 "'M'" 76 "'L'" 75 "'K'" 74 "'J'" 73 "'I'" 72 "'H'" 71 "'G'" 70 "'F'" 69 "'E'" 68 "'D'" 67 "'C'" 66 "'B'" 65 "'A'" 57 "'9'" 56 "'8'" 55 "'7'" 54 "'6'" 53 "'5'" 52 "'4'" 51 "'3'" 50 "'2'" 49 "'1'" 48 "'0'" ;
VAL_ 1861 ecuSerialNrChar07_BMS06 90 "'Z'" 89 "'Y'" 88 "'X'" 87 "'W'" 86 "'V'" 85 "'U'" 84 "'T'" 83 "'S'" 82 "'R'" 81 "'Q'" 80 "'P'" 79 "'O'" 78 "'N'" 77 "'M'" 76 "'L'" 75 "'K'" 74 "'J'" 73 "'I'" 72 "'H'" 71 "'G'" 70 "'F'" 69 "'E'" 68 "'D'" 67 "'C'" 66 "'B'" 65 "'A'" 57 "'9'" 56 "'8'" 55 "'7'" 54 "'6'" 53 "'5'" 52 "'4'" 51 "'3'" 50 "'2'" 49 "'1'" 48 "'0'" ;
VAL_ 1861 ecuSerialNrChar06_BMS06 90 "'Z'" 89 "'Y'" 88 "'X'" 87 "'W'" 86 "'V'" 85 "'U'" 84 "'T'" 83 "'S'" 82 "'R'" 81 "'Q'" 80 "'P'" 79 "'O'" 78 "'N'" 77 "'M'" 76 "'L'" 75 "'K'" 74 "'J'" 73 "'I'" 72 "'H'" 71 "'G'" 70 "'F'" 69 "'E'" 68 "'D'" 67 "'C'" 66 "'B'" 65 "'A'" 57 "'9'" 56 "'8'" 55 "'7'" 54 "'6'" 53 "'5'" 52 "'4'" 51 "'3'" 50 "'2'" 49 "'1'" 48 "'0'" ;
VAL_ 1861 ecuSerialNrChar05_BMS06 90 "'Z'" 89 "'Y'" 88 "'X'" 87 "'W'" 86 "'V'" 85 "'U'" 84 "'T'" 83 "'S'" 82 "'R'" 81 "'Q'" 80 "'P'" 79 "'O'" 78 "'N'" 77 "'M'" 76 "'L'" 75 "'K'" 74 "'J'" 73 "'I'" 72 "'H'" 71 "'G'" 70 "'F'" 69 "'E'" 68 "'D'" 67 "'C'" 66 "'B'" 65 "'A'" 57 "'9'" 56 "'8'" 55 "'7'" 54 "'6'" 53 "'5'" 52 "'4'" 51 "'3'" 50 "'2'" 49 "'1'" 48 "'0'" ;
VAL_ 1861 analogGPIO1Current_BMS06 255 "SNA" ;
VAL_ 1861 analogGPIO1Volt_BMS06 255 "SNA" ;
VAL_ 1861 analogGPIO2Current_BMS06 255 "SNA" ;
VAL_ 1861 analogGPIO2Volt_BMS06 255 "SNA" ;
VAL_ 1861 pumpSpeedReqLoadValue_BMS06 255 "SNA" ;
VAL_ 1861 ssaRTMonth_BMS06 255 "SNA" ;
VAL_ 1861 ssaRTDay_BMS06 255 "SNA" ;
VAL_ 1861 appTask50HzStackUsage_BMS06 255 "SNA" ;
VAL_ 1861 OBDMILRequested_BMS06 3 "MIL_SNA" 1 "MIL_ON" 0 "MIL_OFF" ;
VAL_ 1861 OBDConfirmedDTCsCount_BMS06 255 "SNA" ;
VAL_ 1861 OBDFirstConfirmedDTC_BMS06 255 "SNA" ;
VAL_ 1861 OBDPermanentDTCCount_BMS06 255 "SNA" ;
VAL_ 1861 OBDFirstPermanentDTC_BMS06 255 "SNA" ;
VAL_ 1861 nmStartupReason_BMS06 15 "NM_STARTUP_INVALID" 7 "NM_STARTUP_TESTERPRESENT" 6 "NM_STARTUP_RQ" 5 "NM_STARTUP_CAN" 4 "NM_STARTUP_THERMALEVENT" 3 "NM_STARTUP_AUXCONTACTORS" 2 "NM_STARTUP_CONTACTORS" 1 "NM_STARTUP_KEY" 0 "NM_STARTUP_NOSTARTUP" ;
VAL_ 1861 contactorType_BMS06 15 "SNA" 1 "GV240_12V" 0 "CTR_TYPE_CALIBRATION (GV240_24V)" ;
VAL_ 1861 activeIsoTestDuration_BMS06 255 "SNA" ;
VAL_ 1861 balancingState_BMS06 6 "BALANCING_OFF_TEMP_SHUTDOWN" 5 "BALANCING_OFF_VOLTAGE_SHUTDOWN" 4 "BALANCING_ON_DCM_EEPROM" 3 "BALANCING_ON_DCM_BRICK" 2 "BALANCING_ON_DCM_PATTERN" 1 "BALANCING_ON_ME_APP" 0 "BALANCING_OFF" ;
VAL_ 1861 chronoStackWrCnt_BMS06 -1 "SNA" ;
VAL_ 1861 wakeReason_BMS06 6 "ECU_WAKEREASON_MCUWDG" 14 "ECU_WAKEREASON_INIT" 15 "ECU_WAKEREASON_UNKNOWN" 5 "ECU_WAKEREASON_AUTO" 4 "ECU_WAKEREASON_POR" 3 "ECU_WAKEREASON_CLOCK" 2 "ECU_WAKEREASON_PRESSURE" 1 "ECU_WAKEREASON_CAN" 0 "ECU_WAKEREASON_KEY" ;
VAL_ 1861 coolantOutletTemperature_BMS06 255 "SNA" ;
VAL_ 1861 coolantInletTemperature_BMS06 255 "SNA" ;
VAL_ 1861 variantCodingCount_BMS06 65535 "SNA" ;
VAL_ 1861 SWVersionCusApp_BMS06 -1 "SNA" ;
VAL_ 1861 contactorOpenRequest_BMS06 15 "CTR_OPEN_INVALID" 1 "CTR_OPEN_IMMEDIATE" 0 "CTR_OPEN_FAST " ;
VAL_ 1861 maxBrickVoltageChargeLimit_BMS06 65535 "SNA" ;
VAL_ 1861 desiccantTimer_BMS06 -1 "SNA" ;
VAL_ 1861 batSwitchOpenReason_BMS06 65535 "SNA" ;
VAL_ 1861 balancingTime_BMS06 65535 "SNA" ;
VAL_ 1861 ecuSerialNrChar01_BMS06 90 "'Z'" 89 "'Y'" 88 "'X'" 87 "'W'" 86 "'V'" 85 "'U'" 84 "'T'" 83 "'S'" 82 "'R'" 81 "'Q'" 80 "'P'" 79 "'O'" 78 "'N'" 77 "'M'" 76 "'L'" 75 "'K'" 74 "'J'" 73 "'I'" 72 "'H'" 71 "'G'" 70 "'F'" 69 "'E'" 68 "'D'" 67 "'C'" 66 "'B'" 65 "'A'" 57 "'9'" 56 "'8'" 55 "'7'" 54 "'6'" 53 "'5'" 52 "'4'" 51 "'3'" 50 "'2'" 49 "'1'" 48 "'0'" ;
VAL_ 1861 ecuSerialNrChar02_BMS06 90 "'Z'" 89 "'Y'" 88 "'X'" 87 "'W'" 86 "'V'" 85 "'U'" 84 "'T'" 83 "'S'" 82 "'R'" 81 "'Q'" 80 "'P'" 79 "'O'" 78 "'N'" 77 "'M'" 76 "'L'" 75 "'K'" 74 "'J'" 73 "'I'" 72 "'H'" 71 "'G'" 70 "'F'" 69 "'E'" 68 "'D'" 67 "'C'" 66 "'B'" 65 "'A'" 57 "'9'" 56 "'8'" 55 "'7'" 54 "'6'" 53 "'5'" 52 "'4'" 51 "'3'" 50 "'2'" 49 "'1'" 48 "'0'" ;
VAL_ 1861 ecuSerialNrChar03_BMS06 90 "'Z'" 89 "'Y'" 88 "'X'" 87 "'W'" 86 "'V'" 85 "'U'" 84 "'T'" 83 "'S'" 82 "'R'" 81 "'Q'" 80 "'P'" 79 "'O'" 78 "'N'" 77 "'M'" 76 "'L'" 75 "'K'" 74 "'J'" 73 "'I'" 72 "'H'" 71 "'G'" 70 "'F'" 69 "'E'" 68 "'D'" 67 "'C'" 66 "'B'" 65 "'A'" 57 "'9'" 56 "'8'" 55 "'7'" 54 "'6'" 53 "'5'" 52 "'4'" 51 "'3'" 50 "'2'" 49 "'1'" 48 "'0'" ;
VAL_ 1861 ecuSerialNrChar04_BMS06 90 "'Z'" 89 "'Y'" 88 "'X'" 87 "'W'" 86 "'V'" 85 "'U'" 84 "'T'" 83 "'S'" 82 "'R'" 81 "'Q'" 80 "'P'" 79 "'O'" 78 "'N'" 77 "'M'" 76 "'L'" 75 "'K'" 74 "'J'" 73 "'I'" 72 "'H'" 71 "'G'" 70 "'F'" 69 "'E'" 68 "'D'" 67 "'C'" 66 "'B'" 65 "'A'" 57 "'9'" 56 "'8'" 55 "'7'" 54 "'6'" 53 "'5'" 52 "'4'" 51 "'3'" 50 "'2'" 49 "'1'" 48 "'0'" ;
VAL_ 1861 ecuSerialNrChar16_BMS06 90 "'Z'" 89 "'Y'" 88 "'X'" 87 "'W'" 86 "'V'" 85 "'U'" 84 "'T'" 83 "'S'" 82 "'R'" 81 "'Q'" 80 "'P'" 79 "'O'" 78 "'N'" 77 "'M'" 76 "'L'" 75 "'K'" 74 "'J'" 73 "'I'" 72 "'H'" 71 "'G'" 70 "'F'" 69 "'E'" 68 "'D'" 67 "'C'" 66 "'B'" 65 "'A'" 57 "'9'" 56 "'8'" 55 "'7'" 54 "'6'" 53 "'5'" 52 "'4'" 51 "'3'" 50 "'2'" 49 "'1'" 48 "'0'" ;
VAL_ 1861 ecuSerialNrChar17_BMS06 90 "'Z'" 89 "'Y'" 88 "'X'" 87 "'W'" 86 "'V'" 85 "'U'" 84 "'T'" 83 "'S'" 82 "'R'" 81 "'Q'" 80 "'P'" 79 "'O'" 78 "'N'" 77 "'M'" 76 "'L'" 75 "'K'" 74 "'J'" 73 "'I'" 72 "'H'" 71 "'G'" 70 "'F'" 69 "'E'" 68 "'D'" 67 "'C'" 66 "'B'" 65 "'A'" 57 "'9'" 56 "'8'" 55 "'7'" 54 "'6'" 53 "'5'" 52 "'4'" 51 "'3'" 50 "'2'" 49 "'1'" 48 "'0'" ;
VAL_ 1861 ecuSerialNrChar18_BMS06 90 "'Z'" 89 "'Y'" 88 "'X'" 87 "'W'" 86 "'V'" 85 "'U'" 84 "'T'" 83 "'S'" 82 "'R'" 81 "'Q'" 80 "'P'" 79 "'O'" 78 "'N'" 77 "'M'" 76 "'L'" 75 "'K'" 74 "'J'" 73 "'I'" 72 "'H'" 71 "'G'" 70 "'F'" 69 "'E'" 68 "'D'" 67 "'C'" 66 "'B'" 65 "'A'" 57 "'9'" 56 "'8'" 55 "'7'" 54 "'6'" 53 "'5'" 52 "'4'" 51 "'3'" 50 "'2'" 49 "'1'" 48 "'0'" ;
VAL_ 1861 ecuSerialNrChar19_BMS06 90 "'Z'" 89 "'Y'" 88 "'X'" 87 "'W'" 86 "'V'" 85 "'U'" 84 "'T'" 83 "'S'" 82 "'R'" 81 "'Q'" 80 "'P'" 79 "'O'" 78 "'N'" 77 "'M'" 76 "'L'" 75 "'K'" 74 "'J'" 73 "'I'" 72 "'H'" 71 "'G'" 70 "'F'" 69 "'E'" 68 "'D'" 67 "'C'" 66 "'B'" 65 "'A'" 57 "'9'" 56 "'8'" 55 "'7'" 54 "'6'" 53 "'5'" 52 "'4'" 51 "'3'" 50 "'2'" 49 "'1'" 48 "'0'" ;
VAL_ 1861 maxModuleTemperature_BMS06 255 "SNA" ;
VAL_ 1861 meanModuleTemperature_BMS06 255 "SNA" ;
VAL_ 1861 minModuleTemperature_BMS06 255 "SNA" ;
VAL_ 1861 nmOperationalMode_BMS06 2 "NM_BUSSLEEP_MODE" 1 "NM_PREPAREBUSSLEEP_MODE" 0 "NM_NETWORK_MODE" ;
VAL_ 1861 nmNetworkMode_BMS06 2 "NM_MODE_READY_SLEEP" 1 "NM_MODE_NORMAL_OPERATION" 0 "NM_MODE_REPEAT_MESSAGE" ;
VAL_ 1861 nmNetworkState_BMS06 1 "NM_STATE_REQUESTED" 0 "NM_STATE_RELEASED" ;
VAL_ 1861 ecuState_BMS06 4 "ECU_SLEEPING" 3 "ECU_GOING_TO_SLEEP" 2 "ECU_AWAKE_CAN_ACTIVE" 1 "ECU_AWAKE_CAN_INACTIVE" 0 "ECU_INIT" ;
VAL_ 1861 SPIRxTxDiag_BMS06 3 "SPIRXTX_SLAVEREQUESTPACKAGE" 2 "SPIRXTX_CRC" 1 "SPIRXTX_WRONG_PACKETINDEX" 0 "SPIRXTX_ALL_OK" ;
VAL_ 1861 minSOC_BMS06 65535 "SNA" ;
VAL_ 1861 maxSOC_BMS06 65535 "SNA" ;
VAL_ 1861 appTaskMaxCpuUsage_BMS06 255 "SNA" ;
VAL_ 1861 appTaskCpuUsage_BMS06 255 "SNA" ;
VAL_ 1861 appTask50HzCpuUsage_BMS06 255 "SNA" ;
VAL_ 1861 appTask10HzStackUsage_BMS06 255 "SNA" ;
VAL_ 1861 appTask100HzCpuUsage_BMS06 255 "SNA" ;
VAL_ 1861 appTask10HzCpuUsage_BMS06 255 "SNA" ;
VAL_ 1861 appTask1HzCpuUsage_BMS06 255 "SNA" ;
VAL_ 1861 pumpSpeedReq_BMS06 255 "SNA" ;
VAL_ 1861 regenCurrPredBrickVOffset_BMS06 255 "SNA" ;
VAL_ 1861 dischgCurrPredBrickVOffset_BMS06 255 "SNA" ;
VAL_ 1861 PCANBusOffState_BMS06 3 "SNA" 2 "CAN_BUSOFF_PHASE2" 1 "CAN_BUSOFF_PHASE1" 0 "CAN_BUSOFF_NORMAL" ;
VAL_ 1861 SCANBusOffState_BMS06 3 "SNA" 2 "CAN_BUSOFF_PHASE2" 1 "CAN_BUSOFF_PHASE1" 0 "CAN_BUSOFF_NORMAL" ;
VAL_ 1861 PTCANBusOffState_BMS06 3 "SNA" 2 "CAN_BUSOFF_PHASE2" 1 "CAN_BUSOFF_PHASE1" 0 "CAN_BUSOFF_NORMAL" ;
VAL_ 1861 customerModelVsCellType_BMS06 0 "L" 1 "P" ;
VAL_ 1861 balancingVoltageTarget_BMS06 255 "VOLTAGEBASED_BALANCING_INACTIVE" ;
VAL_ 1861 analogAddr5_BMS06 255 "SNA" ;
VAL_ 1861 analogAddr0_BMS06 255 "SNA" ;
VAL_ 1861 analogAddr4_BMS06 255 "SNA" ;
VAL_ 1861 analogAddr3_BMS06 255 "SNA" ;
VAL_ 1861 analogAddr2_BMS06 255 "SNA" ;
VAL_ 1861 analogAddr1_BMS06 255 "SNA" ;
VAL_ 1861 debugSlowMpex1_BMS06 43 "S43" 42 "S42" 41 "S41" 40 "S40" 39 "S39" 38 "S38" 37 "S37" 36 "S36" 0 "S00" 1 "S01" 2 "S02" 3 "S03" 4 "S04" 5 "S05" 6 "S06" 7 "S07" 8 "S08" 9 "S09" 10 "S10" 11 "S11" 12 "S12" 13 "S13" 14 "S14" 15 "S15" 16 "S16" 17 "S17" 18 "S18" 19 "S19" 20 "S20" 21 "S21" 22 "S22" 23 "S23" 24 "S24" 25 "S25" 26 "S26" 27 "S27" 28 "S28" 29 "S29" 30 "S30" 31 "S31" 32 "S32" 33 "S33" 34 "S34" 35 "S35" ;
VAL_ 1861 analog3V3DSupply_BMS06 255 "SNA" ;
VAL_ 1861 pressure_BMS06 255 "SNA" ;
VAL_ 1861 analog3P3VA_BMS06 255 "SNA" ;
VAL_ 1861 analog5VA_BMS06 255 "SNA" ;
VAL_ 1861 analog5VD_BMS06 255 "SNA" ;
VAL_ 1861 analog5VSensorSupply_BMS06 255 "SNA" ;
VAL_ 1861 analog6V5_BMS06 255 "SNA" ;
VAL_ 1861 isolationResistanceIntern_BMS06 65535 "SNA" ;
VAL_ 1861 isolationResistanceExtern_BMS06 65535 "SNA" ;
VAL_ 1861 linkVoltage_BMS06 65535 "SNA" ;
VAL_ 1861 eepromWriteCyclesBasics_BMS06 65535 "SNA" ;
VAL_ 1861 eepromBlockIndex_BMS06 255 "SNA" ;
VAL_ 1861 regenCurrentOpLimit_BMS06 65535 "SNA" ;
VAL_ 1861 regenCurrentErrorLimit_BMS06 65535 "SNA" ;
VAL_ 1861 lifetime_BMS06 -1 "SNA" ;
VAL_ 1861 eepromReadTime_BMS06 255 "SNA" ;
VAL_ 1861 pumpSpeedReqMaxT_BMS06 65535 "SNA" ;
VAL_ 1861 pumpSpeedReqDeltaT_BMS06 65535 "SNA" ;
VAL_ 1861 packVoltageCMB_BMS06 65535 "SNA" ;
VAL_ 1861 ctrOffTime_BMS06 65535 "SNA" ;
VAL_ 1861 sleepTime_BMS06 65535 "SNA" ;
VAL_ 1861 SPIRxTxTimeAllPckts_BMS06 255 "SNA" ;
VAL_ 1861 isolationTestState_BMS06 3 "ISOLATION_DISABLED" 2 "ISOLATION_TEST_NEG" 1 "ISOLATION_TEST_POS" 0 "ISOLATION_OFF" ;
VAL_ 1733 SPIRxTxHeaderMux3Status_BMS06 1 "SPIRXTX_MUX_MISSING" 0 "SPIRXTX_MUX_GOOD" ;
VAL_ 1733 SPIRxTxHeaderMux2Status_BMS06 1 "SPIRXTX_MUX_MISSING" 0 "SPIRXTX_MUX_GOOD" ;
VAL_ 1733 SPIRxTxHeaderMux1Status_BMS06 1 "SPIRXTX_MUX_MISSING" 0 "SPIRXTX_MUX_GOOD" ;
VAL_ 1733 SPIRxTxHeaderMux0Status_BMS06 1 "SPIRXTX_MUX_MISSING" 0 "SPIRXTX_MUX_GOOD" ;
VAL_ 1733 activeIsoState_BMS06 4 "ISOACTV_COMPLETE" 3 "ISOACTV_TIMEOUT" 2 "ISOACTV_PENDING" 1 "ISOACTV_INIT" 0 "ISOACTV_OFF" ;
VAL_ 1733 activeIsoNegLink_BMS06 65535 "SNA" ;
VAL_ 1733 activeIsoPosLink_BMS06 65535 "SNA" ;
VAL_ 1733 activeIsoPosBuffer_BMS06 65535 "SNA" ;
VAL_ 1733 activeIsoNegBuffer_BMS06 65535 "SNA" ;
VAL_ 1733 activeIsoResRaw_BMS06 65535 "SNA" ;
VAL_ 1733 activeIsoResFilter_BMS06 65535 "SNA" ;
VAL_ 1733 contactorStateAux_BMS06 4 "CTR_INVALID" 3 "CTR_STRING_OPENING" 2 "CTR_STRING_ON" 1 "CTR_STRING_PRECHARGE" 0 "CTR_STRING_OFF" ;
VAL_ 1733 batSwitchOpenReqEssMstr_BMS06 3 "INVALID" 2 "IMMEDIATE_OPEN" 1 "FAST_OPEN" 0 "DO_NOT_OPEN" ;
VAL_ 1733 packShutdownTarget_BMS06 3 "BMS_INVALID" 1 "BMS_STRING_FAULT" 0 "BMS_STANDBY" ;
VAL_ 1733 weldedState_BMS06 3 "CTR_NEG1_WELDED" 2 "CTR_POS1_WELDED" 0 "CTR_NOTWELDED" 1 "CTR_BOTH_WELDED" ;
VAL_ 1733 contactorStateRq_BMS06 4 "CTR_INVALID" 3 "CTR_STRING_OPENING" 2 "CTR_STRING_ON" 1 "CTR_STRING_PRECHARGE" 0 "CTR_STRING_OFF" ;
VAL_ 1733 strMstrStrPrechgState_BMS06 7 "NOT_A_STRING_MASTER" 6 "STRING_PRCHG_NDEF2" 5 "STRING_PRCHG_NDEF1" 4 "STRING_PRCHG_FAULT" 3 "STRING_PRCHG_ON" 2 "STRING_PRCHG_ACTV" 1 "STRING_PRCHG_INIT" 0 "STRING_PRCHG_OFF" ;
VAL_ 1733 packShutdwnTmrQual_BMS06 0 "SHUTDOWN_ACTIVE" 1 "SHUTDOWN_INACTIVE" ;
VAL_ 1733 packStateRequest_BMS06 7 "STATE_INVALID" 6 "STATE_SYSTEM_FAULT" 5 "STATE_STRING_FAULT" 4 "STATE_LIMPHOME" 3 "STATE_ACCESSORY" 2 "STATE_CHARGE" 1 "STATE_DRIVE" 0 "STATE_STANDBY" ;
VAL_ 1733 packState_BMS06 15 "STATE_INVALID" 6 "STATE_ESS_FAULT" 5 "STATE_STRING_FAULT" 4 "STATE_LIMPHOME" 3 "STATE_ACCESSORY" 2 "STATE_CHARGE" 1 "STATE_DRIVE" 0 "STATE_STANDBY" ;
VAL_ 1733 SPIRxTxTimer_BMS06 255 "SNA" ;
VAL_ 1733 moduleTMinMaxMeanQual_BMS06 1 "QUAL_ERROR" 0 "QUAL_VALID" ;
VAL_ 1733 currentQual_BMS06 1 "QUAL_ERROR" 0 "QUAL_VALID" ;
VAL_ 1733 brickVMinMaxMeanQual_BMS06 1 "QUAL_ERROR" 0 "QUAL_VALID" ;
VAL_ 1733 debugFastMpex1_BMS06 0 "F00" 1 "F01" 2 "F02" 3 "F03" 4 "F04" 5 "F05" 6 "F06" 7 "F07" 8 "F08" 9 "F09" 10 "F10" 11 "F11" 12 "F12" 13 "F13" 14 "F14" 15 "F15" ;
VAL_ 1733 itemState_BMS06 3 "ITEM_INVALID" 2 "ITEM_EMERGENCY" 1 "ITEM_OFF" 0 "ITEM_ON" ;
VAL_ 1733 posLink_BMS06 255 "SNA" ;
VAL_ 1733 posPack_BMS06 255 "SNA" ;
VAL_ 1733 prechargeState_BMS06 14 "CTR_PRCHG_WAIT_CY_MATCH" 15 "CTR_PRCHG_NEG_OPEN" 13 "CTR_PRCHG_POS_WELD_CHECK" 12 "CTR_PRCHG_PRE_COND_CHECK" 11 "CTR_PRCHG_NEG2_WELD_CHECK" 10 "CTR_PRCHG_CLOSEMID" 9 "CTR_PRCHG_CLOSEAUX" 8 "CTR_PRCHG_FAILED" 7 "CTR_PRCHG_COMPLETE" 6 "CTR_PRCHG_CLOSE_POS" 5 "CTR_PRCHG_MONITOR_VOLTAGE" 4 "CTR_PRCHG_CLOSE_NEG" 3 "CTR_PRCHG_NEG_WELD_CHECK" 2 "CTR_PRCHG_CLOSE_RELAY" 1 "CTR_PRCHG_WELD_CHECK" 0 "CTR_PRCHG_OFF" ;
VAL_ 1733 contactorState_BMS06 4 "CTR_INVALID" 3 "CTR_STRING_OPENING" 2 "CTR_STRING_ON" 1 "CTR_STRING_PRECHARGE" 0 "CTR_STRING_OFF" ;
VAL_ 1541 DEMEventMultiplexor_BMS06 319 "DEM319_HV_DISABLE_DURING_S" 318 "DEM318_HV_ENABLE_IMPLAUSIB" 317 "DEM317_STRING_SUSPECT_OPEN" 316 "DEM316_UNEXPCTD_BMS_ON_CAN" 315 "DEM315_HV_WITHSTAND_TESTS_" 314 "DEM314_OBC_PILOT_ERROR" 313 "DEM313_OBC_PILOT_HIGH" 312 "DEM312_OBC_PROXIMITY_ERROR" 311 "DEM311_CTRS_END_OF_LIFE_WA" 310 "DEM310_BMSMIA_STRNGMSTR_AL" 309 "DEM309_VOLTAGE_BRICKOV_WAR" 308 "DEM308_PRESSURE_FLT" 307 "DEM307_PRESSURE_MIA" 306 "DEM306_SW_VERSION_MISMATCH" 305 "DEM305_MODULET_OVERTEMP_WA" 304 "DEM304_PCHG_OPENCIRCUIT_IN" 303 "DEM303_MODULET_UNDERTEMP_W" 302 "DEM302_MODULET_UT" 301 "DEM301_FUSI_LOCK" 300 "DEM300_DEBUG_SM_DISABLED" 299 "DEM299_5V_SENSOR_SUPPLY_OU" 298 "DEM298_IMPL_DRIVE_REQUEST" 297 "DEM297_PCHG2_OPENCIRCUIT" 296 "DEM296_CTRSAUX_IMPLAUSIBLE" 295 "DEM295_CTRSAUX_LINKV_UNSAF" 294 "DEM294_CANRX_PT_EMERGENCY" 293 "DEM293_SBC_LDT_IMPLAUSIBLE" 292 "DEM292_NUM_EXPECTED_STRING" 291 "DEM291_NUM_EXPECTED_STRING" 290 "DEM290_CMB_ONBOARD_DEFECT" 289 "DEM289_TEMP_STATE_LATCHED" 288 "DEM288_CURR_STATE_LATCHED" 1 "DEM001_POWERUP" 2 "DEM002_VOLTAGE_BRICK_OV" 3 "DEM003_VOLTAGE_BRICK_UV" 4 "DEM004_VOLTAGE_BRICK_SNA" 5 "DEM005_VOLTAGE_BRICK_IMBAL" 6 "DEM006_VOLTAGE_CAPCY_IMBAL" 7 "DEM007_MODULET_HIGH_DELTA" 8 "DEM008_VOLTAGE_PACK_UV" 9 "DEM009_VOLTAGE_PACK_OV" 10 "DEM010_VOLTAGE_PACK_PLAUSI" 11 "DEM011_VOLTAGE_PCKLINK_MIS" 12 "DEM012_VOLTAGE_BMS_SUPPLY" 13 "DEM013_ADC_ERROR" 14 "DEM014_MODULET_OT" 15 "DEM015_MODULET_SNA" 16 "DEM016_MODULET_LIMPHOME" 17 "DEM017_COOLING_SYS_LHOME" 18 "DEM018_HVIL_LIMPHOME" 19 "DEM019_HVIL_ESS_INHIBIT" 20 "DEM020_MODULET_CHANGE" 21 "DEM021_LG_MAVD_FAULT" 22 "DEM022_LG_RDV_FAULT" 23 "DEM023_BMS_ONBOARDT_SNA" 24 "DEM024_BMS_ONBOARDRH_OH" 25 "DEM025_BMS_ONBOARDRH_SNA" 26 "DEM026_CURRENT_OVERCHARGE" 27 "DEM027_CURRENT_OVERDISCHGE" 28 "DEM028_CURRENT_INVALID" 29 "DEM029_CURRENT_SHORTCIRCT" 30 "DEM030_CRASH_CAN_LATCH" 31 "DEM031_EEPROM_FAIL" 32 "DEM032_PCHG_PACKS_CONNECT" 33 "DEM033_PCHG_ILLEGAL_PRCHG" 34 "DEM034_PCHG_RELAY_FAIL" 35 "DEM035_PCHG_NEG_WELD" 36 "DEM036_PCHG_NEG_PULLIN" 37 "DEM037_PCHG_SHORTCIRCUIT" 38 "DEM038_PCHG_OPENCIRCUIT" 39 "DEM039_PCHG_TIMEOUT" 40 "DEM040_PCHG_FAILED" 41 "DEM041_HVIL_SHUTDOWN" 42 "DEM042_PCHG_POS_WELD" 43 "DEM043_HV_LOCK_TRANSPORT" 44 "DEM044_CTRS_END_OF_LIFE" 45 "DEM045_CTRS_CTRPWRV_HI" 46 "DEM046_CTRS_COILCURR_LOW" 47 "DEM047_CTRS_COILCURR_HIGH" 48 "DEM048_CTRS_CTRPWRV_LOW" 49 "DEM049_CHGE_ILLEGAL_DISCHG" 50 "DEM050_STARTUP_CONDITIONS" 51 "DEM051_VOLTAGE_BMS_SUPPLYH" 52 "DEM052_SAFETYSPI_FAIL" 53 "DEM053_WATCHDOG_ERRORPIN" 54 "DEM054_SAFESTATE_TRIGGERED" 55 "DEM055_DEBUG_CMND_ACTIVE" 56 "DEM056_CRASH_CAN" 57 "DEM057_ISO_EXT_STRAT_4" 58 "DEM058_ISO_EXT_RES_ERR" 59 "DEM059_ISO_EXT_RES_WARN" 60 "DEM060_ISO_INT_RES_ERR" 61 "DEM061_ISO_INT_RES_WARN" 62 "DEM062_EMERGENCY_OPERATION" 63 "DEM063_ENDOFDRIVE" 64 "DEM064_STRINGV_IMBALANCE" 65 "DEM065_STRING_FAULT" 66 "DEM066_ESS_FAULT" 67 "DEM067_ISO_EXT_STRAT_3" 68 "DEM068_MODULE_COUNT_INVALI" 69 "DEM069_PT_MIA" 70 "DEM070_BMSMIA_STRNGMSTR_01" 71 "DEM071_BMSMIA_STRNGMSTR_05" 72 "DEM072_BMSMIA_STRNGMSTR_09" 73 "DEM073_BMSMIA_STRNGMSTR_13" 74 "DEM074_BMSMIA_STRNGMSTR_17" 75 "DEM075_BMSMIA_STRNGMSTR_21" 76 "DEM076_BMSMIA_STRNGMSTR_25" 77 "DEM077_BMSMIA_STRNGMSTR_29" 78 "DEM078_BMSMIA_STRNGMSTR_33" 79 "DEM079_BMSMIA_STRNGMSTR_37" 80 "DEM080_BMSMIA_STRNGMSTR_41" 81 "DEM081_BMSMIA_STRNGMSTR_45" 82 "DEM082_BMSMIA_STRNGMSTR_49" 83 "DEM083_BMSMIA_STRNGMSTR_53" 84 "DEM084_BMSMIA_STRNGMSTR_57" 85 "DEM085_BMSMIA_STRNGMSTR_61" 86 "DEM086_ESSCURRENT_SHORT" 87 "DEM087_PT_MIA_SHUTDOWN" 88 "DEM088_OUTLET_NTC_HI" 89 "DEM089_OUTLET_NTC_LO" 90 "DEM090_BMSMIA_ESSMASTER" 91 "DEM091_PCHG_RES_OVERHEAT" 92 "DEM092_BMSMIA_STRNGSLAVE_0" 93 "DEM093_BMSMIA_STRNGSLAVE_1" 94 "DEM094_BMSMIA_STRNGSLAVE_2" 95 "DEM095_BMSMIA_STRNGSLAVE_3" 96 "DEM096_SC_STATE_SELFTEST" 97 "DEM097_SC_STATE_TEMP" 98 "DEM098_SC_STATE_VOLTAGE" 99 "DEM099_SC_STATE_HVIL" 100 "DEM100_SC_STATE_CONTACTORS" 101 "DEM101_SC_STATE_CURRENT" 102 "DEM102_SC_STATE_CANRX" 103 "DEM103_SC_STATE_CRASH" 104 "DEM104_SC_STATE_CCTRL" 105 "DEM105_SC_STATE_CANTX" 106 "DEM106_SC_STATE_THERMALEVT" 107 "DEM107_SC_STATE_COOLANT" 108 "DEM108_SC_SELFTEST_SFTY_UC" 109 "DEM109_SC_TEMP_HIGH" 110 "DEM110_SC_TEMP_NTC_OPEN" 111 "DEM111_SC_TEMP_NTC_SHORT" 112 "DEM112_CMB_DISCONNECTED" 113 "DEM113_CMB_DEFECT" 114 "DEM114_CMB_COMMERROR" 115 "DEM115_SC_CURR_HALL_PWR_LO" 116 "DEM116_SC_CURR_HALL_VHIGH" 117 "DEM117_SC_CURR_HALL_ADC" 118 "DEM118_SC_CURR_HALL_VLOW" 119 "DEM119_SC_CURR_ISENSE_PWR" 120 "DEM120_SC_CURR_ISENSE1_MIA" 121 "DEM121_SC_CURR_ISENSE2_MIA" 122 "DEM122_SC_CURR_ISENSE3_MIA" 123 "DEM123_SC_CURR_ISENSE4_MIA" 124 "DEM124_SC_CURR_ISENSE5_MIA" 125 "DEM125_SC_CURR_ISENSE1_FLT" 126 "DEM126_SC_CURR_ISENSE2_FLT" 127 "DEM127_SC_CURR_ISENSE3_FLT" 128 "DEM128_SC_CURR_ISENSE4_FLT" 129 "DEM129_SC_CURR_ISENSE5_FLT" 130 "DEM130_SC_CURR_OFFSET" 131 "DEM131_SC_CURR_PLAUSI" 132 "DEM132_SC_CURR_CHARGE_HIGH" 133 "DEM133_SC_CURR_DSCHAR_HIGH" 134 "DEM134_SC_V_CMB_SUMOFCELL" 135 "DEM135_SC_V_SENSE_OPENWIRE" 136 "DEM136_SC_V_CMB_DRV_FROZEN" 137 "DEM137_SC_V_PACK_PLAUSI" 138 "DEM138_SC_HVIL_HW_FLT" 139 "DEM139_SC_HVIL_OPEN" 140 "DEM140_SC_HVIL_TO_SUP" 141 "DEM141_SC_HVIL_TO_CHAS" 142 "DEM142_SC_HVIL_R_HIGH" 143 "DEM143_SC_HVIL_SHORT" 144 "DEM144_SC_CN_ISO_FAIL" 145 "DEM145_HVIL_SYS" 146 "DEM146_SC_CN_POS1_WELDED" 147 "DEM147_SC_CN_NEG1_WELDED" 148 "DEM148_SC_CN_POS2_WELDED" 149 "DEM149_SC_CN_NEG2_WELDED" 150 "DEM150_SC_CN_POS3_WELDED" 151 "DEM151_SC_CN_NEG3_WELDED" 152 "DEM152_SC_CN_HIGH_CY" 153 "DEM153_SC_CN_ISOANDPOTWELD" 154 "DEM154_SC_TEMP_PLAUSI" 155 "DEM155_SC_CURR_HALL_PWR_HI" 156 "DEM156_SC_PYRO_TRIGGERED" 157 "DEM157_SC_PYRO_OPEN" 158 "DEM158_AUX_CTRS_END_OF_LIF" 159 "DEM159_SC_CANRX_PT_MIA" 160 "DEM160_SC_CANRX_PT_CRCALIV" 161 "DEM161_SC_CANRX_LIN_SHUTDN" 162 "DEM162_SC_CANRX_LIN_MIA" 163 "DEM163_SC_CRASH1" 164 "DEM164_SC_CRASH2" 165 "DEM165_SC_CRASHCAN" 166 "DEM166_SC_CCTRL_SELFTEST" 167 "DEM167_SC_CCTRL_DRIVER_FAU" 168 "DEM168_SC_CCTRL_HISIDESTCL" 169 "DEM169_SC_CCTRL_HISIDESTOP" 170 "DEM170_SC_CCTRL_LOSIDESTCL" 171 "DEM171_SC_CCTRL_HVCNDITION" 172 "DEM172_SC_CCTRL_POS1_OPN" 173 "DEM173_SC_CCTRL_POS2_OPN" 174 "DEM174_SC_CCTRL_POS3_OPN" 175 "DEM175_SC_CCTRL_NEG1_OPN" 176 "DEM176_SC_CCTRL_NEG2_OPN" 177 "DEM177_SC_CCTRL_PRE2_OPN" 178 "DEM178_SC_CCTRL_PRE1_OPN" 179 "DEM179_SC_CCTRL_LOSIDESTOP" 180 "DEM180_SC_CCTRL_UNEXPECTED" 181 "DEM181_SC_V_OUT_OF_RANGE" 182 "DEM182_SC_V_LATCHED_UVOV" 183 "DEM183_ISO_EXT_STRAT_2" 184 "DEM184_SC_CANTX_CTRS" 185 "DEM185_SC_CANTX_HVIL" 186 "DEM186_SC_CANTX_ISOL" 187 "DEM187_SC_SBC_WATCHDOG" 188 "DEM188_SC_SBC_FAULT" 189 "DEM189_SC_WATCHDOG" 190 "DEM190_SC_SELFTEST_RAM" 191 "DEM191_SC_SELFTEST_FLASH" 192 "DEM192_CMB_ONBOARDRH_OH" 193 "DEM193_CMB_ONBOARDRH_SNA" 194 "DEM194_CMB_ONBOARDT_OT" 195 "DEM195_CMB_ONBOARDT_CHANGE" 196 "DEM196_PRESSURE_CHANGE" 197 "DEM197_PRESSURE_OVER" 198 "DEM198_PRESSURE_UNDER" 199 "DEM199_PRESSURE_INVALID" 200 "DEM200_THERMAL_EVENT" 201 "DEM201_CMB_ONBOARDT_SNA" 202 "DEM202_REPLACE_DESICCANT" 203 "DEM203_COOLANT_FLOOD_FAULT" 204 "DEM204_LOW_BRICKCAPACITY" 205 "DEM205_BMS_ONBOARDT_OT" 206 "DEM206_HUMIDITY_CHANGE" 207 "DEM207_ISENSE_SUPPLY_CURR" 208 "DEM208_SOC_LOW" 209 "DEM209_SOC_TOOLOW" 210 "DEM210_SOC_TOOHIGH" 211 "DEM211_BALANCING_REQUIRED" 212 "DEM212_DEEP_DISCHARGE" 213 "DEM213_CAN1_BUS_OFF" 214 "DEM214_CAN2_BUS_OFF" 215 "DEM215_CAN3_BUS_OFF" 216 "DEM216_OUTLET_NTC_RATNAL" 217 "DEM217_FUSE_PACK" 218 "DEM218_FUSE_B_OPEN" 219 "DEM219_FUSE_C_OPEN" 220 "DEM220_FUSE_D_OPEN" 221 "DEM221_FUSE_E_OPEN" 222 "DEM222_PUMP_DRY_RUN" 223 "DEM223_PUMP_PERFORMANCE" 224 "DEM224_PUMP_LIN_FAILURE" 225 "DEM225_PUMP_SUPPLY_VOLTAGE" 226 "DEM226_PUMP_RECOVERY_FAIL" 227 "DEM227_CTR_POS_OPENED" 228 "DEM228_CTR_NEG_OPENED" 229 "DEM229_STRSET_SLAVE1_FAULT" 230 "DEM230_STRSET_SLAVE2_FAULT" 231 "DEM231_CTRSAUX_CLFAIL_HVON" 232 "DEM232_CTRSAUX_CLFAIL_VDIF" 233 "DEM233_CTRSAUX_POS1_OPENED" 234 "DEM234_CTRSAUX_NEG1_OPENED" 235 "DEM235_CTRSAUX_POS1_WELDED" 236 "DEM236_CTRSAUX_NEG1_WELDED" 237 "DEM237_CTRSAUX_POS1_PULLIN" 238 "DEM238_CTRSAUX_NEG1_PULLIN" 239 "DEM239_INLET_NTC_RATNAL" 240 "DEM240_INLET_NTC_HI" 241 "DEM241_INLET_NTC_LO" 242 "DEM242_VOLTAGE_LINK2_RATNA" 243 "DEM243_VOLTAGE_LINK2_HI" 244 "DEM244_VOLTAGE_LINK2_LO" 245 "DEM245_CMB_ONBOARD_IMPOSSI" 246 "DEM246_VOLTAGE_LINK1_HI" 247 "DEM247_VOLTAGE_LINK1_LO" 248 "DEM248_NTC_SUPPLY_LO" 249 "DEM249_NTC_SUPPLY_HI" 250 "DEM250_VOLTAGE_LINK3_RATNA" 251 "DEM251_VOLTAGE_LINK3_HI" 252 "DEM252_VOLTAGE_LINK3_LO" 253 "DEM253_BALANCING_STUCK" 254 "DEM254_ARM_EXCEPTION" 255 "DEM255_ERROR_HOOKS" 256 "DEM256_XCP_CAL_CHANGE" 257 "DEM257_XCP_CAL_PERM_CHANGE" 258 "DEM258_TASK_TIME_OVERFLOW" 259 "DEM259_ISO_CIRCUIT" 260 "DEM260_COOLANT_MOIST_FAULT" 261 "DEM261_COOLANT_FLOOD_WARN" 262 "DEM262_COOLANT_MOIST_WARN" 263 "DEM263_MODULET_IMPLAUSIBLE" 264 "DEM264_REQUEST_ON_WITH_HV_" 265 "DEM265_CSERS_PCODE" 266 "DEM266_PRELIM_CNTR_CL_FAIL" 267 "DEM267_FLUIDLVL_LOW" 268 "DEM268_FLUIDLVL_FAILURE" 269 "DEM269_SC_COOLANT_CONTAM" 270 "DEM270_SC_COOLANT_MIA" 271 "DEM271_PRESSURE_VHI" 272 "DEM272_PRESSURE_VLO" 273 "DEM273_SC_COOLANT_FAIL" 274 "DEM274_CTRSAUX_POS2_OPENED" 275 "DEM275_CTRSAUX_POS3_OPENED" 276 "DEM276_CTRSAUX_POS2_WELDED" 277 "DEM277_CTRSAUX_POS3_WELDED" 278 "DEM278_CTRSAUX_POS2_PULLIN" 279 "DEM279_CTRSAUX_POS3_PULLIN" 280 "DEM280_CMB_HUMIDITY_TEMP_C" 281 "DEM281_THERMAL_EVENT_CMB_R" 282 "DEM282_CUS_BRICKOV" 283 "DEM283_CUS_BRICKUV" 284 "DEM284_CUS_OVERCHRG" 285 "DEM285_CUS_OVERDCHRG" 286 "DEM286_CUS_CURRENT_CHG" 287 "DEM287_CUS_CURRENT_DCHG" ;
VAL_ 1029 DEM001_POWERUP_BMS06 3 "DEM_INVALID" 2 "DEM_FAILED" 1 "DEM_PASSED" 0 "DEM_NOTTESTED" ;
VAL_ 1029 DEM002_VOLTAGE_BRICK_OV_BMS06 3 "DEM_INVALID" 2 "DEM_FAILED" 1 "DEM_PASSED" 0 "DEM_NOTTESTED" ;
VAL_ 1029 DEM003_VOLTAGE_BRICK_UV_BMS06 3 "DEM_INVALID" 2 "DEM_FAILED" 1 "DEM_PASSED" 0 "DEM_NOTTESTED" ;
VAL_ 1029 DEM004_VOLTAGE_BRICK_SNA_BMS06 3 "DEM_INVALID" 2 "DEM_FAILED" 1 "DEM_PASSED" 0 "DEM_NOTTESTED" ;
VAL_ 1029 DEM005_VOLTAGE_BRICK_IMBAL_BMS06 3 "DEM_INVALID" 2 "DEM_FAILED" 1 "DEM_PASSED" 0 "DEM_NOTTESTED" ;
VAL_ 1029 DEM006_VOLTAGE_CAPCY_IMBAL_BMS06 3 "DEM_INVALID" 2 "DEM_FAILED" 1 "DEM_PASSED" 0 "DEM_NOTTESTED" ;
VAL_ 1029 DEM007_MODULET_HIGH_DELTA_BMS06 3 "DEM_INVALID" 2 "DEM_FAILED" 1 "DEM_PASSED" 0 "DEM_NOTTESTED" ;
VAL_ 1029 DEM008_VOLTAGE_PACK_UV_BMS06 3 "DEM_INVALID" 2 "DEM_FAILED" 1 "DEM_PASSED" 0 "DEM_NOTTESTED" ;
VAL_ 1029 DEM009_VOLTAGE_PACK_OV_BMS06 3 "DEM_INVALID" 2 "DEM_FAILED" 1 "DEM_PASSED" 0 "DEM_NOTTESTED" ;
VAL_ 1029 DEM010_VOLTAGE_PACK_PLAUSI_BMS06 3 "DEM_INVALID" 2 "DEM_FAILED" 1 "DEM_PASSED" 0 "DEM_NOTTESTED" ;
VAL_ 1029 DEM011_VOLTAGE_PCKLINK_MIS_BMS06 3 "DEM_INVALID" 2 "DEM_FAILED" 1 "DEM_PASSED" 0 "DEM_NOTTESTED" ;
VAL_ 1029 DEM012_VOLTAGE_BMS_SUPPLY_BMS06 3 "DEM_INVALID" 2 "DEM_FAILED" 1 "DEM_PASSED" 0 "DEM_NOTTESTED" ;
VAL_ 1029 DEM013_ADC_ERROR_BMS06 3 "DEM_INVALID" 2 "DEM_FAILED" 1 "DEM_PASSED" 0 "DEM_NOTTESTED" ;
VAL_ 1029 DEM014_MODULET_OT_BMS06 3 "DEM_INVALID" 2 "DEM_FAILED" 1 "DEM_PASSED" 0 "DEM_NOTTESTED" ;
VAL_ 1029 DEM015_MODULET_SNA_BMS06 3 "DEM_INVALID" 2 "DEM_FAILED" 1 "DEM_PASSED" 0 "DEM_NOTTESTED" ;
VAL_ 1029 DEM016_MODULET_LIMPHOME_BMS06 3 "DEM_INVALID" 2 "DEM_FAILED" 1 "DEM_PASSED" 0 "DEM_NOTTESTED" ;
VAL_ 1029 DEM017_COOLING_SYS_LHOME_BMS06 3 "DEM_INVALID" 2 "DEM_FAILED" 1 "DEM_PASSED" 0 "DEM_NOTTESTED" ;
VAL_ 1029 DEM018_HVIL_LIMPHOME_BMS06 3 "DEM_INVALID" 2 "DEM_FAILED" 1 "DEM_PASSED" 0 "DEM_NOTTESTED" ;
VAL_ 1029 DEM019_HVIL_ESS_INHIBIT_BMS06 3 "DEM_INVALID" 2 "DEM_FAILED" 1 "DEM_PASSED" 0 "DEM_NOTTESTED" ;
VAL_ 1029 DEM020_MODULET_CHANGE_BMS06 3 "DEM_INVALID" 2 "DEM_FAILED" 1 "DEM_PASSED" 0 "DEM_NOTTESTED" ;
VAL_ 1029 DEM021_LG_MAVD_FAULT_BMS06 3 "DEM_INVALID" 2 "DEM_FAILED" 1 "DEM_PASSED" 0 "DEM_NOTTESTED" ;
VAL_ 1029 DEM022_LG_RDV_FAULT_BMS06 3 "DEM_INVALID" 2 "DEM_FAILED" 1 "DEM_PASSED" 0 "DEM_NOTTESTED" ;
VAL_ 1029 DEM023_BMS_ONBOARDT_SNA_BMS06 3 "DEM_INVALID" 2 "DEM_FAILED" 1 "DEM_PASSED" 0 "DEM_NOTTESTED" ;
VAL_ 1029 DEM024_BMS_ONBOARDRH_OH_BMS06 3 "DEM_INVALID" 2 "DEM_FAILED" 1 "DEM_PASSED" 0 "DEM_NOTTESTED" ;
VAL_ 1029 DEM025_BMS_ONBOARDRH_SNA_BMS06 3 "DEM_INVALID" 2 "DEM_FAILED" 1 "DEM_PASSED" 0 "DEM_NOTTESTED" ;
VAL_ 1029 DEM026_CURRENT_OVERCHARGE_BMS06 3 "DEM_INVALID" 2 "DEM_FAILED" 1 "DEM_PASSED" 0 "DEM_NOTTESTED" ;
VAL_ 1029 DEM027_CURRENT_OVERDISCHGE_BMS06 3 "DEM_INVALID" 2 "DEM_FAILED" 1 "DEM_PASSED" 0 "DEM_NOTTESTED" ;
VAL_ 1029 DEM028_CURRENT_INVALID_BMS06 3 "DEM_INVALID" 2 "DEM_FAILED" 1 "DEM_PASSED" 0 "DEM_NOTTESTED" ;
VAL_ 1029 DEM029_CURRENT_SHORTCIRCT_BMS06 3 "DEM_INVALID" 2 "DEM_FAILED" 1 "DEM_PASSED" 0 "DEM_NOTTESTED" ;
VAL_ 1029 DEM030_CRASH_CAN_LATCH_BMS06 3 "DEM_INVALID" 2 "DEM_FAILED" 1 "DEM_PASSED" 0 "DEM_NOTTESTED" ;
VAL_ 1029 DEM031_EEPROM_FAIL_BMS06 3 "DEM_INVALID" 2 "DEM_FAILED" 1 "DEM_PASSED" 0 "DEM_NOTTESTED" ;
VAL_ 1093 DEM032_PCHG_PACKS_CONNECT_BMS06 3 "DEM_INVALID" 2 "DEM_FAILED" 1 "DEM_PASSED" 0 "DEM_NOTTESTED" ;
VAL_ 1093 DEM033_PCHG_ILLEGAL_PRCHG_BMS06 3 "DEM_INVALID" 2 "DEM_FAILED" 1 "DEM_PASSED" 0 "DEM_NOTTESTED" ;
VAL_ 1093 DEM034_PCHG_RELAY_FAIL_BMS06 3 "DEM_INVALID" 2 "DEM_FAILED" 1 "DEM_PASSED" 0 "DEM_NOTTESTED" ;
VAL_ 1093 DEM035_PCHG_NEG_WELD_BMS06 3 "DEM_INVALID" 2 "DEM_FAILED" 1 "DEM_PASSED" 0 "DEM_NOTTESTED" ;
VAL_ 1093 DEM036_PCHG_NEG_PULLIN_BMS06 3 "DEM_INVALID" 2 "DEM_FAILED" 1 "DEM_PASSED" 0 "DEM_NOTTESTED" ;
VAL_ 1093 DEM037_PCHG_SHORTCIRCUIT_BMS06 3 "DEM_INVALID" 2 "DEM_FAILED" 1 "DEM_PASSED" 0 "DEM_NOTTESTED" ;
VAL_ 1093 DEM038_PCHG_OPENCIRCUIT_BMS06 3 "DEM_INVALID" 2 "DEM_FAILED" 1 "DEM_PASSED" 0 "DEM_NOTTESTED" ;
VAL_ 1093 DEM039_PCHG_TIMEOUT_BMS06 3 "DEM_INVALID" 2 "DEM_FAILED" 1 "DEM_PASSED" 0 "DEM_NOTTESTED" ;
VAL_ 1093 DEM040_PCHG_FAILED_BMS06 3 "DEM_INVALID" 2 "DEM_FAILED" 1 "DEM_PASSED" 0 "DEM_NOTTESTED" ;
VAL_ 1093 DEM041_HVIL_SHUTDOWN_BMS06 3 "DEM_INVALID" 2 "DEM_FAILED" 1 "DEM_PASSED" 0 "DEM_NOTTESTED" ;
VAL_ 1093 DEM042_PCHG_POS_WELD_BMS06 3 "DEM_INVALID" 2 "DEM_FAILED" 1 "DEM_PASSED" 0 "DEM_NOTTESTED" ;
VAL_ 1093 DEM043_HV_LOCK_TRANSPORT_BMS06 3 "DEM_INVALID" 2 "DEM_FAILED" 1 "DEM_PASSED" 0 "DEM_NOTTESTED" ;
VAL_ 1093 DEM044_CTRS_END_OF_LIFE_BMS06 3 "DEM_INVALID" 2 "DEM_FAILED" 1 "DEM_PASSED" 0 "DEM_NOTTESTED" ;
VAL_ 1093 DEM045_CTRS_CTRPWRV_HI_BMS06 3 "DEM_INVALID" 2 "DEM_FAILED" 1 "DEM_PASSED" 0 "DEM_NOTTESTED" ;
VAL_ 1093 DEM046_CTRS_COILCURR_LOW_BMS06 3 "DEM_INVALID" 2 "DEM_FAILED" 1 "DEM_PASSED" 0 "DEM_NOTTESTED" ;
VAL_ 1093 DEM047_CTRS_COILCURR_HIGH_BMS06 3 "DEM_INVALID" 2 "DEM_FAILED" 1 "DEM_PASSED" 0 "DEM_NOTTESTED" ;
VAL_ 1093 DEM048_CTRS_CTRPWRV_LOW_BMS06 3 "DEM_INVALID" 2 "DEM_FAILED" 1 "DEM_PASSED" 0 "DEM_NOTTESTED" ;
VAL_ 1093 DEM049_CHGE_ILLEGAL_DISCHG_BMS06 3 "DEM_INVALID" 2 "DEM_FAILED" 1 "DEM_PASSED" 0 "DEM_NOTTESTED" ;
VAL_ 1093 DEM050_STARTUP_CONDITIONS_BMS06 3 "DEM_INVALID" 2 "DEM_FAILED" 1 "DEM_PASSED" 0 "DEM_NOTTESTED" ;
VAL_ 1093 DEM051_VOLTAGE_BMS_SUPPLYH_BMS06 3 "DEM_INVALID" 2 "DEM_FAILED" 1 "DEM_PASSED" 0 "DEM_NOTTESTED" ;
VAL_ 1093 DEM052_SAFETYSPI_FAIL_BMS06 3 "DEM_INVALID" 2 "DEM_FAILED" 1 "DEM_PASSED" 0 "DEM_NOTTESTED" ;
VAL_ 1093 DEM053_WATCHDOG_ERRORPIN_BMS06 3 "DEM_INVALID" 2 "DEM_FAILED" 1 "DEM_PASSED" 0 "DEM_NOTTESTED" ;
VAL_ 1093 DEM054_SAFESTATE_TRIGGERED_BMS06 3 "DEM_INVALID" 2 "DEM_FAILED" 1 "DEM_PASSED" 0 "DEM_NOTTESTED" ;
VAL_ 1093 DEM055_DEBUG_CMND_ACTIVE_BMS06 3 "DEM_INVALID" 2 "DEM_FAILED" 1 "DEM_PASSED" 0 "DEM_NOTTESTED" ;
VAL_ 1093 DEM056_CRASH_CAN_BMS06 3 "DEM_INVALID" 2 "DEM_FAILED" 1 "DEM_PASSED" 0 "DEM_NOTTESTED" ;
VAL_ 1093 DEM057_ISO_EXT_STRAT_4_BMS06 3 "DEM_INVALID" 2 "DEM_FAILED" 1 "DEM_PASSED" 0 "DEM_NOTTESTED" ;
VAL_ 1093 DEM058_ISO_EXT_RES_ERR_BMS06 3 "DEM_INVALID" 2 "DEM_FAILED" 1 "DEM_PASSED" 0 "DEM_NOTTESTED" ;
VAL_ 1093 DEM059_ISO_EXT_RES_WARN_BMS06 3 "DEM_INVALID" 2 "DEM_FAILED" 1 "DEM_PASSED" 0 "DEM_NOTTESTED" ;
VAL_ 1093 DEM060_ISO_INT_RES_ERR_BMS06 3 "DEM_INVALID" 2 "DEM_FAILED" 1 "DEM_PASSED" 0 "DEM_NOTTESTED" ;
VAL_ 1093 DEM061_ISO_INT_RES_WARN_BMS06 3 "DEM_INVALID" 2 "DEM_FAILED" 1 "DEM_PASSED" 0 "DEM_NOTTESTED" ;
VAL_ 1093 DEM062_EMERGENCY_OPERATION_BMS06 3 "DEM_INVALID" 2 "DEM_FAILED" 1 "DEM_PASSED" 0 "DEM_NOTTESTED" ;
VAL_ 1093 DEM063_ENDOFDRIVE_BMS06 3 "DEM_INVALID" 2 "DEM_FAILED" 1 "DEM_PASSED" 0 "DEM_NOTTESTED" ;
VAL_ 1157 DEM064_STRINGV_IMBALANCE_BMS06 3 "DEM_INVALID" 2 "DEM_FAILED" 1 "DEM_PASSED" 0 "DEM_NOTTESTED" ;
VAL_ 1157 DEM065_STRING_FAULT_BMS06 3 "DEM_INVALID" 2 "DEM_FAILED" 1 "DEM_PASSED" 0 "DEM_NOTTESTED" ;
VAL_ 1157 DEM066_ESS_FAULT_BMS06 3 "DEM_INVALID" 2 "DEM_FAILED" 1 "DEM_PASSED" 0 "DEM_NOTTESTED" ;
VAL_ 1157 DEM067_ISO_EXT_STRAT_3_BMS06 3 "DEM_INVALID" 2 "DEM_FAILED" 1 "DEM_PASSED" 0 "DEM_NOTTESTED" ;
VAL_ 1157 DEM068_MODULE_COUNT_INVALI_BMS06 3 "DEM_INVALID" 2 "DEM_FAILED" 1 "DEM_PASSED" 0 "DEM_NOTTESTED" ;
VAL_ 1157 DEM069_PT_MIA_BMS06 3 "DEM_INVALID" 2 "DEM_FAILED" 1 "DEM_PASSED" 0 "DEM_NOTTESTED" ;
VAL_ 1157 DEM070_BMSMIA_STRNGMSTR_01_BMS06 3 "DEM_INVALID" 2 "DEM_FAILED" 1 "DEM_PASSED" 0 "DEM_NOTTESTED" ;
VAL_ 1157 DEM071_BMSMIA_STRNGMSTR_05_BMS06 3 "DEM_INVALID" 2 "DEM_FAILED" 1 "DEM_PASSED" 0 "DEM_NOTTESTED" ;
VAL_ 1157 DEM072_BMSMIA_STRNGMSTR_09_BMS06 3 "DEM_INVALID" 2 "DEM_FAILED" 1 "DEM_PASSED" 0 "DEM_NOTTESTED" ;
VAL_ 1157 DEM073_BMSMIA_STRNGMSTR_13_BMS06 3 "DEM_INVALID" 2 "DEM_FAILED" 1 "DEM_PASSED" 0 "DEM_NOTTESTED" ;
VAL_ 1157 DEM074_BMSMIA_STRNGMSTR_17_BMS06 3 "DEM_INVALID" 2 "DEM_FAILED" 1 "DEM_PASSED" 0 "DEM_NOTTESTED" ;
VAL_ 1157 DEM075_BMSMIA_STRNGMSTR_21_BMS06 3 "DEM_INVALID" 2 "DEM_FAILED" 1 "DEM_PASSED" 0 "DEM_NOTTESTED" ;
VAL_ 1157 DEM076_BMSMIA_STRNGMSTR_25_BMS06 3 "DEM_INVALID" 2 "DEM_FAILED" 1 "DEM_PASSED" 0 "DEM_NOTTESTED" ;
VAL_ 1157 DEM077_BMSMIA_STRNGMSTR_29_BMS06 3 "DEM_INVALID" 2 "DEM_FAILED" 1 "DEM_PASSED" 0 "DEM_NOTTESTED" ;
VAL_ 1157 DEM078_BMSMIA_STRNGMSTR_33_BMS06 3 "DEM_INVALID" 2 "DEM_FAILED" 1 "DEM_PASSED" 0 "DEM_NOTTESTED" ;
VAL_ 1157 DEM079_BMSMIA_STRNGMSTR_37_BMS06 3 "DEM_INVALID" 2 "DEM_FAILED" 1 "DEM_PASSED" 0 "DEM_NOTTESTED" ;
VAL_ 1157 DEM080_BMSMIA_STRNGMSTR_41_BMS06 3 "DEM_INVALID" 2 "DEM_FAILED" 1 "DEM_PASSED" 0 "DEM_NOTTESTED" ;
VAL_ 1157 DEM081_BMSMIA_STRNGMSTR_45_BMS06 3 "DEM_INVALID" 2 "DEM_FAILED" 1 "DEM_PASSED" 0 "DEM_NOTTESTED" ;
VAL_ 1157 DEM082_BMSMIA_STRNGMSTR_49_BMS06 3 "DEM_INVALID" 2 "DEM_FAILED" 1 "DEM_PASSED" 0 "DEM_NOTTESTED" ;
VAL_ 1157 DEM083_BMSMIA_STRNGMSTR_53_BMS06 3 "DEM_INVALID" 2 "DEM_FAILED" 1 "DEM_PASSED" 0 "DEM_NOTTESTED" ;
VAL_ 1157 DEM084_BMSMIA_STRNGMSTR_57_BMS06 3 "DEM_INVALID" 2 "DEM_FAILED" 1 "DEM_PASSED" 0 "DEM_NOTTESTED" ;
VAL_ 1157 DEM085_BMSMIA_STRNGMSTR_61_BMS06 3 "DEM_INVALID" 2 "DEM_FAILED" 1 "DEM_PASSED" 0 "DEM_NOTTESTED" ;
VAL_ 1157 DEM086_ESSCURRENT_SHORT_BMS06 3 "DEM_INVALID" 2 "DEM_FAILED" 1 "DEM_PASSED" 0 "DEM_NOTTESTED" ;
VAL_ 1157 DEM087_PT_MIA_SHUTDOWN_BMS06 3 "DEM_INVALID" 2 "DEM_FAILED" 1 "DEM_PASSED" 0 "DEM_NOTTESTED" ;
VAL_ 1157 DEM088_OUTLET_NTC_HI_BMS06 3 "DEM_INVALID" 2 "DEM_FAILED" 1 "DEM_PASSED" 0 "DEM_NOTTESTED" ;
VAL_ 1157 DEM089_OUTLET_NTC_LO_BMS06 3 "DEM_INVALID" 2 "DEM_FAILED" 1 "DEM_PASSED" 0 "DEM_NOTTESTED" ;
VAL_ 1157 DEM090_BMSMIA_ESSMASTER_BMS06 3 "DEM_INVALID" 2 "DEM_FAILED" 1 "DEM_PASSED" 0 "DEM_NOTTESTED" ;
VAL_ 1157 DEM091_PCHG_RES_OVERHEAT_BMS06 3 "DEM_INVALID" 2 "DEM_FAILED" 1 "DEM_PASSED" 0 "DEM_NOTTESTED" ;
VAL_ 1157 DEM092_BMSMIA_STRNGSLAVE_0_BMS06 3 "DEM_INVALID" 2 "DEM_FAILED" 1 "DEM_PASSED" 0 "DEM_NOTTESTED" ;
VAL_ 1157 DEM093_BMSMIA_STRNGSLAVE_1_BMS06 3 "DEM_INVALID" 2 "DEM_FAILED" 1 "DEM_PASSED" 0 "DEM_NOTTESTED" ;
VAL_ 1157 DEM094_BMSMIA_STRNGSLAVE_2_BMS06 3 "DEM_INVALID" 2 "DEM_FAILED" 1 "DEM_PASSED" 0 "DEM_NOTTESTED" ;
VAL_ 1157 DEM095_BMSMIA_STRNGSLAVE_3_BMS06 3 "DEM_INVALID" 2 "DEM_FAILED" 1 "DEM_PASSED" 0 "DEM_NOTTESTED" ;
VAL_ 1221 DEM096_SC_STATE_SELFTEST_BMS06 3 "DEM_INVALID" 2 "DEM_FAILED" 1 "DEM_PASSED" 0 "DEM_NOTTESTED" ;
VAL_ 1221 DEM097_SC_STATE_TEMP_BMS06 3 "DEM_INVALID" 2 "DEM_FAILED" 1 "DEM_PASSED" 0 "DEM_NOTTESTED" ;
VAL_ 1221 DEM098_SC_STATE_VOLTAGE_BMS06 3 "DEM_INVALID" 2 "DEM_FAILED" 1 "DEM_PASSED" 0 "DEM_NOTTESTED" ;
VAL_ 1221 DEM099_SC_STATE_HVIL_BMS06 3 "DEM_INVALID" 2 "DEM_FAILED" 1 "DEM_PASSED" 0 "DEM_NOTTESTED" ;
VAL_ 1221 DEM100_SC_STATE_CONTACTORS_BMS06 3 "DEM_INVALID" 2 "DEM_FAILED" 1 "DEM_PASSED" 0 "DEM_NOTTESTED" ;
VAL_ 1221 DEM101_SC_STATE_CURRENT_BMS06 3 "DEM_INVALID" 2 "DEM_FAILED" 1 "DEM_PASSED" 0 "DEM_NOTTESTED" ;
VAL_ 1221 DEM102_SC_STATE_CANRX_BMS06 3 "DEM_INVALID" 2 "DEM_FAILED" 1 "DEM_PASSED" 0 "DEM_NOTTESTED" ;
VAL_ 1221 DEM103_SC_STATE_CRASH_BMS06 3 "DEM_INVALID" 2 "DEM_FAILED" 1 "DEM_PASSED" 0 "DEM_NOTTESTED" ;
VAL_ 1221 DEM104_SC_STATE_CCTRL_BMS06 3 "DEM_INVALID" 2 "DEM_FAILED" 1 "DEM_PASSED" 0 "DEM_NOTTESTED" ;
VAL_ 1221 DEM105_SC_STATE_CANTX_BMS06 3 "DEM_INVALID" 2 "DEM_FAILED" 1 "DEM_PASSED" 0 "DEM_NOTTESTED" ;
VAL_ 1221 DEM106_SC_STATE_THERMALEVT_BMS06 3 "DEM_INVALID" 2 "DEM_FAILED" 1 "DEM_PASSED" 0 "DEM_NOTTESTED" ;
VAL_ 1221 DEM107_SC_STATE_COOLANT_BMS06 3 "DEM_INVALID" 2 "DEM_FAILED" 1 "DEM_PASSED" 0 "DEM_NOTTESTED" ;
VAL_ 1221 DEM108_SC_SELFTEST_SFTY_UC_BMS06 3 "DEM_INVALID" 2 "DEM_FAILED" 1 "DEM_PASSED" 0 "DEM_NOTTESTED" ;
VAL_ 1221 DEM109_SC_TEMP_HIGH_BMS06 3 "DEM_INVALID" 2 "DEM_FAILED" 1 "DEM_PASSED" 0 "DEM_NOTTESTED" ;
VAL_ 1221 DEM110_SC_TEMP_NTC_OPEN_BMS06 3 "DEM_INVALID" 2 "DEM_FAILED" 1 "DEM_PASSED" 0 "DEM_NOTTESTED" ;
VAL_ 1221 DEM111_SC_TEMP_NTC_SHORT_BMS06 3 "DEM_INVALID" 2 "DEM_FAILED" 1 "DEM_PASSED" 0 "DEM_NOTTESTED" ;
VAL_ 1221 DEM112_CMB_DISCONNECTED_BMS06 3 "DEM_INVALID" 2 "DEM_FAILED" 1 "DEM_PASSED" 0 "DEM_NOTTESTED" ;
VAL_ 1221 DEM113_CMB_DEFECT_BMS06 3 "DEM_INVALID" 2 "DEM_FAILED" 1 "DEM_PASSED" 0 "DEM_NOTTESTED" ;
VAL_ 1221 DEM114_CMB_COMMERROR_BMS06 3 "DEM_INVALID" 2 "DEM_FAILED" 1 "DEM_PASSED" 0 "DEM_NOTTESTED" ;
VAL_ 1221 DEM115_SC_CURR_HALL_PWR_LO_BMS06 3 "DEM_INVALID" 2 "DEM_FAILED" 1 "DEM_PASSED" 0 "DEM_NOTTESTED" ;
VAL_ 1221 DEM116_SC_CURR_HALL_VHIGH_BMS06 3 "DEM_INVALID" 2 "DEM_FAILED" 1 "DEM_PASSED" 0 "DEM_NOTTESTED" ;
VAL_ 1221 DEM117_SC_CURR_HALL_ADC_BMS06 3 "DEM_INVALID" 2 "DEM_FAILED" 1 "DEM_PASSED" 0 "DEM_NOTTESTED" ;
VAL_ 1221 DEM118_SC_CURR_HALL_VLOW_BMS06 3 "DEM_INVALID" 2 "DEM_FAILED" 1 "DEM_PASSED" 0 "DEM_NOTTESTED" ;
VAL_ 1221 DEM119_SC_CURR_ISENSE_PWR_BMS06 3 "DEM_INVALID" 2 "DEM_FAILED" 1 "DEM_PASSED" 0 "DEM_NOTTESTED" ;
VAL_ 1221 DEM120_SC_CURR_ISENSE1_MIA_BMS06 3 "DEM_INVALID" 2 "DEM_FAILED" 1 "DEM_PASSED" 0 "DEM_NOTTESTED" ;
VAL_ 1221 DEM121_SC_CURR_ISENSE2_MIA_BMS06 3 "DEM_INVALID" 2 "DEM_FAILED" 1 "DEM_PASSED" 0 "DEM_NOTTESTED" ;
VAL_ 1221 DEM122_SC_CURR_ISENSE3_MIA_BMS06 3 "DEM_INVALID" 2 "DEM_FAILED" 1 "DEM_PASSED" 0 "DEM_NOTTESTED" ;
VAL_ 1221 DEM123_SC_CURR_ISENSE4_MIA_BMS06 3 "DEM_INVALID" 2 "DEM_FAILED" 1 "DEM_PASSED" 0 "DEM_NOTTESTED" ;
VAL_ 1221 DEM124_SC_CURR_ISENSE5_MIA_BMS06 3 "DEM_INVALID" 2 "DEM_FAILED" 1 "DEM_PASSED" 0 "DEM_NOTTESTED" ;
VAL_ 1221 DEM125_SC_CURR_ISENSE1_FLT_BMS06 3 "DEM_INVALID" 2 "DEM_FAILED" 1 "DEM_PASSED" 0 "DEM_NOTTESTED" ;
VAL_ 1221 DEM126_SC_CURR_ISENSE2_FLT_BMS06 3 "DEM_INVALID" 2 "DEM_FAILED" 1 "DEM_PASSED" 0 "DEM_NOTTESTED" ;
VAL_ 1221 DEM127_SC_CURR_ISENSE3_FLT_BMS06 3 "DEM_INVALID" 2 "DEM_FAILED" 1 "DEM_PASSED" 0 "DEM_NOTTESTED" ;
VAL_ 1285 DEM128_SC_CURR_ISENSE4_FLT_BMS06 3 "DEM_INVALID" 2 "DEM_FAILED" 1 "DEM_PASSED" 0 "DEM_NOTTESTED" ;
VAL_ 1285 DEM129_SC_CURR_ISENSE5_FLT_BMS06 3 "DEM_INVALID" 2 "DEM_FAILED" 1 "DEM_PASSED" 0 "DEM_NOTTESTED" ;
VAL_ 1285 DEM130_SC_CURR_OFFSET_BMS06 3 "DEM_INVALID" 2 "DEM_FAILED" 1 "DEM_PASSED" 0 "DEM_NOTTESTED" ;
VAL_ 1285 DEM131_SC_CURR_PLAUSI_BMS06 3 "DEM_INVALID" 2 "DEM_FAILED" 1 "DEM_PASSED" 0 "DEM_NOTTESTED" ;
VAL_ 1285 DEM132_SC_CURR_CHARGE_HIGH_BMS06 3 "DEM_INVALID" 2 "DEM_FAILED" 1 "DEM_PASSED" 0 "DEM_NOTTESTED" ;
VAL_ 1285 DEM133_SC_CURR_DSCHAR_HIGH_BMS06 3 "DEM_INVALID" 2 "DEM_FAILED" 1 "DEM_PASSED" 0 "DEM_NOTTESTED" ;
VAL_ 1285 DEM134_SC_V_CMB_SUMOFCELL_BMS06 3 "DEM_INVALID" 2 "DEM_FAILED" 1 "DEM_PASSED" 0 "DEM_NOTTESTED" ;
VAL_ 1285 DEM135_SC_V_SENSE_OPENWIRE_BMS06 3 "DEM_INVALID" 2 "DEM_FAILED" 1 "DEM_PASSED" 0 "DEM_NOTTESTED" ;
VAL_ 1285 DEM136_SC_V_CMB_DRV_FROZEN_BMS06 3 "DEM_INVALID" 2 "DEM_FAILED" 1 "DEM_PASSED" 0 "DEM_NOTTESTED" ;
VAL_ 1285 DEM137_SC_V_PACK_PLAUSI_BMS06 3 "DEM_INVALID" 2 "DEM_FAILED" 1 "DEM_PASSED" 0 "DEM_NOTTESTED" ;
VAL_ 1285 DEM138_SC_HVIL_HW_FLT_BMS06 3 "DEM_INVALID" 2 "DEM_FAILED" 1 "DEM_PASSED" 0 "DEM_NOTTESTED" ;
VAL_ 1285 DEM139_SC_HVIL_OPEN_BMS06 3 "DEM_INVALID" 2 "DEM_FAILED" 1 "DEM_PASSED" 0 "DEM_NOTTESTED" ;
VAL_ 1285 DEM140_SC_HVIL_TO_SUP_BMS06 3 "DEM_INVALID" 2 "DEM_FAILED" 1 "DEM_PASSED" 0 "DEM_NOTTESTED" ;
VAL_ 1285 DEM141_SC_HVIL_TO_CHAS_BMS06 3 "DEM_INVALID" 2 "DEM_FAILED" 1 "DEM_PASSED" 0 "DEM_NOTTESTED" ;
VAL_ 1285 DEM142_SC_HVIL_R_HIGH_BMS06 3 "DEM_INVALID" 2 "DEM_FAILED" 1 "DEM_PASSED" 0 "DEM_NOTTESTED" ;
VAL_ 1285 DEM143_SC_HVIL_SHORT_BMS06 3 "DEM_INVALID" 2 "DEM_FAILED" 1 "DEM_PASSED" 0 "DEM_NOTTESTED" ;
VAL_ 1285 DEM144_SC_CN_ISO_FAIL_BMS06 3 "DEM_INVALID" 2 "DEM_FAILED" 1 "DEM_PASSED" 0 "DEM_NOTTESTED" ;
VAL_ 1285 DEM145_HVIL_SYS_BMS06 3 "DEM_INVALID" 2 "DEM_FAILED" 1 "DEM_PASSED" 0 "DEM_NOTTESTED" ;
VAL_ 1285 DEM146_SC_CN_POS1_WELDED_BMS06 3 "DEM_INVALID" 2 "DEM_FAILED" 1 "DEM_PASSED" 0 "DEM_NOTTESTED" ;
VAL_ 1285 DEM147_SC_CN_NEG1_WELDED_BMS06 3 "DEM_INVALID" 2 "DEM_FAILED" 1 "DEM_PASSED" 0 "DEM_NOTTESTED" ;
VAL_ 1285 DEM148_SC_CN_POS2_WELDED_BMS06 3 "DEM_INVALID" 2 "DEM_FAILED" 1 "DEM_PASSED" 0 "DEM_NOTTESTED" ;
VAL_ 1285 DEM149_SC_CN_NEG2_WELDED_BMS06 3 "DEM_INVALID" 2 "DEM_FAILED" 1 "DEM_PASSED" 0 "DEM_NOTTESTED" ;
VAL_ 1285 DEM150_SC_CN_POS3_WELDED_BMS06 3 "DEM_INVALID" 2 "DEM_FAILED" 1 "DEM_PASSED" 0 "DEM_NOTTESTED" ;
VAL_ 1285 DEM151_SC_CN_NEG3_WELDED_BMS06 3 "DEM_INVALID" 2 "DEM_FAILED" 1 "DEM_PASSED" 0 "DEM_NOTTESTED" ;
VAL_ 1285 DEM152_SC_CN_HIGH_CY_BMS06 3 "DEM_INVALID" 2 "DEM_FAILED" 1 "DEM_PASSED" 0 "DEM_NOTTESTED" ;
VAL_ 1285 DEM153_SC_CN_ISOANDPOTWELD_BMS06 3 "DEM_INVALID" 2 "DEM_FAILED" 1 "DEM_PASSED" 0 "DEM_NOTTESTED" ;
VAL_ 1285 DEM154_SC_TEMP_PLAUSI_BMS06 3 "DEM_INVALID" 2 "DEM_FAILED" 1 "DEM_PASSED" 0 "DEM_NOTTESTED" ;
VAL_ 1285 DEM155_SC_CURR_HALL_PWR_HI_BMS06 3 "DEM_INVALID" 2 "DEM_FAILED" 1 "DEM_PASSED" 0 "DEM_NOTTESTED" ;
VAL_ 1285 DEM156_SC_PYRO_TRIGGERED_BMS06 3 "DEM_INVALID" 2 "DEM_FAILED" 1 "DEM_PASSED" 0 "DEM_NOTTESTED" ;
VAL_ 1285 DEM157_SC_PYRO_OPEN_BMS06 3 "DEM_INVALID" 2 "DEM_FAILED" 1 "DEM_PASSED" 0 "DEM_NOTTESTED" ;
VAL_ 1285 DEM158_AUX_CTRS_END_OF_LIF_BMS06 3 "DEM_INVALID" 2 "DEM_FAILED" 1 "DEM_PASSED" 0 "DEM_NOTTESTED" ;
VAL_ 1285 DEM159_SC_CANRX_PT_MIA_BMS06 3 "DEM_INVALID" 2 "DEM_FAILED" 1 "DEM_PASSED" 0 "DEM_NOTTESTED" ;
VAL_ 1349 DEM160_SC_CANRX_PT_CRCALIV_BMS06 3 "DEM_INVALID" 2 "DEM_FAILED" 1 "DEM_PASSED" 0 "DEM_NOTTESTED" ;
VAL_ 1349 DEM161_SC_CANRX_LIN_SHUTDN_BMS06 3 "DEM_INVALID" 2 "DEM_FAILED" 1 "DEM_PASSED" 0 "DEM_NOTTESTED" ;
VAL_ 1349 DEM162_SC_CANRX_LIN_MIA_BMS06 3 "DEM_INVALID" 2 "DEM_FAILED" 1 "DEM_PASSED" 0 "DEM_NOTTESTED" ;
VAL_ 1349 DEM163_SC_CRASH1_BMS06 3 "DEM_INVALID" 2 "DEM_FAILED" 1 "DEM_PASSED" 0 "DEM_NOTTESTED" ;
VAL_ 1349 DEM164_SC_CRASH2_BMS06 3 "DEM_INVALID" 2 "DEM_FAILED" 1 "DEM_PASSED" 0 "DEM_NOTTESTED" ;
VAL_ 1349 DEM165_SC_CRASHCAN_BMS06 3 "DEM_INVALID" 2 "DEM_FAILED" 1 "DEM_PASSED" 0 "DEM_NOTTESTED" ;
VAL_ 1349 DEM166_SC_CCTRL_SELFTEST_BMS06 3 "DEM_INVALID" 2 "DEM_FAILED" 1 "DEM_PASSED" 0 "DEM_NOTTESTED" ;
VAL_ 1349 DEM167_SC_CCTRL_DRIVER_FAU_BMS06 3 "DEM_INVALID" 2 "DEM_FAILED" 1 "DEM_PASSED" 0 "DEM_NOTTESTED" ;
VAL_ 1349 DEM168_SC_CCTRL_HISIDESTCL_BMS06 3 "DEM_INVALID" 2 "DEM_FAILED" 1 "DEM_PASSED" 0 "DEM_NOTTESTED" ;
VAL_ 1349 DEM169_SC_CCTRL_HISIDESTOP_BMS06 3 "DEM_INVALID" 2 "DEM_FAILED" 1 "DEM_PASSED" 0 "DEM_NOTTESTED" ;
VAL_ 1349 DEM170_SC_CCTRL_LOSIDESTCL_BMS06 3 "DEM_INVALID" 2 "DEM_FAILED" 1 "DEM_PASSED" 0 "DEM_NOTTESTED" ;
VAL_ 1349 DEM171_SC_CCTRL_HVCNDITION_BMS06 3 "DEM_INVALID" 2 "DEM_FAILED" 1 "DEM_PASSED" 0 "DEM_NOTTESTED" ;
VAL_ 1349 DEM172_SC_CCTRL_POS1_OPN_BMS06 3 "DEM_INVALID" 2 "DEM_FAILED" 1 "DEM_PASSED" 0 "DEM_NOTTESTED" ;
VAL_ 1349 DEM173_SC_CCTRL_POS2_OPN_BMS06 3 "DEM_INVALID" 2 "DEM_FAILED" 1 "DEM_PASSED" 0 "DEM_NOTTESTED" ;
VAL_ 1349 DEM174_SC_CCTRL_POS3_OPN_BMS06 3 "DEM_INVALID" 2 "DEM_FAILED" 1 "DEM_PASSED" 0 "DEM_NOTTESTED" ;
VAL_ 1349 DEM175_SC_CCTRL_NEG1_OPN_BMS06 3 "DEM_INVALID" 2 "DEM_FAILED" 1 "DEM_PASSED" 0 "DEM_NOTTESTED" ;
VAL_ 1349 DEM176_SC_CCTRL_NEG2_OPN_BMS06 3 "DEM_INVALID" 2 "DEM_FAILED" 1 "DEM_PASSED" 0 "DEM_NOTTESTED" ;
VAL_ 1349 DEM177_SC_CCTRL_PRE2_OPN_BMS06 3 "DEM_INVALID" 2 "DEM_FAILED" 1 "DEM_PASSED" 0 "DEM_NOTTESTED" ;
VAL_ 1349 DEM178_SC_CCTRL_PRE1_OPN_BMS06 3 "DEM_INVALID" 2 "DEM_FAILED" 1 "DEM_PASSED" 0 "DEM_NOTTESTED" ;
VAL_ 1349 DEM179_SC_CCTRL_LOSIDESTOP_BMS06 3 "DEM_INVALID" 2 "DEM_FAILED" 1 "DEM_PASSED" 0 "DEM_NOTTESTED" ;
VAL_ 1349 DEM180_SC_CCTRL_UNEXPECTED_BMS06 3 "DEM_INVALID" 2 "DEM_FAILED" 1 "DEM_PASSED" 0 "DEM_NOTTESTED" ;
VAL_ 1349 DEM181_SC_V_OUT_OF_RANGE_BMS06 3 "DEM_INVALID" 2 "DEM_FAILED" 1 "DEM_PASSED" 0 "DEM_NOTTESTED" ;
VAL_ 1349 DEM182_SC_V_LATCHED_UVOV_BMS06 3 "DEM_INVALID" 2 "DEM_FAILED" 1 "DEM_PASSED" 0 "DEM_NOTTESTED" ;
VAL_ 1349 DEM183_ISO_EXT_STRAT_2_BMS06 3 "DEM_INVALID" 2 "DEM_FAILED" 1 "DEM_PASSED" 0 "DEM_NOTTESTED" ;
VAL_ 1349 DEM184_SC_CANTX_CTRS_BMS06 3 "DEM_INVALID" 2 "DEM_FAILED" 1 "DEM_PASSED" 0 "DEM_NOTTESTED" ;
VAL_ 1349 DEM185_SC_CANTX_HVIL_BMS06 3 "DEM_INVALID" 2 "DEM_FAILED" 1 "DEM_PASSED" 0 "DEM_NOTTESTED" ;
VAL_ 1349 DEM186_SC_CANTX_ISOL_BMS06 3 "DEM_INVALID" 2 "DEM_FAILED" 1 "DEM_PASSED" 0 "DEM_NOTTESTED" ;
VAL_ 1349 DEM187_SC_SBC_WATCHDOG_BMS06 3 "DEM_INVALID" 2 "DEM_FAILED" 1 "DEM_PASSED" 0 "DEM_NOTTESTED" ;
VAL_ 1349 DEM188_SC_SBC_FAULT_BMS06 3 "DEM_INVALID" 2 "DEM_FAILED" 1 "DEM_PASSED" 0 "DEM_NOTTESTED" ;
VAL_ 1349 DEM189_SC_WATCHDOG_BMS06 3 "DEM_INVALID" 2 "DEM_FAILED" 1 "DEM_PASSED" 0 "DEM_NOTTESTED" ;
VAL_ 1349 DEM190_SC_SELFTEST_RAM_BMS06 3 "DEM_INVALID" 2 "DEM_FAILED" 1 "DEM_PASSED" 0 "DEM_NOTTESTED" ;
VAL_ 1349 DEM191_SC_SELFTEST_FLASH_BMS06 3 "DEM_INVALID" 2 "DEM_FAILED" 1 "DEM_PASSED" 0 "DEM_NOTTESTED" ;
VAL_ 1413 DEM192_CMB_ONBOARDRH_OH_BMS06 3 "DEM_INVALID" 2 "DEM_FAILED" 1 "DEM_PASSED" 0 "DEM_NOTTESTED" ;
VAL_ 1413 DEM193_CMB_ONBOARDRH_SNA_BMS06 3 "DEM_INVALID" 2 "DEM_FAILED" 1 "DEM_PASSED" 0 "DEM_NOTTESTED" ;
VAL_ 1413 DEM194_CMB_ONBOARDT_OT_BMS06 3 "DEM_INVALID" 2 "DEM_FAILED" 1 "DEM_PASSED" 0 "DEM_NOTTESTED" ;
VAL_ 1413 DEM195_CMB_ONBOARDT_CHANGE_BMS06 3 "DEM_INVALID" 2 "DEM_FAILED" 1 "DEM_PASSED" 0 "DEM_NOTTESTED" ;
VAL_ 1413 DEM196_PRESSURE_CHANGE_BMS06 3 "DEM_INVALID" 2 "DEM_FAILED" 1 "DEM_PASSED" 0 "DEM_NOTTESTED" ;
VAL_ 1413 DEM197_PRESSURE_OVER_BMS06 3 "DEM_INVALID" 2 "DEM_FAILED" 1 "DEM_PASSED" 0 "DEM_NOTTESTED" ;
VAL_ 1413 DEM198_PRESSURE_UNDER_BMS06 3 "DEM_INVALID" 2 "DEM_FAILED" 1 "DEM_PASSED" 0 "DEM_NOTTESTED" ;
VAL_ 1413 DEM199_PRESSURE_INVALID_BMS06 3 "DEM_INVALID" 2 "DEM_FAILED" 1 "DEM_PASSED" 0 "DEM_NOTTESTED" ;
VAL_ 1413 DEM200_THERMAL_EVENT_BMS06 3 "DEM_INVALID" 2 "DEM_FAILED" 1 "DEM_PASSED" 0 "DEM_NOTTESTED" ;
VAL_ 1413 DEM201_CMB_ONBOARDT_SNA_BMS06 3 "DEM_INVALID" 2 "DEM_FAILED" 1 "DEM_PASSED" 0 "DEM_NOTTESTED" ;
VAL_ 1413 DEM202_REPLACE_DESICCANT_BMS06 3 "DEM_INVALID" 2 "DEM_FAILED" 1 "DEM_PASSED" 0 "DEM_NOTTESTED" ;
VAL_ 1413 DEM203_COOLANT_FLOOD_FAULT_BMS06 3 "DEM_INVALID" 2 "DEM_FAILED" 1 "DEM_PASSED" 0 "DEM_NOTTESTED" ;
VAL_ 1413 DEM204_LOW_BRICKCAPACITY_BMS06 3 "DEM_INVALID" 2 "DEM_FAILED" 1 "DEM_PASSED" 0 "DEM_NOTTESTED" ;
VAL_ 1413 DEM205_BMS_ONBOARDT_OT_BMS06 3 "DEM_INVALID" 2 "DEM_FAILED" 1 "DEM_PASSED" 0 "DEM_NOTTESTED" ;
VAL_ 1413 DEM206_HUMIDITY_CHANGE_BMS06 3 "DEM_INVALID" 2 "DEM_FAILED" 1 "DEM_PASSED" 0 "DEM_NOTTESTED" ;
VAL_ 1413 DEM207_ISENSE_SUPPLY_CURR_BMS06 3 "DEM_INVALID" 2 "DEM_FAILED" 1 "DEM_PASSED" 0 "DEM_NOTTESTED" ;
VAL_ 1413 DEM208_SOC_LOW_BMS06 3 "DEM_INVALID" 2 "DEM_FAILED" 1 "DEM_PASSED" 0 "DEM_NOTTESTED" ;
VAL_ 1413 DEM209_SOC_TOOLOW_BMS06 3 "DEM_INVALID" 2 "DEM_FAILED" 1 "DEM_PASSED" 0 "DEM_NOTTESTED" ;
VAL_ 1413 DEM210_SOC_TOOHIGH_BMS06 3 "DEM_INVALID" 2 "DEM_FAILED" 1 "DEM_PASSED" 0 "DEM_NOTTESTED" ;
VAL_ 1413 DEM211_BALANCING_REQUIRED_BMS06 3 "DEM_INVALID" 2 "DEM_FAILED" 1 "DEM_PASSED" 0 "DEM_NOTTESTED" ;
VAL_ 1413 DEM212_DEEP_DISCHARGE_BMS06 3 "DEM_INVALID" 2 "DEM_FAILED" 1 "DEM_PASSED" 0 "DEM_NOTTESTED" ;
VAL_ 1413 DEM213_CAN1_BUS_OFF_BMS06 3 "DEM_INVALID" 2 "DEM_FAILED" 1 "DEM_PASSED" 0 "DEM_NOTTESTED" ;
VAL_ 1413 DEM214_CAN2_BUS_OFF_BMS06 3 "DEM_INVALID" 2 "DEM_FAILED" 1 "DEM_PASSED" 0 "DEM_NOTTESTED" ;
VAL_ 1413 DEM215_CAN3_BUS_OFF_BMS06 3 "DEM_INVALID" 2 "DEM_FAILED" 1 "DEM_PASSED" 0 "DEM_NOTTESTED" ;
VAL_ 1413 DEM216_OUTLET_NTC_RATNAL_BMS06 3 "DEM_INVALID" 2 "DEM_FAILED" 1 "DEM_PASSED" 0 "DEM_NOTTESTED" ;
VAL_ 1413 DEM217_FUSE_PACK_BMS06 3 "DEM_INVALID" 2 "DEM_FAILED" 1 "DEM_PASSED" 0 "DEM_NOTTESTED" ;
VAL_ 1413 DEM218_FUSE_B_OPEN_BMS06 3 "DEM_INVALID" 2 "DEM_FAILED" 1 "DEM_PASSED" 0 "DEM_NOTTESTED" ;
VAL_ 1413 DEM219_FUSE_C_OPEN_BMS06 3 "DEM_INVALID" 2 "DEM_FAILED" 1 "DEM_PASSED" 0 "DEM_NOTTESTED" ;
VAL_ 1413 DEM220_FUSE_D_OPEN_BMS06 3 "DEM_INVALID" 2 "DEM_FAILED" 1 "DEM_PASSED" 0 "DEM_NOTTESTED" ;
VAL_ 1413 DEM221_FUSE_E_OPEN_BMS06 3 "DEM_INVALID" 2 "DEM_FAILED" 1 "DEM_PASSED" 0 "DEM_NOTTESTED" ;
VAL_ 1413 DEM222_PUMP_DRY_RUN_BMS06 3 "DEM_INVALID" 2 "DEM_FAILED" 1 "DEM_PASSED" 0 "DEM_NOTTESTED" ;
VAL_ 1413 DEM223_PUMP_PERFORMANCE_BMS06 3 "DEM_INVALID" 2 "DEM_FAILED" 1 "DEM_PASSED" 0 "DEM_NOTTESTED" ;
VAL_ 1477 DEM224_PUMP_LIN_FAILURE_BMS06 3 "DEM_INVALID" 2 "DEM_FAILED" 1 "DEM_PASSED" 0 "DEM_NOTTESTED" ;
VAL_ 1477 DEM225_PUMP_SUPPLY_VOLTAGE_BMS06 3 "DEM_INVALID" 2 "DEM_FAILED" 1 "DEM_PASSED" 0 "DEM_NOTTESTED" ;
VAL_ 1477 DEM226_PUMP_RECOVERY_FAIL_BMS06 3 "DEM_INVALID" 2 "DEM_FAILED" 1 "DEM_PASSED" 0 "DEM_NOTTESTED" ;
VAL_ 1477 DEM227_CTR_POS_OPENED_BMS06 3 "DEM_INVALID" 2 "DEM_FAILED" 1 "DEM_PASSED" 0 "DEM_NOTTESTED" ;
VAL_ 1477 DEM228_CTR_NEG_OPENED_BMS06 3 "DEM_INVALID" 2 "DEM_FAILED" 1 "DEM_PASSED" 0 "DEM_NOTTESTED" ;
VAL_ 1477 DEM229_STRSET_SLAVE1_FAULT_BMS06 3 "DEM_INVALID" 2 "DEM_FAILED" 1 "DEM_PASSED" 0 "DEM_NOTTESTED" ;
VAL_ 1477 DEM230_STRSET_SLAVE2_FAULT_BMS06 3 "DEM_INVALID" 2 "DEM_FAILED" 1 "DEM_PASSED" 0 "DEM_NOTTESTED" ;
VAL_ 1477 DEM231_CTRSAUX_CLFAIL_HVON_BMS06 3 "DEM_INVALID" 2 "DEM_FAILED" 1 "DEM_PASSED" 0 "DEM_NOTTESTED" ;
VAL_ 1477 DEM232_CTRSAUX_CLFAIL_VDIF_BMS06 3 "DEM_INVALID" 2 "DEM_FAILED" 1 "DEM_PASSED" 0 "DEM_NOTTESTED" ;
VAL_ 1477 DEM233_CTRSAUX_POS1_OPENED_BMS06 3 "DEM_INVALID" 2 "DEM_FAILED" 1 "DEM_PASSED" 0 "DEM_NOTTESTED" ;
VAL_ 1477 DEM234_CTRSAUX_NEG1_OPENED_BMS06 3 "DEM_INVALID" 2 "DEM_FAILED" 1 "DEM_PASSED" 0 "DEM_NOTTESTED" ;
VAL_ 1477 DEM235_CTRSAUX_POS1_WELDED_BMS06 3 "DEM_INVALID" 2 "DEM_FAILED" 1 "DEM_PASSED" 0 "DEM_NOTTESTED" ;
VAL_ 1477 DEM236_CTRSAUX_NEG1_WELDED_BMS06 3 "DEM_INVALID" 2 "DEM_FAILED" 1 "DEM_PASSED" 0 "DEM_NOTTESTED" ;
VAL_ 1477 DEM237_CTRSAUX_POS1_PULLIN_BMS06 3 "DEM_INVALID" 2 "DEM_FAILED" 1 "DEM_PASSED" 0 "DEM_NOTTESTED" ;
VAL_ 1477 DEM238_CTRSAUX_NEG1_PULLIN_BMS06 3 "DEM_INVALID" 2 "DEM_FAILED" 1 "DEM_PASSED" 0 "DEM_NOTTESTED" ;
VAL_ 1477 DEM239_INLET_NTC_RATNAL_BMS06 3 "DEM_INVALID" 2 "DEM_FAILED" 1 "DEM_PASSED" 0 "DEM_NOTTESTED" ;
VAL_ 1477 DEM240_INLET_NTC_HI_BMS06 3 "DEM_INVALID" 2 "DEM_FAILED" 1 "DEM_PASSED" 0 "DEM_NOTTESTED" ;
VAL_ 1477 DEM241_INLET_NTC_LO_BMS06 3 "DEM_INVALID" 2 "DEM_FAILED" 1 "DEM_PASSED" 0 "DEM_NOTTESTED" ;
VAL_ 1477 DEM242_VOLTAGE_LINK2_RATNA_BMS06 3 "DEM_INVALID" 2 "DEM_FAILED" 1 "DEM_PASSED" 0 "DEM_NOTTESTED" ;
VAL_ 1477 DEM243_VOLTAGE_LINK2_HI_BMS06 3 "DEM_INVALID" 2 "DEM_FAILED" 1 "DEM_PASSED" 0 "DEM_NOTTESTED" ;
VAL_ 1477 DEM244_VOLTAGE_LINK2_LO_BMS06 3 "DEM_INVALID" 2 "DEM_FAILED" 1 "DEM_PASSED" 0 "DEM_NOTTESTED" ;
VAL_ 1477 DEM245_CMB_ONBOARD_IMPOSSI_BMS06 3 "DEM_INVALID" 2 "DEM_FAILED" 1 "DEM_PASSED" 0 "DEM_NOTTESTED" ;
VAL_ 1477 DEM246_VOLTAGE_LINK1_HI_BMS06 3 "DEM_INVALID" 2 "DEM_FAILED" 1 "DEM_PASSED" 0 "DEM_NOTTESTED" ;
VAL_ 1477 DEM247_VOLTAGE_LINK1_LO_BMS06 3 "DEM_INVALID" 2 "DEM_FAILED" 1 "DEM_PASSED" 0 "DEM_NOTTESTED" ;
VAL_ 1477 DEM248_NTC_SUPPLY_LO_BMS06 3 "DEM_INVALID" 2 "DEM_FAILED" 1 "DEM_PASSED" 0 "DEM_NOTTESTED" ;
VAL_ 1477 DEM249_NTC_SUPPLY_HI_BMS06 3 "DEM_INVALID" 2 "DEM_FAILED" 1 "DEM_PASSED" 0 "DEM_NOTTESTED" ;
VAL_ 1477 DEM250_VOLTAGE_LINK3_RATNA_BMS06 3 "DEM_INVALID" 2 "DEM_FAILED" 1 "DEM_PASSED" 0 "DEM_NOTTESTED" ;
VAL_ 1477 DEM251_VOLTAGE_LINK3_HI_BMS06 3 "DEM_INVALID" 2 "DEM_FAILED" 1 "DEM_PASSED" 0 "DEM_NOTTESTED" ;
VAL_ 1477 DEM252_VOLTAGE_LINK3_LO_BMS06 3 "DEM_INVALID" 2 "DEM_FAILED" 1 "DEM_PASSED" 0 "DEM_NOTTESTED" ;
VAL_ 1477 DEM253_BALANCING_STUCK_BMS06 3 "DEM_INVALID" 2 "DEM_FAILED" 1 "DEM_PASSED" 0 "DEM_NOTTESTED" ;
VAL_ 1477 DEM254_ARM_EXCEPTION_BMS06 3 "DEM_INVALID" 2 "DEM_FAILED" 1 "DEM_PASSED" 0 "DEM_NOTTESTED" ;
VAL_ 1477 DEM255_ERROR_HOOKS_BMS06 3 "DEM_INVALID" 2 "DEM_FAILED" 1 "DEM_PASSED" 0 "DEM_NOTTESTED" ;
VAL_ 837 DEM256_XCP_CAL_CHANGE_BMS06 3 "DEM_INVALID" 2 "DEM_FAILED" 1 "DEM_PASSED" 0 "DEM_NOTTESTED" ;
VAL_ 837 DEM257_XCP_CAL_PERM_CHANGE_BMS06 3 "DEM_INVALID" 2 "DEM_FAILED" 1 "DEM_PASSED" 0 "DEM_NOTTESTED" ;
VAL_ 837 DEM258_TASK_TIME_OVERFLOW_BMS06 3 "DEM_INVALID" 2 "DEM_FAILED" 1 "DEM_PASSED" 0 "DEM_NOTTESTED" ;
VAL_ 837 DEM259_ISO_CIRCUIT_BMS06 3 "DEM_INVALID" 2 "DEM_FAILED" 1 "DEM_PASSED" 0 "DEM_NOTTESTED" ;
VAL_ 837 DEM260_COOLANT_MOIST_FAULT_BMS06 3 "DEM_INVALID" 2 "DEM_FAILED" 1 "DEM_PASSED" 0 "DEM_NOTTESTED" ;
VAL_ 837 DEM261_COOLANT_FLOOD_WARN_BMS06 3 "DEM_INVALID" 2 "DEM_FAILED" 1 "DEM_PASSED" 0 "DEM_NOTTESTED" ;
VAL_ 837 DEM262_COOLANT_MOIST_WARN_BMS06 3 "DEM_INVALID" 2 "DEM_FAILED" 1 "DEM_PASSED" 0 "DEM_NOTTESTED" ;
VAL_ 837 DEM263_MODULET_IMPLAUSIBLE_BMS06 3 "DEM_INVALID" 2 "DEM_FAILED" 1 "DEM_PASSED" 0 "DEM_NOTTESTED" ;
VAL_ 837 DEM264_REQUEST_ON_WITH_HV__BMS06 3 "DEM_INVALID" 2 "DEM_FAILED" 1 "DEM_PASSED" 0 "DEM_NOTTESTED" ;
VAL_ 837 DEM265_CSERS_PCODE_BMS06 3 "DEM_INVALID" 2 "DEM_FAILED" 1 "DEM_PASSED" 0 "DEM_NOTTESTED" ;
VAL_ 837 DEM266_PRELIM_CNTR_CL_FAIL_BMS06 3 "DEM_INVALID" 2 "DEM_FAILED" 1 "DEM_PASSED" 0 "DEM_NOTTESTED" ;
VAL_ 837 DEM267_FLUIDLVL_LOW_BMS06 3 "DEM_INVALID" 2 "DEM_FAILED" 1 "DEM_PASSED" 0 "DEM_NOTTESTED" ;
VAL_ 837 DEM268_FLUIDLVL_FAILURE_BMS06 3 "DEM_INVALID" 2 "DEM_FAILED" 1 "DEM_PASSED" 0 "DEM_NOTTESTED" ;
VAL_ 837 DEM269_SC_COOLANT_CONTAM_BMS06 3 "DEM_INVALID" 2 "DEM_FAILED" 1 "DEM_PASSED" 0 "DEM_NOTTESTED" ;
VAL_ 837 DEM270_SC_COOLANT_MIA_BMS06 3 "DEM_INVALID" 2 "DEM_FAILED" 1 "DEM_PASSED" 0 "DEM_NOTTESTED" ;
VAL_ 837 DEM271_PRESSURE_VHI_BMS06 3 "DEM_INVALID" 2 "DEM_FAILED" 1 "DEM_PASSED" 0 "DEM_NOTTESTED" ;
VAL_ 837 DEM272_PRESSURE_VLO_BMS06 3 "DEM_INVALID" 2 "DEM_FAILED" 1 "DEM_PASSED" 0 "DEM_NOTTESTED" ;
VAL_ 837 DEM273_SC_COOLANT_FAIL_BMS06 3 "DEM_INVALID" 2 "DEM_FAILED" 1 "DEM_PASSED" 0 "DEM_NOTTESTED" ;
VAL_ 837 DEM274_CTRSAUX_POS2_OPENED_BMS06 3 "DEM_INVALID" 2 "DEM_FAILED" 1 "DEM_PASSED" 0 "DEM_NOTTESTED" ;
VAL_ 837 DEM275_CTRSAUX_POS3_OPENED_BMS06 3 "DEM_INVALID" 2 "DEM_FAILED" 1 "DEM_PASSED" 0 "DEM_NOTTESTED" ;
VAL_ 837 DEM276_CTRSAUX_POS2_WELDED_BMS06 3 "DEM_INVALID" 2 "DEM_FAILED" 1 "DEM_PASSED" 0 "DEM_NOTTESTED" ;
VAL_ 837 DEM277_CTRSAUX_POS3_WELDED_BMS06 3 "DEM_INVALID" 2 "DEM_FAILED" 1 "DEM_PASSED" 0 "DEM_NOTTESTED" ;
VAL_ 837 DEM278_CTRSAUX_POS2_PULLIN_BMS06 3 "DEM_INVALID" 2 "DEM_FAILED" 1 "DEM_PASSED" 0 "DEM_NOTTESTED" ;
VAL_ 837 DEM279_CTRSAUX_POS3_PULLIN_BMS06 3 "DEM_INVALID" 2 "DEM_FAILED" 1 "DEM_PASSED" 0 "DEM_NOTTESTED" ;
VAL_ 837 DEM280_CMB_HUMIDITY_TEMP_C_BMS06 3 "DEM_INVALID" 2 "DEM_FAILED" 1 "DEM_PASSED" 0 "DEM_NOTTESTED" ;
VAL_ 837 DEM281_THERMAL_EVENT_CMB_R_BMS06 3 "DEM_INVALID" 2 "DEM_FAILED" 1 "DEM_PASSED" 0 "DEM_NOTTESTED" ;
VAL_ 837 DEM282_CUS_BRICKOV_BMS06 3 "DEM_INVALID" 2 "DEM_FAILED" 1 "DEM_PASSED" 0 "DEM_NOTTESTED" ;
VAL_ 837 DEM283_CUS_BRICKUV_BMS06 3 "DEM_INVALID" 2 "DEM_FAILED" 1 "DEM_PASSED" 0 "DEM_NOTTESTED" ;
VAL_ 837 DEM284_CUS_OVERCHRG_BMS06 3 "DEM_INVALID" 2 "DEM_FAILED" 1 "DEM_PASSED" 0 "DEM_NOTTESTED" ;
VAL_ 837 DEM285_CUS_OVERDCHRG_BMS06 3 "DEM_INVALID" 2 "DEM_FAILED" 1 "DEM_PASSED" 0 "DEM_NOTTESTED" ;
VAL_ 837 DEM286_CUS_CURRENT_CHG_BMS06 3 "DEM_INVALID" 2 "DEM_FAILED" 1 "DEM_PASSED" 0 "DEM_NOTTESTED" ;
VAL_ 837 DEM287_CUS_CURRENT_DCHG_BMS06 3 "DEM_INVALID" 2 "DEM_FAILED" 1 "DEM_PASSED" 0 "DEM_NOTTESTED" ;
